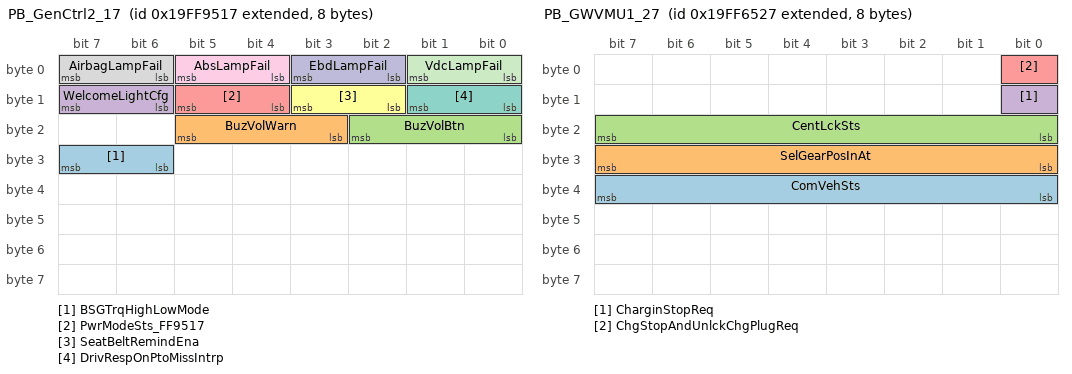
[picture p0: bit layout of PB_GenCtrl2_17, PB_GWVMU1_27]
BO_ 2583663895 PB_GenCtrl2_17: 8 ICC
 SG_ BSGTrqHighLowMode : 30|2@1+ (1,0) [0|3] ""  PCM
 SG_ BuzVolWarn : 19|3@1+ (1,0) [0|7] ""  PCM
 SG_ BuzVolBtn : 16|3@1+ (1,0) [0|7] ""  PCM
 SG_ WelcomeLightCfg : 14|2@1+ (1,0) [0|3] ""  PCM
 SG_ PwrModeSts_FF9517 : 12|2@1+ (1,0) [0|3] ""  PCM
 SG_ SeatBeltRemindEna : 10|2@1+ (1,0) [0|3] ""  PCM
 SG_ DrivRespOnPtoMissIntrp : 8|2@1+ (1,0) [0|3] ""  PCM
 SG_ AirbagLampFail : 6|2@1+ (1,0) [0|3] ""  PCM
 SG_ AbsLampFail : 4|2@1+ (1,0) [0|3] ""  PCM
 SG_ EbdLampFail : 2|2@1+ (1,0) [0|3] ""  PCM
 SG_ VdcLampFail : 0|2@1+ (1,0) [0|3] ""  PCM

BO_ 2583651623 PB_GWVMU1_27: 8 VCM
 SG_ ComVehSts : 32|8@1+ (1,0) [0|255] ""  PCM
 SG_ SelGearPosInAt : 24|8@1+ (1,0) [0|255] ""  PCM
 SG_ CentLckSts : 16|8@1+ (1,0) [0|255] ""  PCM
 SG_ CharginStopReq : 8|1@1+ (1,0) [0|1] ""  PCM
 SG_ ChgStopAndUnlckChgPlugReq : 0|1@1+ (1,0) [0|1] ""  PCM

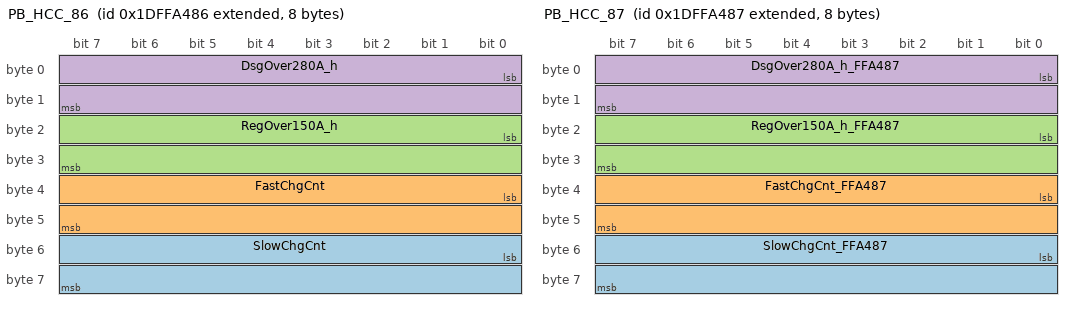
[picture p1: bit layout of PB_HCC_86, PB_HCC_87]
BO_ 2650776710 PB_HCC_86: 8 NODE_86
 SG_ SlowChgCnt : 48|16@1+ (1,0) [0|65535] ""  PCM
 SG_ FastChgCnt : 32|16@1+ (1,0) [0|65535] ""  PCM
 SG_ RegOver150A_h : 16|16@1+ (1,0) [0|65535] "h"  PCM
 SG_ DsgOver280A_h : 0|16@1+ (1,0) [0|65535] "h"  PCM

BO_ 2650776711 PB_HCC_87: 8 NODE_87
 SG_ SlowChgCnt_FFA487 : 48|16@1+ (1,0) [0|65535] ""  PCM
 SG_ FastChgCnt_FFA487 : 32|16@1+ (1,0) [0|65535] ""  PCM
 SG_ RegOver150A_h_FFA487 : 16|16@1+ (1,0) [0|65535] "h"  PCM
 SG_ DsgOver280A_h_FFA487 : 0|16@1+ (1,0) [0|65535] "h"  PCM

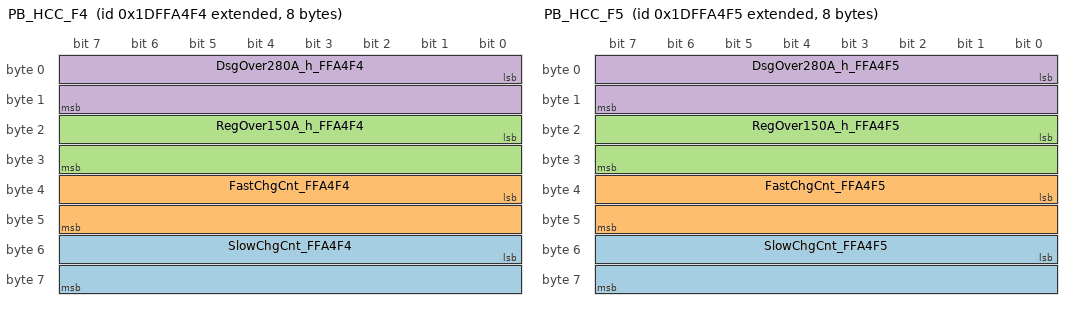
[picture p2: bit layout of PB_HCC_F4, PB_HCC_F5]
BO_ 2650776820 PB_HCC_F4: 8 NODE_F4
 SG_ SlowChgCnt_FFA4F4 : 48|16@1+ (1,0) [0|65535] ""  PCM
 SG_ FastChgCnt_FFA4F4 : 32|16@1+ (1,0) [0|65535] ""  PCM
 SG_ RegOver150A_h_FFA4F4 : 16|16@1+ (1,0) [0|65535] "h"  PCM
 SG_ DsgOver280A_h_FFA4F4 : 0|16@1+ (1,0) [0|65535] "h"  PCM

BO_ 2650776821 PB_HCC_F5: 8 NODE_F5
 SG_ SlowChgCnt_FFA4F5 : 48|16@1+ (1,0) [0|65535] ""  PCM
 SG_ FastChgCnt_FFA4F5 : 32|16@1+ (1,0) [0|65535] ""  PCM
 SG_ RegOver150A_h_FFA4F5 : 16|16@1+ (1,0) [0|65535] "h"  PCM
 SG_ DsgOver280A_h_FFA4F5 : 0|16@1+ (1,0) [0|65535] "h"  PCM

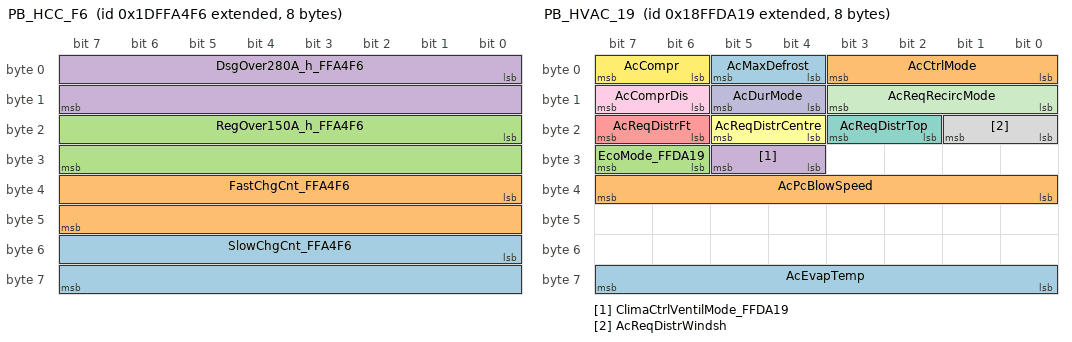
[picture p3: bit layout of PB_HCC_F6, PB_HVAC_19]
BO_ 2650776822 PB_HCC_F6: 8 NODE_F6
 SG_ SlowChgCnt_FFA4F6 : 48|16@1+ (1,0) [0|65535] ""  PCM
 SG_ FastChgCnt_FFA4F6 : 32|16@1+ (1,0) [0|65535] ""  PCM
 SG_ RegOver150A_h_FFA4F6 : 16|16@1+ (1,0) [0|65535] "h"  PCM
 SG_ DsgOver280A_h_FFA4F6 : 0|16@1+ (1,0) [0|65535] "h"  PCM

BO_ 2566904343 PB_HVAC_17: 8 ICC
 SG_ EcoMode_FFDA17 : 30|2@1+ (1,0) [0|3] ""  PCM

BO_ 2566904345 PB_HVAC_19: 8 ACM
 SG_ AcEvapTemp : 56|8@1+ (1,-40) [-40|210] "�C"  PCM
 SG_ AcPcBlowSpeed : 32|8@1+ (0.4,0) [0|100] "%"  PCM
 SG_ EcoMode_FFDA19 : 30|2@1+ (1,0) [0|3] ""  PCM
 SG_ ClimaCtrlVentilMode_FFDA19 : 28|2@1+ (1,0) [0|3] ""  PCM
 SG_ AcReqDistrFt : 22|2@1+ (1,0) [0|3] ""  PCM
 SG_ AcReqDistrCentre : 20|2@1+ (1,0) [0|3] ""  PCM
 SG_ AcReqDistrTop : 18|2@1+ (1,0) [0|3] ""  PCM
 SG_ AcReqDistrWindsh : 16|2@1+ (1,0) [0|3] ""  PCM
 SG_ AcComprDis : 14|2@1+ (1,0) [0|3] ""  PCM
 SG_ AcDurMode : 12|2@1+ (1,0) [0|3] ""  PCM
 SG_ AcReqRecircMode : 8|4@1+ (1,0) [0|15] ""  PCM
 SG_ AcCompr : 6|2@1+ (1,0) [0|3] ""  PCM
 SG_ AcMaxDefrost : 4|2@1+ (1,0) [0|3] ""  PCM
 SG_ AcCtrlMode : 0|4@1+ (1,0) [0|15] ""  PCM

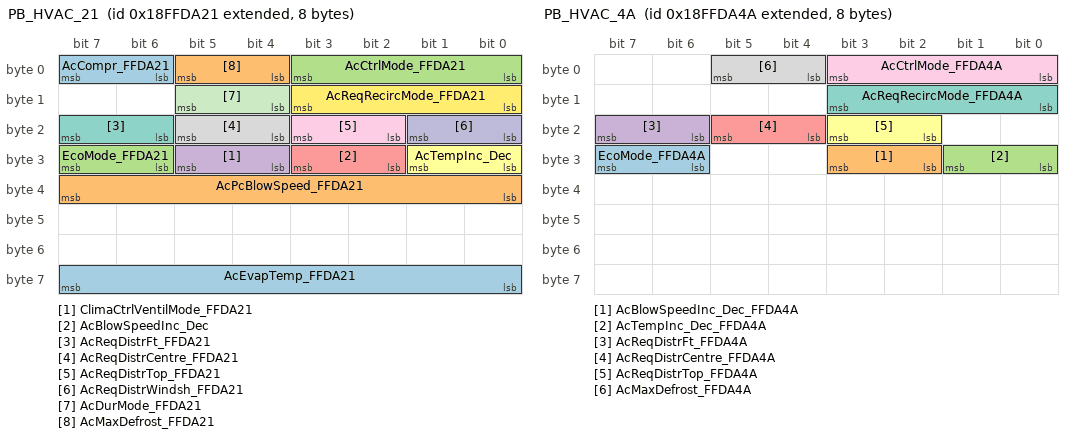
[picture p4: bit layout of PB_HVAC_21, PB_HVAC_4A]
BO_ 2566904353 PB_HVAC_21: 8 BCM
 SG_ AcEvapTemp_FFDA21 : 56|8@1+ (1,-40) [-40|210] "�C"  PCM
 SG_ AcPcBlowSpeed_FFDA21 : 32|8@1+ (0.4,0) [0|100] "%"  PCM
 SG_ EcoMode_FFDA21 : 30|2@1+ (1,0) [0|3] ""  PCM
 SG_ ClimaCtrlVentilMode_FFDA21 : 28|2@1+ (1,0) [0|3] ""  PCM
 SG_ AcBlowSpeedInc_Dec : 26|2@1+ (1,0) [0|3] ""  PCM
 SG_ AcTempInc_Dec : 24|2@1+ (1,0) [0|3] ""  PCM
 SG_ AcReqDistrFt_FFDA21 : 22|2@1+ (1,0) [0|3] ""  PCM
 SG_ AcReqDistrCentre_FFDA21 : 20|2@1+ (1,0) [0|3] ""  PCM
 SG_ AcReqDistrTop_FFDA21 : 18|2@1+ (1,0) [0|3] ""  PCM
 SG_ AcReqDistrWindsh_FFDA21 : 16|2@1+ (1,0) [0|3] ""  PCM
 SG_ AcDurMode_FFDA21 : 12|2@1+ (1,0) [0|3] ""  PCM
 SG_ AcReqRecircMode_FFDA21 : 8|4@1+ (1,0) [0|15] ""  PCM
 SG_ AcCompr_FFDA21 : 6|2@1+ (1,0) [0|3] ""  PCM
 SG_ AcMaxDefrost_FFDA21 : 4|2@1+ (1,0) [0|3] ""  PCM
 SG_ AcCtrlMode_FFDA21 : 0|4@1+ (1,0) [0|15] ""  PCM

BO_ 2566904394 PB_HVAC_4A: 8 PCM
 SG_ EcoMode_FFDA4A : 30|2@1+ (1,0) [0|3] "" Vector__XXX
 SG_ AcBlowSpeedInc_Dec_FFDA4A : 26|2@1+ (1,0) [0|3] "" Vector__XXX
 SG_ AcTempInc_Dec_FFDA4A : 24|2@1+ (1,0) [0|3] "" Vector__XXX
 SG_ AcReqDistrFt_FFDA4A : 22|2@1+ (1,0) [0|3] "" Vector__XXX
 SG_ AcReqDistrCentre_FFDA4A : 20|2@1+ (1,0) [0|3] "" Vector__XXX
 SG_ AcReqDistrTop_FFDA4A : 18|2@1+ (1,0) [0|3] "" Vector__XXX
 SG_ AcReqRecircMode_FFDA4A : 8|4@1+ (1,0) [0|15] "" Vector__XXX
 SG_ AcMaxDefrost_FFDA4A : 4|2@1+ (1,0) [0|3] "" Vector__XXX
 SG_ AcCtrlMode_FFDA4A : 0|4@1+ (1,0) [0|15] "" Vector__XXX

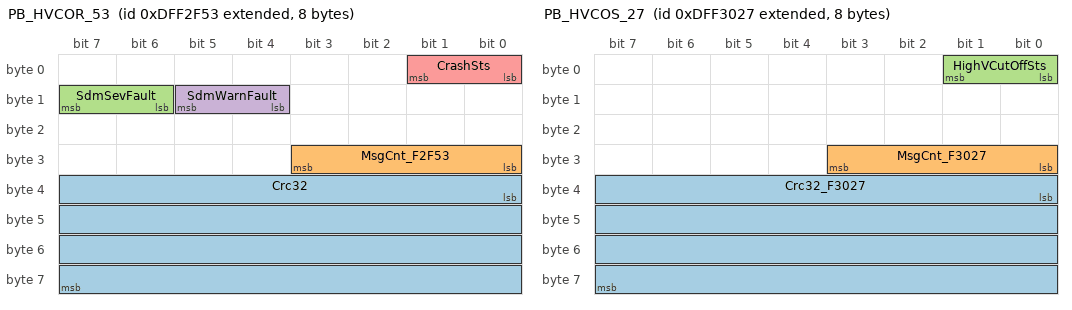
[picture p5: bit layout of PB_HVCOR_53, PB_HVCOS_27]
BO_ 2382311251 PB_HVCOR_53: 8 Airbag
 SG_ Crc32 : 32|32@1+ (1,0) [0|4294967295] ""  PCM
 SG_ MsgCnt_F2F53 : 24|4@1+ (1,0) [0|15] "count"  PCM
 SG_ SdmSevFault : 14|2@1+ (1,0) [0|3] ""  PCM
 SG_ SdmWarnFault : 12|2@1+ (1,0) [0|3] ""  PCM
 SG_ CrashSts : 0|2@1+ (1,0) [0|3] ""  PCM

BO_ 2382311463 PB_HVCOS_27: 8 VCM
 SG_ Crc32_F3027 : 32|32@1+ (1,0) [0|4294967295] ""  PCM
 SG_ MsgCnt_F3027 : 24|4@1+ (1,0) [0|15] "count"  PCM
 SG_ HighVCutOffSts : 0|2@1+ (1,0) [0|3] ""  PCM

BO_ 2650750195 PB_HVESSCFG_F3: 25 NODE_F3
 SG_ Crc32_FF3CF3 : 168|32@1+ (1,0) [0|4294967295] ""  PCM
 SG_ MsgCnt8 : 160|8@1+ (1,0) [0|255] "count"  PCM
 SG_ HvessCellVminLim : 120|8@1+ (0.02044,0) [0|5.11] "V"  PCM
 SG_ HvessCellVmaxLim : 112|8@1+ (0.02044,0) [0|5.11] "V"  PCM
 SG_ HvessRecomMinOpTemp : 96|16@1+ (0.03125,-273) [-273|1734.96875] "�C"  PCM
 SG_ HvessRecomMaxOpTemp : 80|16@1+ (0.03125,-273) [-273|1734.96875] "�C"  PCM
 SG_ HvessRecomMaxSoc : 64|16@1+ (0.0015625,0) [0|100.3984375] "%"  PCM
 SG_ HvessRecomMinSoc : 48|16@1+ (0.0015625,0) [0|100.3984375] "%"  PCM
 SG_ HvessRecomMaxOpV : 32|16@1+ (0.05,0) [0|3212.75] "V"  PCM
 SG_ HvessRecomMinOpV : 16|16@1+ (0.05,0) [0|3212.75] "V"  PCM
 SG_ HvessNomV : 0|16@1+ (0.05,0) [0|3212.75] "V"  PCM

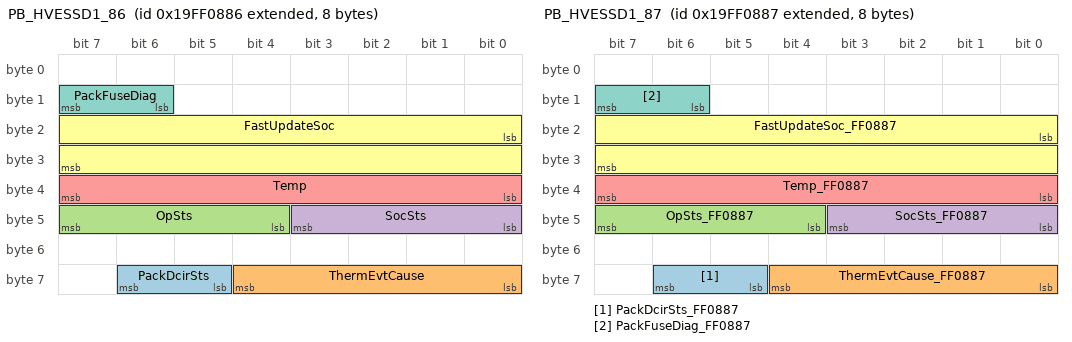
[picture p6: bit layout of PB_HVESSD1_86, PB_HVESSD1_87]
BO_ 2583627910 PB_HVESSD1_86: 8 NODE_86
 SG_ PackDcirSts : 61|2@1+ (1,0) [0|3] ""  PCM
 SG_ ThermEvtCause : 56|5@1+ (1,0) [0|31] ""  PCM
 SG_ OpSts : 44|4@1+ (1,0) [0|15] ""  PCM
 SG_ SocSts : 40|4@1+ (1,0) [0|15] ""  PCM
 SG_ Temp : 32|8@1+ (1,-40) [-40|210] "�C"  PCM
 SG_ FastUpdateSoc : 16|16@1+ (0.0015625,0) [0|100.3984375] "%"  PCM
 SG_ PackFuseDiag : 14|2@1+ (1,0) [0|3] ""  PCM

BO_ 2583627911 PB_HVESSD1_87: 8 NODE_87
 SG_ PackDcirSts_FF0887 : 61|2@1+ (1,0) [0|3] ""  PCM
 SG_ ThermEvtCause_FF0887 : 56|5@1+ (1,0) [0|31] ""  PCM
 SG_ OpSts_FF0887 : 44|4@1+ (1,0) [0|15] ""  PCM
 SG_ SocSts_FF0887 : 40|4@1+ (1,0) [0|15] ""  PCM
 SG_ Temp_FF0887 : 32|8@1+ (1,-40) [-40|210] "�C"  PCM
 SG_ FastUpdateSoc_FF0887 : 16|16@1+ (0.0015625,0) [0|100.3984375] "%"  PCM
 SG_ PackFuseDiag_FF0887 : 14|2@1+ (1,0) [0|3] ""  PCM

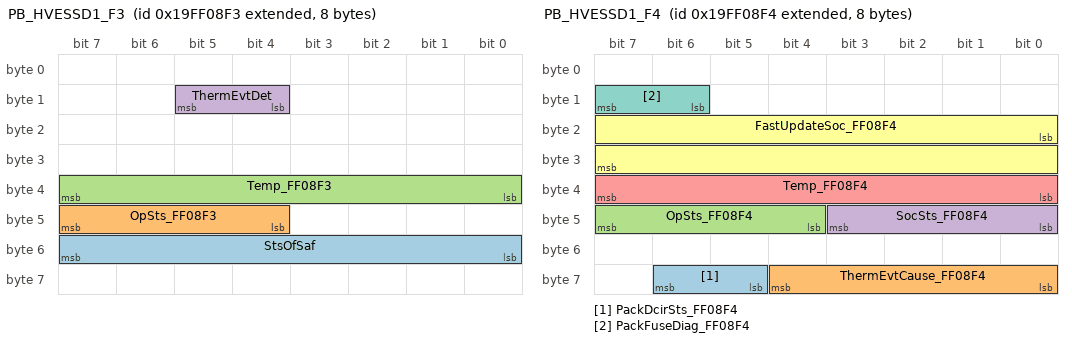
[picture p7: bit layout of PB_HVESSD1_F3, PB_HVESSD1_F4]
BO_ 2583628019 PB_HVESSD1_F3: 8 NODE_F3
 SG_ StsOfSaf : 48|8@1+ (0.4,0) [0|100] "%"  PCM
 SG_ OpSts_FF08F3 : 44|4@1+ (1,0) [0|15] ""  PCM
 SG_ Temp_FF08F3 : 32|8@1+ (1,-40) [-40|210] "�C"  PCM
 SG_ ThermEvtDet : 12|2@1+ (1,0) [0|3] ""  PCM

BO_ 2583628020 PB_HVESSD1_F4: 8 NODE_F4
 SG_ PackDcirSts_FF08F4 : 61|2@1+ (1,0) [0|3] ""  PCM
 SG_ ThermEvtCause_FF08F4 : 56|5@1+ (1,0) [0|31] ""  PCM
 SG_ OpSts_FF08F4 : 44|4@1+ (1,0) [0|15] ""  PCM
 SG_ SocSts_FF08F4 : 40|4@1+ (1,0) [0|15] ""  PCM
 SG_ Temp_FF08F4 : 32|8@1+ (1,-40) [-40|210] "�C"  PCM
 SG_ FastUpdateSoc_FF08F4 : 16|16@1+ (0.0015625,0) [0|100.3984375] "%"  PCM
 SG_ PackFuseDiag_FF08F4 : 14|2@1+ (1,0) [0|3] ""  PCM

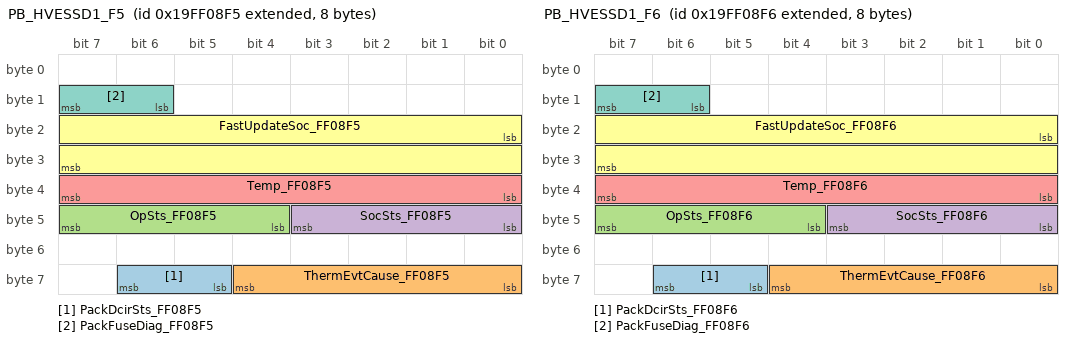
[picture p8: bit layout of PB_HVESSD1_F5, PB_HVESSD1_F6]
BO_ 2583628021 PB_HVESSD1_F5: 8 NODE_F5
 SG_ PackDcirSts_FF08F5 : 61|2@1+ (1,0) [0|3] ""  PCM
 SG_ ThermEvtCause_FF08F5 : 56|5@1+ (1,0) [0|31] ""  PCM
 SG_ OpSts_FF08F5 : 44|4@1+ (1,0) [0|15] ""  PCM
 SG_ SocSts_FF08F5 : 40|4@1+ (1,0) [0|15] ""  PCM
 SG_ Temp_FF08F5 : 32|8@1+ (1,-40) [-40|210] "�C"  PCM
 SG_ FastUpdateSoc_FF08F5 : 16|16@1+ (0.0015625,0) [0|100.3984375] "%"  PCM
 SG_ PackFuseDiag_FF08F5 : 14|2@1+ (1,0) [0|3] ""  PCM

BO_ 2583628022 PB_HVESSD1_F6: 8 NODE_F6
 SG_ PackDcirSts_FF08F6 : 61|2@1+ (1,0) [0|3] ""  PCM
 SG_ ThermEvtCause_FF08F6 : 56|5@1+ (1,0) [0|31] ""  PCM
 SG_ OpSts_FF08F6 : 44|4@1+ (1,0) [0|15] ""  PCM
 SG_ SocSts_FF08F6 : 40|4@1+ (1,0) [0|15] ""  PCM
 SG_ Temp_FF08F6 : 32|8@1+ (1,-40) [-40|210] "�C"  PCM
 SG_ FastUpdateSoc_FF08F6 : 16|16@1+ (0.0015625,0) [0|100.3984375] "%"  PCM
 SG_ PackFuseDiag_FF08F6 : 14|2@1+ (1,0) [0|3] ""  PCM

BO_ 2583628275 PB_HVESSD2_F3: 8 NODE_F3
 SG_ HvessHighVBusPasIsolTestRes : 48|16@1+ (0.1,0) [0|6425.5] "ohm per V"  PCM
 SG_ HvessAvChgPwr : 32|16@1+ (0.05,0) [0|3212.75] "kW"  PCM
 SG_ HvessAvDischPwr : 16|16@1+ (0.05,0) [0|3212.75] "kW"  PCM

BO_ 2583628531 PB_HVESSD3_F3: 8 NODE_F3
 SG_ HvessCur : 32|16@1+ (0.05,-1600) [-1600|1612.75] "A"  PCM
 SG_ HvessVLev : 16|16@1+ (0.05,0) [0|3212.75] "V"  PCM

BO_ 2583628787 PB_HVESSD4_F3: 8 NODE_F3
 SG_ HvessMaxChgVLim : 48|16@1+ (0.05,0) [0|3212.75] "V"  PCM
 SG_ HvessChgCurLim : 32|16@1+ (0.05,-1600) [-1600|1612.75] "A"  PCM
 SG_ HvessDischCurLim : 16|16@1+ (0.05,-1600) [-1600|1612.75] "A"  PCM

BO_ 2583628934 PB_HVESSHIST1_86: 8 NODE_86
 SG_ Soh : 48|8@1+ (0.4,0) [0|100] "%"  PCM
 SG_ TotEnergyTput : 16|32@1+ (1000,0) [0|4211081215000] "Watt-hour"  PCM

BO_ 2583628935 PB_HVESSHIST1_87: 8 NODE_87
 SG_ Soh_FF0C87 : 48|8@1+ (0.4,0) [0|100] "%"  PCM
 SG_ TotEnergyTput_FF0C87 : 16|32@1+ (1000,0) [0|4211081215000] "Watt-hour"  PCM

BO_ 2583629043 PB_HVESSHIST1_F3: 8 NODE_F3
 SG_ Soh_FF0CF3 : 48|8@1+ (0.4,0) [0|100] "%"  PCM
 SG_ TotEnergyTput_FF0CF3 : 16|32@1+ (1000,0) [0|4211081215000] "Watt-hour"  PCM

BO_ 2583629044 PB_HVESSHIST1_F4: 8 NODE_F4
 SG_ Soh_FF0CF4 : 48|8@1+ (0.4,0) [0|100] "%"  PCM
 SG_ TotEnergyTput_FF0CF4 : 16|32@1+ (1000,0) [0|4211081215000] "Watt-hour"  PCM

BO_ 2583629045 PB_HVESSHIST1_F5: 8 NODE_F5
 SG_ Soh_FF0CF5 : 48|8@1+ (0.4,0) [0|100] "%"  PCM
 SG_ TotEnergyTput_FF0CF5 : 16|32@1+ (1000,0) [0|4211081215000] "Watt-hour"  PCM

BO_ 2583629046 PB_HVESSHIST1_F6: 8 NODE_F6
 SG_ Soh_FF0CF6 : 48|8@1+ (0.4,0) [0|100] "%"  PCM
 SG_ TotEnergyTput_FF0CF6 : 16|32@1+ (1000,0) [0|4211081215000] "Watt-hour"  PCM

BO_ 2583629190 PB_HVESSHIST2_86: 8 NODE_86
 SG_ TotAccumChg : 16|32@1+ (100,0) [0|421108121500] "Ah"  PCM

BO_ 2583629191 PB_HVESSHIST2_87: 8 NODE_87
 SG_ TotAccumChg_FF0D87 : 16|32@1+ (100,0) [0|421108121500] "Ah"  PCM

BO_ 2583629299 PB_HVESSHIST2_F3: 8 NODE_F3
 SG_ TotAccumChg_FF0DF3 : 16|32@1+ (100,0) [0|421108121500] "Ah"  PCM

BO_ 2583629300 PB_HVESSHIST2_F4: 8 NODE_F4
 SG_ TotAccumChg_FF0DF4 : 16|32@1+ (100,0) [0|421108121500] "Ah"  PCM

BO_ 2583629301 PB_HVESSHIST2_F5: 8 NODE_F5
 SG_ TotAccumChg_FF0DF5 : 16|32@1+ (100,0) [0|421108121500] "Ah"  PCM

BO_ 2583629302 PB_HVESSHIST2_F6: 8 NODE_F6
 SG_ TotAccumChg_FF0DF6 : 16|32@1+ (100,0) [0|421108121500] "Ah"  PCM

BO_ 2634014026 PB_ICPT_4A: 58 PCM
 SG_ TxtDisCharA : 16|8@1+ (1,0) [0|255] "ASCII" Vector__XXX
 SG_ TxtCharSet : 12|4@1+ (1,0) [0|15] "" Vector__XXX
 SG_ PopupIx_FFDD4A : 0|12@1+ (1,0) [0|4095] "" Vector__XXX

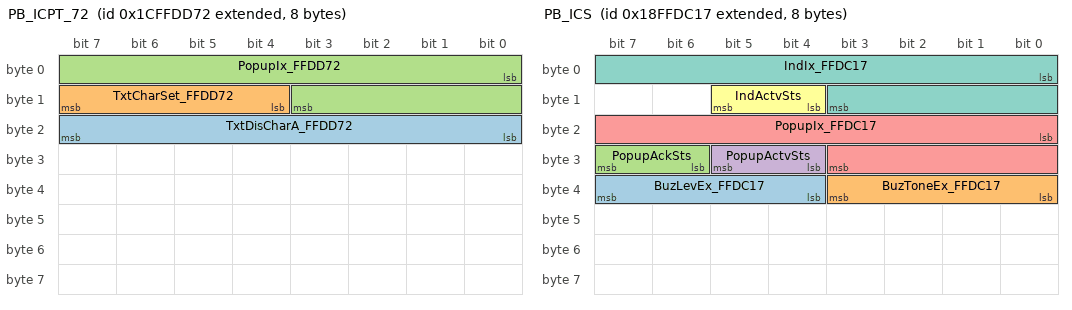
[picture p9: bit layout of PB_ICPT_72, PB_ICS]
BO_ 2634014066 PB_ICPT_72: 8 EM_PTO
 SG_ TxtDisCharA_FFDD72 : 16|8@1+ (1,0) [0|255] "ASCII"  PCM
 SG_ TxtCharSet_FFDD72 : 12|4@1+ (1,0) [0|15] ""  PCM
 SG_ PopupIx_FFDD72 : 0|12@1+ (1,0) [0|4095] ""  PCM

BO_ 2566904855 PB_ICS: 8 ICC
 SG_ BuzLevEx_FFDC17 : 36|4@1+ (1,0) [0|15] "Volume Units"  PCM
 SG_ BuzToneEx_FFDC17 : 32|4@1+ (1,0) [0|15] ""  PCM
 SG_ PopupAckSts : 30|2@1+ (1,0) [0|3] ""  PCM
 SG_ PopupActvSts : 28|2@1+ (1,0) [0|3] ""  PCM
 SG_ PopupIx_FFDC17 : 16|12@1+ (1,0) [0|4095] ""  PCM
 SG_ IndActvSts : 12|2@1+ (1,0) [0|3] ""  PCM
 SG_ IndIx_FFDC17 : 0|12@1+ (1,0) [0|4095] ""  PCM

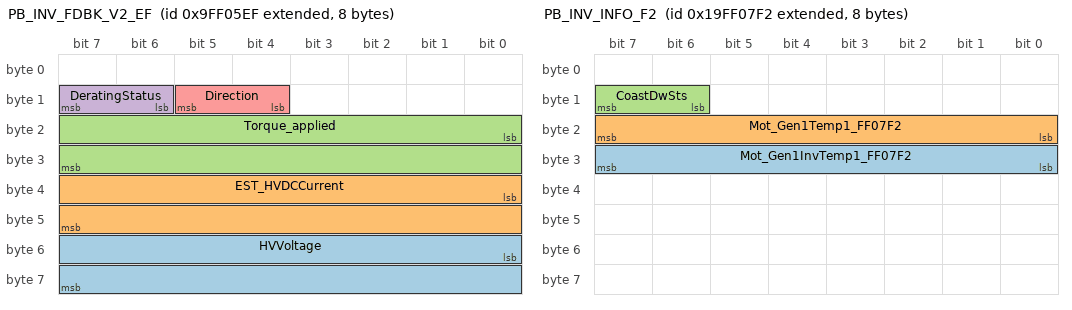
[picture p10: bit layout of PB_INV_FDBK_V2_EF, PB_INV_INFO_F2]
BO_ 2315191791 PB_INV_FDBK_V2_EF: 8 NODE_EF
 SG_ HVVoltage : 48|16@1+ (1,0) [0|65535] "V"  PCM
 SG_ EST_HVDCCurrent : 32|16@1+ (0.1,-3212.7) [-3212.7|3212.8] "A"  PCM
 SG_ Torque_applied : 16|16@1+ (0.1,-3212.7) [-3212.7|3212.8] "Nm"  PCM
 SG_ DeratingStatus : 14|2@1+ (1,0) [0|3] ""  PCM
 SG_ Direction : 12|2@1+ (1,0) [0|3] ""  PCM

BO_ 2583627762 PB_INV_INFO_F2: 8 NODE_F2
 SG_ Mot_Gen1InvTemp1_FF07F2 : 24|8@1+ (1,-40) [-40|210] "�C"  PCM
 SG_ Mot_Gen1Temp1_FF07F2 : 16|8@1+ (1,-40) [-40|210] "�C"  PCM
 SG_ CoastDwSts : 14|2@1+ (1,0) [0|3] ""  PCM

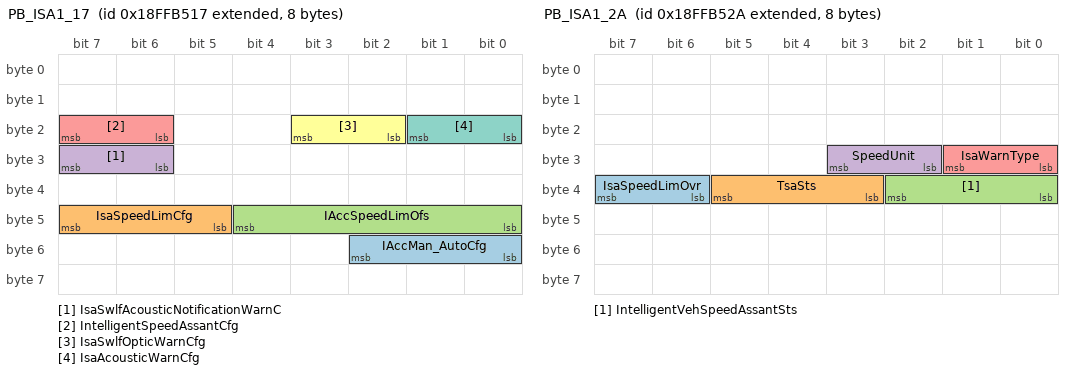
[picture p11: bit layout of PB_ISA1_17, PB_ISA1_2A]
BO_ 2566894871 PB_ISA1_17: 8 ICC
 SG_ IAccMan_AutoCfg : 48|3@1+ (1,0) [0|7] ""  PCM
 SG_ IsaSpeedLimCfg : 45|3@1+ (1,0) [0|7] ""  PCM
 SG_ IAccSpeedLimOfs : 40|5@1+ (1,-10) [-10|21] "km/h"  PCM
 SG_ IsaSwlfAcousticNotificationWarnC : 30|2@1+ (1,0) [0|3] ""  PCM
 SG_ IntelligentSpeedAssantCfg : 22|2@1+ (1,0) [0|3] ""  PCM
 SG_ IsaSwlfOpticWarnCfg : 18|2@1+ (1,0) [0|3] ""  PCM
 SG_ IsaAcousticWarnCfg : 16|2@1+ (1,0) [0|3] ""  PCM

BO_ 2566894890 PB_ISA1_2A: 8 LDW
 SG_ IsaSpeedLimOvr : 38|2@1+ (1,0) [0|3] ""  PCM
 SG_ TsaSts : 35|3@1+ (1,0) [0|7] ""  PCM
 SG_ IntelligentVehSpeedAssantSts : 32|3@1+ (1,0) [0|7] ""  PCM
 SG_ SpeedUnit : 26|2@1+ (1,0) [0|3] ""  PCM
 SG_ IsaWarnType : 24|2@1+ (1,0) [0|3] ""  PCM

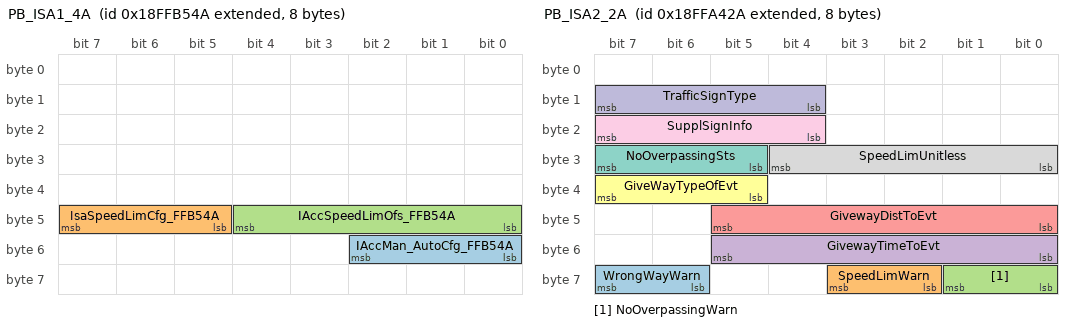
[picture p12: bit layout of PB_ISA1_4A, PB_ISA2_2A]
BO_ 2566894922 PB_ISA1_4A: 8 PCM
 SG_ IAccMan_AutoCfg_FFB54A : 48|3@1+ (1,0) [0|7] "" Vector__XXX
 SG_ IsaSpeedLimCfg_FFB54A : 45|3@1+ (1,0) [0|7] "" Vector__XXX
 SG_ IAccSpeedLimOfs_FFB54A : 40|5@1+ (1,-10) [-10|21] "km/h" Vector__XXX

BO_ 2566890538 PB_ISA2_2A: 8 LDW
 SG_ WrongWayWarn : 62|2@1+ (1,0) [0|3] ""  PCM
 SG_ SpeedLimWarn : 58|2@1+ (1,0) [0|3] ""  PCM
 SG_ NoOverpassingWarn : 56|2@1+ (1,0) [0|3] ""  PCM
 SG_ GivewayTimeToEvt : 48|6@1+ (1,0) [0|63] "s"  PCM
 SG_ GivewayDistToEvt : 40|6@1+ (1,0) [0|63] "m"  PCM
 SG_ GiveWayTypeOfEvt : 37|3@1+ (1,0) [0|7] ""  PCM
 SG_ NoOverpassingSts : 29|3@1+ (1,0) [0|7] ""  PCM
 SG_ SpeedLimUnitless : 24|5@1+ (1,0) [0|31] ""  PCM
 SG_ SupplSignInfo : 20|4@1+ (1,0) [0|15] ""  PCM
 SG_ TrafficSignType : 12|4@1+ (1,0) [0|15] ""  PCM

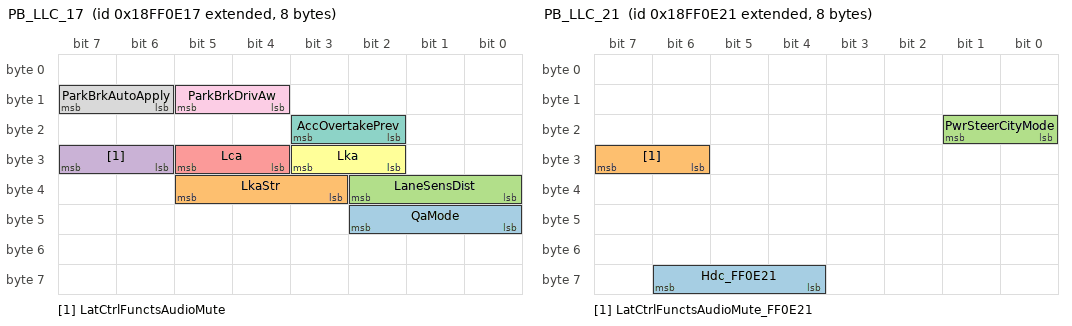
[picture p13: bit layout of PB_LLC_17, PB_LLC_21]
BO_ 2566852119 PB_LLC_17: 8 ICC
 SG_ QaMode : 40|3@1+ (1,0) [0|7] ""  PCM
 SG_ LkaStr : 35|3@1+ (1,0) [0|7] ""  PCM
 SG_ LaneSensDist : 32|3@1+ (1,0) [0|7] ""  PCM
 SG_ LatCtrlFunctsAudioMute : 30|2@1+ (1,0) [0|3] ""  PCM
 SG_ Lca : 28|2@1+ (1,0) [0|3] ""  PCM
 SG_ Lka : 26|2@1+ (1,0) [0|3] ""  PCM
 SG_ AccOvertakePrev : 18|2@1+ (1,0) [0|3] ""  PCM
 SG_ ParkBrkAutoApply : 14|2@1+ (1,0) [0|3] ""  PCM
 SG_ ParkBrkDrivAw : 12|2@1+ (1,0) [0|3] ""  PCM

BO_ 2566852129 PB_LLC_21: 8 BCM
 SG_ Hdc_FF0E21 : 60|3@1+ (1,0) [0|7] ""  PCM
 SG_ LatCtrlFunctsAudioMute_FF0E21 : 30|2@1+ (1,0) [0|3] ""  PCM
 SG_ PwrSteerCityMode : 16|2@1+ (1,0) [0|3] ""  PCM

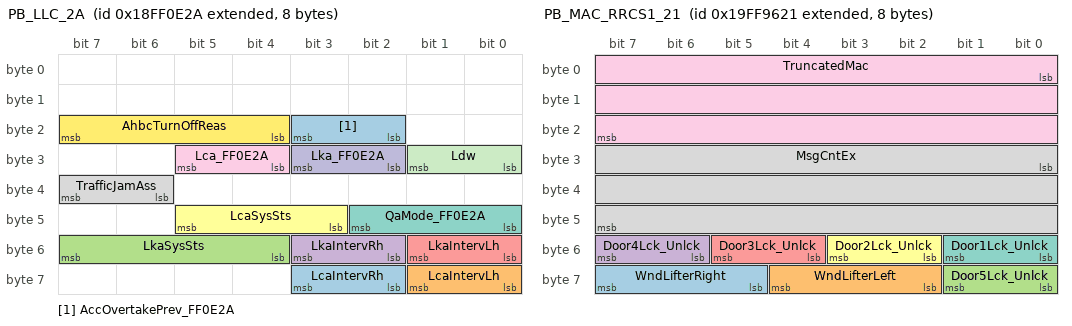
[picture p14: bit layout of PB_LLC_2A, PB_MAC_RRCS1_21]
BO_ 2566852138 PB_LLC_2A: 8 LDW
 SG_ LcaIntervRh : 58|2@1+ (1,0) [0|3] ""  PCM
 SG_ LcaIntervLh : 56|2@1+ (1,0) [0|3] ""  PCM
 SG_ LkaSysSts : 52|4@1+ (1,0) [0|15] ""  PCM
 SG_ LkaIntervRh : 50|2@1+ (1,0) [0|3] ""  PCM
 SG_ LkaIntervLh : 48|2@1+ (1,0) [0|3] ""  PCM
 SG_ LcaSysSts : 43|3@1+ (1,0) [0|7] ""  PCM
 SG_ QaMode_FF0E2A : 40|3@1+ (1,0) [0|7] ""  PCM
 SG_ TrafficJamAss : 38|2@1+ (1,0) [0|3] ""  PCM
 SG_ Lca_FF0E2A : 28|2@1+ (1,0) [0|3] ""  PCM
 SG_ Lka_FF0E2A : 26|2@1+ (1,0) [0|3] ""  PCM
 SG_ Ldw : 24|2@1+ (1,0) [0|3] ""  PCM
 SG_ AhbcTurnOffReas : 20|4@1+ (1,0) [0|15] ""  PCM
 SG_ AccOvertakePrev_FF0E2A : 18|2@1+ (1,0) [0|3] ""  PCM

BO_ 2583664161 PB_MAC_RRCS1_21: 8 BCM
 SG_ WndLifterRight : 61|3@1+ (1,0) [0|7] ""  PCM
 SG_ WndLifterLeft : 58|3@1+ (1,0) [0|7] ""  PCM
 SG_ Door5Lck_Unlck : 56|2@1+ (1,0) [0|3] ""  PCM
 SG_ Door4Lck_Unlck : 54|2@1+ (1,0) [0|3] ""  PCM
 SG_ Door3Lck_Unlck : 52|2@1+ (1,0) [0|3] ""  PCM
 SG_ Door2Lck_Unlck : 50|2@1+ (1,0) [0|3] ""  PCM
 SG_ Door1Lck_Unlck : 48|2@1+ (1,0) [0|3] ""  PCM
 SG_ MsgCntEx : 24|24@1+ (1,0) [0|16777215] "count"  PCM
 SG_ TruncatedMac : 0|24@1+ (1,0) [0|16777215] ""  PCM

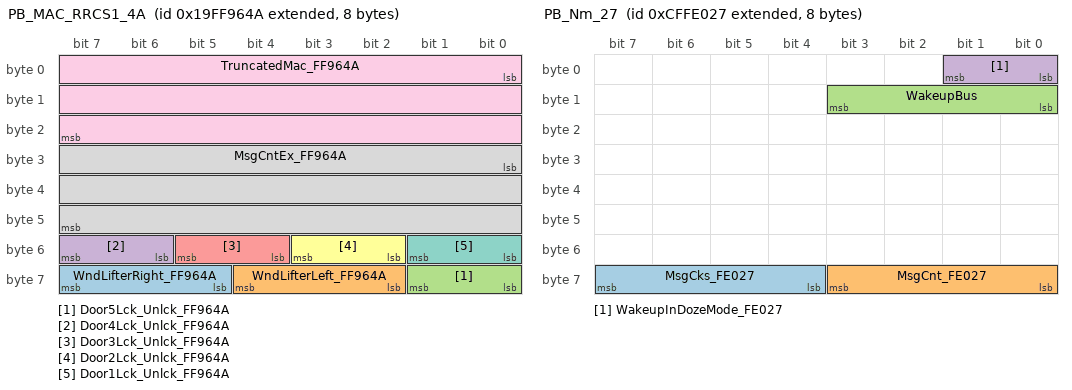
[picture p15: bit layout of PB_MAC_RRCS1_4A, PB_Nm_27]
BO_ 2583664202 PB_MAC_RRCS1_4A: 8 PCM
 SG_ WndLifterRight_FF964A : 61|3@1+ (1,0) [0|7] "" Vector__XXX
 SG_ WndLifterLeft_FF964A : 58|3@1+ (1,0) [0|7] "" Vector__XXX
 SG_ Door5Lck_Unlck_FF964A : 56|2@1+ (1,0) [0|3] "" Vector__XXX
 SG_ Door4Lck_Unlck_FF964A : 54|2@1+ (1,0) [0|3] "" Vector__XXX
 SG_ Door3Lck_Unlck_FF964A : 52|2@1+ (1,0) [0|3] "" Vector__XXX
 SG_ Door2Lck_Unlck_FF964A : 50|2@1+ (1,0) [0|3] "" Vector__XXX
 SG_ Door1Lck_Unlck_FF964A : 48|2@1+ (1,0) [0|3] "" Vector__XXX
 SG_ MsgCntEx_FF964A : 24|24@1+ (1,0) [0|16777215] "count" Vector__XXX
 SG_ TruncatedMac_FF964A : 0|24@1+ (1,0) [0|16777215] "" Vector__XXX

BO_ 2583664417 PB_MAC_RRCS2_21: 8 BCM
 SG_ CrkEnaReq : 48|2@1+ (1,0) [0|3] ""  PCM
 SG_ MsgCntEx_FF9721 : 24|24@1+ (1,0) [0|16777215] "count"  PCM
 SG_ TruncatedMac_FF9721 : 0|24@1+ (1,0) [0|16777215] ""  PCM

BO_ 2583664458 PB_MAC_RRCS2_4A: 8 PCM
 SG_ CrkEnaReq_FF974A : 48|2@1+ (1,0) [0|3] "" Vector__XXX
 SG_ MsgCntEx_FF974A : 24|24@1+ (1,0) [0|16777215] "count" Vector__XXX
 SG_ TruncatedMac_FF974A : 0|24@1+ (1,0) [0|16777215] "" Vector__XXX

BO_ 2365579287 PB_Nm_17: 8 ICC
 SG_ WakeupInDozeMode : 0|2@1+ (1,0) [0|3] ""  PCM

BO_ 2365579303 PB_Nm_27: 8 VCM
 SG_ MsgCks_FE027 : 60|4@1+ (1,0) [0|15] "count"  PCM
 SG_ MsgCnt_FE027 : 56|4@1+ (1,0) [0|15] "count"  PCM
 SG_ WakeupBus : 8|4@1+ (1,0) [0|15] ""  PCM
 SG_ WakeupInDozeMode_FE027 : 0|2@1+ (1,0) [0|3] ""  PCM

BO_ 2365579329 PB_Nm_41: 8 NIS_RDR
 SG_ WakeupInDozeMode_FE041 : 0|2@1+ (1,0) [0|3] ""  PCM

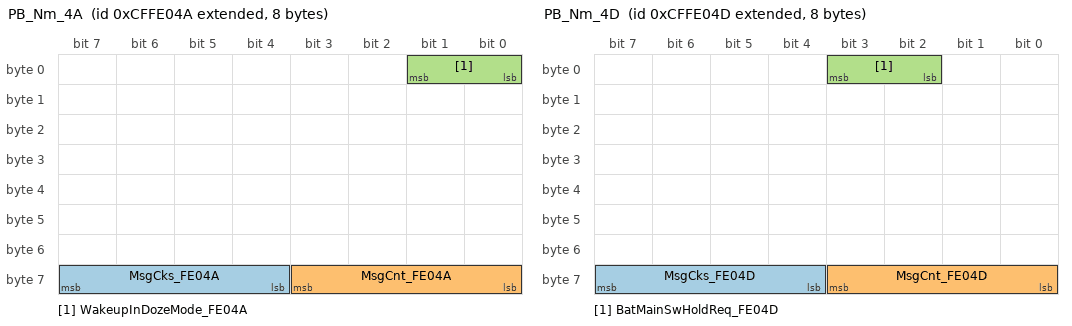
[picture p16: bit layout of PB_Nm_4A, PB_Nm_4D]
BO_ 2365579338 PB_Nm_4A: 8 PCM
 SG_ MsgCks_FE04A : 60|4@1+ (1,0) [0|15] "count" Vector__XXX
 SG_ MsgCnt_FE04A : 56|4@1+ (1,0) [0|15] "count" Vector__XXX
 SG_ WakeupInDozeMode_FE04A : 0|2@1+ (1,0) [0|3] "" Vector__XXX

BO_ 2365579341 PB_Nm_4D: 8 SCU
 SG_ MsgCks_FE04D : 60|4@1+ (1,0) [0|15] "count"  PCM
 SG_ MsgCnt_FE04D : 56|4@1+ (1,0) [0|15] "count"  PCM
 SG_ BatMainSwHoldReq_FE04D : 2|2@1+ (1,0) [0|3] ""  PCM

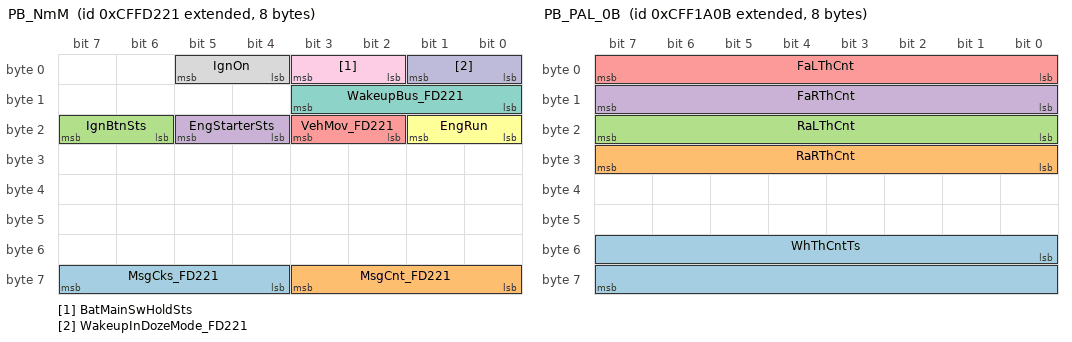
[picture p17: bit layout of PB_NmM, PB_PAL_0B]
BO_ 2365575713 PB_NmM: 8 BCM
 SG_ MsgCks_FD221 : 60|4@1+ (1,0) [0|15] "count"  PCM
 SG_ MsgCnt_FD221 : 56|4@1+ (1,0) [0|15] "count"  PCM
 SG_ IgnBtnSts : 22|2@1+ (1,0) [0|3] ""  PCM
 SG_ EngStarterSts : 20|2@1+ (1,0) [0|3] ""  PCM
 SG_ VehMov_FD221 : 18|2@1+ (1,0) [0|3] ""  PCM
 SG_ EngRun : 16|2@1+ (1,0) [0|3] ""  PCM
 SG_ WakeupBus_FD221 : 8|4@1+ (1,0) [0|15] ""  PCM
 SG_ IgnOn : 4|2@1+ (1,0) [0|3] ""  PCM
 SG_ BatMainSwHoldSts : 2|2@1+ (1,0) [0|3] ""  PCM
 SG_ WakeupInDozeMode_FD221 : 0|2@1+ (1,0) [0|3] ""  PCM

BO_ 2365528587 PB_PAL_0B: 8 BSM
 SG_ WhThCntTs : 48|16@1+ (10,0) [0|655340] "�s"  PCM
 SG_ RaRThCnt : 24|8@1+ (1,0) [0|254] "count"  PCM
 SG_ RaLThCnt : 16|8@1+ (1,0) [0|254] "count"  PCM
 SG_ FaRThCnt : 8|8@1+ (1,0) [0|254] "count"  PCM
 SG_ FaLThCnt : 0|8@1+ (1,0) [0|254] "count"  PCM

BO_ 2566891593 PB_PbcToVmu1_49: 8 NODE_49
 SG_ WOBC_Power : 32|16@1+ (0.05,0) [0|48] "kW"  PCM
 SG_ WOBC_MaxAvailablePower : 16|16@1+ (0.05,0) [0|48] "kW"  PCM
 SG_ WOBC_MaxAvailableIout : 0|16@1+ (0.05,0) [0|100] "A"  PCM

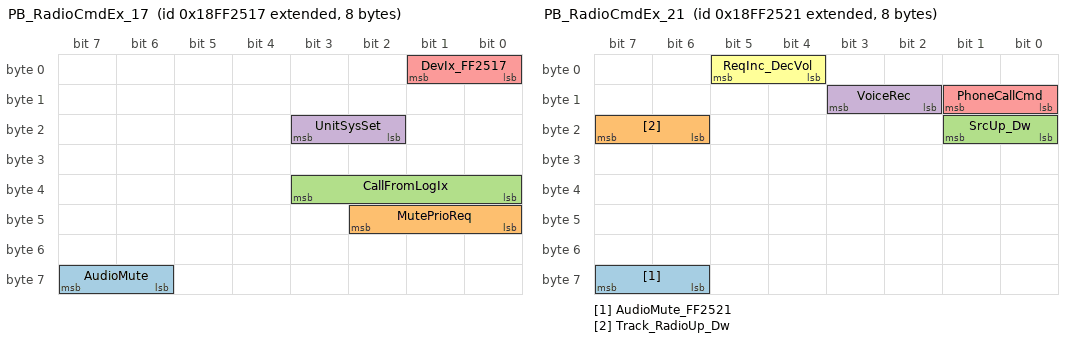
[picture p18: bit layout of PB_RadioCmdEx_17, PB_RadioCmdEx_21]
BO_ 2566858007 PB_RadioCmdEx_17: 8 ICC
 SG_ AudioMute : 62|2@1+ (1,0) [0|3] ""  PCM
 SG_ MutePrioReq : 40|3@1+ (1,0) [0|7] ""  PCM
 SG_ CallFromLogIx : 32|4@1+ (1,0) [0|15] ""  PCM
 SG_ UnitSysSet : 18|2@1+ (1,0) [0|3] ""  PCM
 SG_ DevIx_FF2517 : 0|2@1+ (1,0) [0|3] ""  PCM

BO_ 2566858017 PB_RadioCmdEx_21: 8 BCM
 SG_ AudioMute_FF2521 : 62|2@1+ (1,0) [0|3] ""  PCM
 SG_ Track_RadioUp_Dw : 22|2@1+ (1,0) [0|3] ""  PCM
 SG_ SrcUp_Dw : 16|2@1+ (1,0) [0|3] ""  PCM
 SG_ VoiceRec : 10|2@1+ (1,0) [0|3] ""  PCM
 SG_ PhoneCallCmd : 8|2@1+ (1,0) [0|3] ""  PCM
 SG_ ReqInc_DecVol : 4|2@1+ (1,0) [0|3] ""  PCM

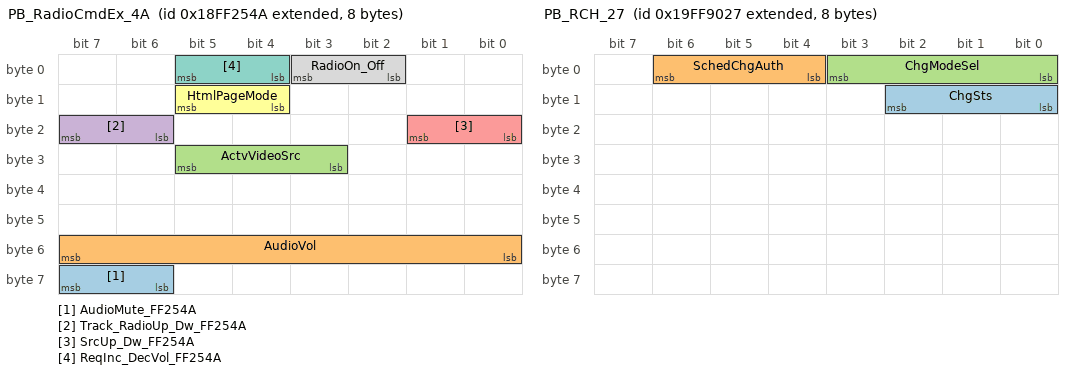
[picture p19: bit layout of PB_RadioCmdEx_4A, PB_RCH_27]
BO_ 2566858058 PB_RadioCmdEx_4A: 8 PCM
 SG_ AudioMute_FF254A : 62|2@1+ (1,0) [0|3] "" Vector__XXX
 SG_ AudioVol : 48|8@1+ (1,0) [0|250] "" Vector__XXX
 SG_ ActvVideoSrc : 27|3@1+ (1,0) [0|7] "" Vector__XXX
 SG_ Track_RadioUp_Dw_FF254A : 22|2@1+ (1,0) [0|3] "" Vector__XXX
 SG_ SrcUp_Dw_FF254A : 16|2@1+ (1,0) [0|3] "" Vector__XXX
 SG_ HtmlPageMode : 12|2@1+ (1,0) [0|3] "" Vector__XXX
 SG_ ReqInc_DecVol_FF254A : 4|2@1+ (1,0) [0|3] "" Vector__XXX
 SG_ RadioOn_Off : 2|2@1+ (1,0) [0|3] "" Vector__XXX

BO_ 2566897729 PB_RadioDisEx: 67 NIS_RDR
 SG_ TxtDis : 8|8@1+ (1,0) [0|255] "ASCII"  PCM
 SG_ DevIx_FFC041 : 0|2@1+ (1,0) [0|3] ""  PCM

BO_ 2566857793 PB_RadioStsEx_41: 8 NIS_RDR
 SG_ DevIx_FF2441 : 61|2@1+ (1,0) [0|3] ""  PCM
 SG_ ActvVideoSrc_FF2441 : 58|3@1+ (1,0) [0|7] ""  PCM
 SG_ HtmlPageMode_FF2441 : 56|2@1+ (1,0) [0|3] ""  PCM
 SG_ AudioVol_FF2441 : 48|8@1+ (1,0) [0|250] ""  PCM
 SG_ AudioMute_FF2441 : 46|2@1+ (1,0) [0|3] ""  PCM
 SG_ ActvSrcEx : 40|6@1+ (1,0) [0|62] ""  PCM
 SG_ RadioDotDis : 31|1@1+ (1,0) [0|1] ""  PCM
 SG_ RadioColonDis : 30|1@1+ (1,0) [0|1] ""  PCM
 SG_ PhoneCallIn_Out : 28|2@1+ (1,0) [0|3] ""  PCM
 SG_ PhoneCallHeld : 26|2@1+ (1,0) [0|3] ""  PCM
 SG_ PhoneCallActv : 24|2@1+ (1,0) [0|3] ""  PCM
 SG_ Mix : 22|1@1+ (1,0) [0|1] ""  PCM
 SG_ Rpt : 21|1@1+ (1,0) [0|1] ""  PCM
 SG_ UnitSysSet_FF2441 : 18|2@1+ (1,0) [0|3] ""  PCM
 SG_ CdSym : 17|1@1+ (1,0) [0|1] ""  PCM
 SG_ MsgSts : 14|2@1+ (1,0) [0|3] ""  PCM
 SG_ AudioPause : 12|2@1+ (1,0) [0|3] ""  PCM
 SG_ ManSymLoudnessOn : 11|1@1+ (1,0) [0|1] ""  PCM
 SG_ LoSym : 10|1@1+ (1,0) [0|1] ""  PCM
 SG_ AfSym : 9|1@1+ (1,0) [0|1] ""  PCM
 SG_ TaSym : 8|1@1+ (1,0) [0|1] ""  PCM
 SG_ DevMic : 6|2@1+ (1,0) [0|3] ""  PCM
 SG_ InfotainmentSysSts : 2|3@1+ (1,0) [0|7] ""  PCM
 SG_ FmISym : 1|1@1+ (1,0) [0|1] ""  PCM

BO_ 2583662631 PB_RCH_27: 8 VCM
 SG_ ChgSts : 8|3@1+ (1,0) [0|7] ""  PCM
 SG_ SchedChgAuth : 4|3@1+ (1,0) [0|7] ""  PCM
 SG_ ChgModeSel : 0|4@1+ (1,0) [0|15] ""  PCM

BO_ 2583662666 PB_RCH_4A: 8 PCM
 SG_ SchedChgAuth_FF904A : 4|3@1+ (1,0) [0|7] "" Vector__XXX

BO_ 2583666250 PB_RemoteRequest_4A: 8 PCM
 SG_ ExtChgCurLineLim : 0|8@1+ (0.25,0) [0|62.5] "A" Vector__XXX

BO_ 2566910497 PB_RER_21: 8 BCM
 SG_ DeratingReq : 12|2@1+ (1,0) [0|3] ""  PCM

BO_ 2650776966 PB_ROC_86: 16 NODE_86
 SG_ NegRelayCounterAbove500 : 120|8@1+ (1,0) [0|255] ""  PCM
 SG_ PosRelayCounterAbove500 : 112|8@1+ (1,0) [0|255] ""  PCM
 SG_ NegRelayCounter400_500 : 104|8@1+ (1,0) [0|255] ""  PCM
 SG_ PosRelayCounter400_500 : 96|8@1+ (1,0) [0|255] ""  PCM
 SG_ NegRelayCounter250_400 : 88|8@1+ (1,0) [0|255] ""  PCM
 SG_ PosRelayCounter250_400 : 80|8@1+ (1,0) [0|255] ""  PCM
 SG_ NegRelayCounter50_250 : 64|16@1+ (1,0) [0|65535] ""  PCM
 SG_ PosRelayCounter50_250 : 48|16@1+ (1,0) [0|65535] ""  PCM
 SG_ NegRelayCounter : 32|16@1+ (1,0) [0|65535] ""  PCM
 SG_ PosRelayCounter : 16|16@1+ (1,0) [0|65535] ""  PCM
 SG_ PreRelayCounter : 0|16@1+ (1,0) [0|65535] ""  PCM

CM_ SG_ 2566904345 AcCompr "- A/C Compressor request when Automatic Climate present";
CM_ SG_ 2566904353 AcPcBlowSpeed_FFDA21 "- For IC Programmed Ventilation";
CM_ SG_ 2566904353 AcCompr_FFDA21 "- A/C Compressor status (if available) with any Climate Systems";
CM_ BO_ 2566904394 "- For KeyOn functionality";
CM_ BO_ 2634014026 "- Multipacket message handled by SAE Transport Protocol (J1939/21, par 5.10, Multipacket Broadcast with TP.CM/BAM, TP.DT)";
CM_ SG_ 2634014026 PopupIx_FFDD4A "- Index 1 to 8 reserved for EM";
CM_ BO_ 2634014066 "- EM transmit each PLC cycle the popup texts 01 to 10, after having received once the SERV_17 message
-  EM.C.EM.Pto.19.L. each PLC cycle the popup texts from 01 to 06 chars";
CM_ SG_ 2634014066 PopupIx_FFDD72 "- Index 9 to 16 reserved for RadioNav";
CM_ BO_ 2566904855 "- Apply to selected IC information
-  Sent at change of one of the message signals but no faster than every 100 ms";
CM_ SG_ 2566904855 PopupAckSts "- 00b when the popup activate, 01b if user press Cancel, 10 if popup end by timeout";
CM_ SG_ 2566904855 PopupActvSts "- 01b when the popup is requested, 00b when popup is off";
CM_ SG_ 2566852119 QaMode "- Used values: 0x0 (Disabled), 0x1 (Enabled), 0x7 (Not available / Do not change)";
CM_ SG_ 2566852119 LatCtrlFunctsAudioMute "- 00 = Buzzer Off ; 01 = Buzzer On";
CM_ SG_ 2566852129 LatCtrlFunctsAudioMute_FF0E21 "- 00 = Button Not Pressed; 01 = Button Pressed";
CM_ SG_ 2566852138 AhbcTurnOffReas "- For Debug Only";
CM_ BO_ 2583664161 "- To be sent for an EOL parameter time";
CM_ SG_ 2583664161 Door5Lck_Unlck "- Hinged/Rear Door";
CM_ SG_ 2583664161 Door4Lck_Unlck "- Lateral Door Passenger Side/Roto Door";
CM_ SG_ 2583664161 Door3Lck_Unlck "- Lateral Door Driver Side";
CM_ SG_ 2583664161 Door2Lck_Unlck "- Passenger Door";
CM_ SG_ 2583664161 Door1Lck_Unlck "- Driver Door";
CM_ BO_ 2583664202 "- To be sent for an EOL parameter time";
CM_ SG_ 2583664202 Door5Lck_Unlck_FF964A "- Hinged/Rear Door";
CM_ SG_ 2583664202 Door4Lck_Unlck_FF964A "- Lateral Door Passenger Side/Roto Door";
CM_ SG_ 2583664202 Door3Lck_Unlck_FF964A "- Lateral Door Driver Side";
CM_ SG_ 2583664202 Door2Lck_Unlck_FF964A "- Passenger Door";
CM_ SG_ 2583664202 Door1Lck_Unlck_FF964A "- Driver Door";
CM_ BO_ 2365579287 "- Faster Transmission Rate till wakeup (2s max), then every 1s when active
-  Wake-up requests priority order is (higher to lower) IgnOn, WakeupInDozeMode, BatMainSwHoldReq; a delay (like 2s) shall be implemented when switching from an higher to a lower priority state";
CM_ SG_ 2365579287 WakeupInDozeMode "- Only the necessary functionalities at Ignition Off are performed. CAN transmission is active, the set of transmitted message maybe reduced as needed. (Iveco 18-2253 par. 3.6.2.4)
-  Diagnostic allowed in Doze mode";
CM_ BO_ 2365579303 "- Faster Transmission Rate till wakeup (2s max), then every 1s when active
-  Wake-up requests priority order is (higher to lower) IgnOn, WakeupInDozeMode, BatMainSwHoldReq; a delay (like 2s) shall be implemented when switching from an higher to a lower priority state";
CM_ SG_ 2365579303 MsgCks_FE027 "- Only used in case of safety relevant functionalities";
CM_ SG_ 2365579303 MsgCnt_FE027 "- Only used in case of safety relevant functionalities";
CM_ SG_ 2365579303 WakeupInDozeMode_FE027 "- Only the necessary functionalities at Ignition Off are performed. CAN transmission is active, the set of transmitted message maybe reduced as needed. (Iveco 18-2253 par. 3.6.2.4)
-  Diagnostic allowed in Doze mode";
CM_ BO_ 2365579338 "- Faster Transmission Rate till wakeup (2s max), then every 1s when active
-  Wake-up requests priority order is (higher to lower) IgnOn, WakeupInDozeMode, BatMainSwHoldReq; a delay (like 2s) shall be implemented when switching from an higher to a lower priority state";
CM_ SG_ 2365579338 MsgCks_FE04A "- Only used in case of safety relevant functionalities";
CM_ SG_ 2365579338 MsgCnt_FE04A "- Only used in case of safety relevant functionalities";
CM_ SG_ 2365579338 WakeupInDozeMode_FE04A "- Only the necessary functionalities at Ignition Off are performed. CAN transmission is active, the set of transmitted message maybe reduced as needed. (Iveco 18-2253 par. 3.6.2.4)
-  Diagnostic allowed in Doze mode";
CM_ BO_ 2365579341 "- Faster Transmission Rate till wakeup (2s max), then every 1s when active
-  Wake-up requests priority order is (higher to lower) IgnOn, WakeupInDozeMode, BatMainSwHoldReq; a delay (like 2s) shall be implemented when switching from an higher to a lower priority state";
CM_ SG_ 2365579341 MsgCks_FE04D "- Only used in case of safety relevant functionalities";
CM_ SG_ 2365579341 MsgCnt_FE04D "- Only used in case of safety relevant functionalities";
CM_ BO_ 2365575713 "- Faster Transmission Rate till wakeup (2s max), then every 1s when active
-  First message to be sent, as soon as possible";
CM_ SG_ 2365575713 MsgCks_FD221 "- Only used in case of safety relevant functionalities";
CM_ SG_ 2365575713 MsgCnt_FD221 "- Only used in case of safety relevant functionalities";
CM_ SG_ 2365575713 WakeupInDozeMode_FD221 "- Only the necessary functionalities at Ignition Off are performed. CAN transmission is active, the set of transmitted message maybe reduced as needed. (Iveco 18-2253 par. 3.6.2.4)
-  Diagnostic allowed in Doze mode";
CM_ BO_ 2566858007 "- All the signals of this message are set (to a value different to No Action / Not Valid) for 1 cycle after the command is being activated
-  For each signal only the first of a continuos sequence of commands having the same value shall be accepted";
CM_ SG_ 2566858007 AudioMute "- Set to 11b if no request";
CM_ BO_ 2566858017 "- All the signals of this message are set (to a value different to No Action / Not Valid) for 1 cycle after the command is being activated
-  For each signal only the first of a continuos sequence of commands having the same value shall be accepted";
CM_ SG_ 2566858017 AudioMute_FF2521 "- Set to 11b if Button Not Pressed";
CM_ SG_ 2566858017 Track_RadioUp_Dw "- CD/Radio device to use it for Radio Preset Station (or Seek Frequency Tune) Up/Down when Radio source active or as Track Up/Down (fast forward / rewind) with other sources
-  Request set during the whole key press, time duration interpreted by the CD/Radio
-  Set to 11b if Button Not Pressed";
CM_ SG_ 2566858017 SrcUp_Dw "- Request set during the whole key press, time duration interpreted by the CD/Radio
-  Set to 11b if Button Not Pressed";
CM_ SG_ 2566858017 VoiceRec "- Set to 11b if Button Not Pressed";
CM_ SG_ 2566858017 ReqInc_DecVol "- Set to 11b if Button Not Pressed";
CM_ BO_ 2566858058 "- All the signals of this message are set (to a value different to No Action / Not Valid) for 1 cycle after the command is being activated
-  For each signal only the first of a continuos sequence of commands having the same value shall be accepted
-  TransmissionRate=50ms when used as Infotainment wakeup, for 2s max at startup";
CM_ SG_ 2566858058 AudioMute_FF254A "- Set to 11b if no request";
CM_ SG_ 2566858058 Track_RadioUp_Dw_FF254A "- CD/Radio device to use it for Radio Preset Station (or Seek Frequency Tune) Up/Down when Radio source active or as Track Up/Down (fast forward / rewind) with other sources
-  Request set during the whole key press, time duration interpreted by the CD/Radio";
CM_ SG_ 2566858058 SrcUp_Dw_FF254A "- Request set during the whole key press, time duration interpreted by the CD/Radio";
CM_ SG_ 2566858058 RadioOn_Off "- Used on MY24";
CM_ BO_ 2566897729 "- Multipacket message handled by SAE Transport Protocol (J1939/21, par 5.10, Multipacket Broadcast with TP.CM/BAM, TP.DT)
-  Variable Message Length, maximum value used for dbc generation";
CM_ SG_ 2566897729 TxtDis "- Variable signal length, 8 bits used for dbc generation only";
CM_ BO_ 2566857793 "- Transmitted every 1s and on change of state but no faster than every 100 ms";
CM_ SG_ 2566857793 CdSym "- For current systems compatibility only, use Active Source (Extended) for new design";
CM_ SG_ 2566857793 FmISym "- For current systems compatibility only, use Active Source (Extended) for new design";
CM_ BO_ 2583662631 "- As Needed trasmission mode when in Key Off";
BA_DEF_ BO_  "CI_MsgDefinition" STRING ;
BA_DEF_ BO_  "CI_MsgId" INT 0 2147483647;
BA_DEF_ BO_  "CI_MsgName" STRING ;
BA_DEF_ BO_  "GenMsgCycleTime" INT 0 3600000;
BA_DEF_ BO_  "GenMsgCycleTimeFast" INT 0 3600000;
BA_DEF_ BO_  "GenMsgDelayTime" INT 0 3600000;
BA_DEF_ BO_  "GenMsgILSupport" ENUM  "No","Yes";
BA_DEF_ BO_  "GenMsgNrOfRepetition" INT 0 1000000;
BA_DEF_ BO_  "GenMsgRequestable" INT 0 1;
BA_DEF_ BO_  "GenMsgSendType" ENUM  "cyclic","NotUsed","NotUsed","NotUsed","NotUsed","NotUsed","NotUsed","IfActive","noMsgSendType";
BA_DEF_ BO_  "GenMsgStartDelayTime" INT 0 100000;
BA_DEF_ BO_  "TpJ1939VarDlc" ENUM  "No","Yes";
BA_DEF_ BO_  "VFrameFormat" ENUM  "StandardCAN","ExtendedCAN","reserved","J1939PG";
BA_DEF_ SG_  "CI_ParId" STRING ;
BA_DEF_ SG_  "CI_SigId" INT 0 2147483647;
BA_DEF_ SG_  "CI_SigName" STRING ;
BA_DEF_ SG_  "GenSigEVName" STRING ;
BA_DEF_ SG_  "GenSigILSupport" ENUM  "No","Yes";
BA_DEF_ SG_  "GenSigInactiveValue" INT 0 2147483647;
BA_DEF_ SG_  "GenSigSendType" ENUM  "Cyclic","OnWrite","OnWriteWithRepetition","OnChange","OnChangeWithRepetition","IfActive","IfActiveWithRepetition","NoSigSendType";
BA_DEF_ SG_  "GenSigStartValue" INT 0 2147483647;
BA_DEF_ SG_  "GenSigTimeoutTime_PCM" INT 0 3600000;
BA_DEF_ SG_  "GenSigTimeoutTime_SGW" INT 0 3600000;
BA_DEF_ SG_  "SPN" INT 0 524287;
BA_DEF_ SG_  "SigType" ENUM  "Default","Range","RangeSigned","ASCII","Discrete","Control","ReferencePGN","DTC","StringDelimiter","StringLength","StringLengthControl";
BA_DEF_DEF_  "CI_MsgDefinition" "";
BA_DEF_DEF_  "CI_MsgId" 0;
BA_DEF_DEF_  "CI_MsgName" "";
BA_DEF_DEF_  "GenMsgCycleTime" 0;
BA_DEF_DEF_  "GenMsgCycleTimeFast" 0;
BA_DEF_DEF_  "GenMsgDelayTime" 1;
BA_DEF_DEF_  "GenMsgILSupport" "Yes";
BA_DEF_DEF_  "GenMsgNrOfRepetition" 0;
BA_DEF_DEF_  "GenMsgRequestable" 0;
BA_DEF_DEF_  "GenMsgSendType" "noMsgSendType";
BA_DEF_DEF_  "GenMsgStartDelayTime" 0;
BA_DEF_DEF_  "TpJ1939VarDlc" "No";
BA_DEF_DEF_  "VFrameFormat" "J1939PG";
BA_DEF_DEF_  "CI_ParId" "";
BA_DEF_DEF_  "CI_SigId" 0;
BA_DEF_DEF_  "CI_SigName" "";
BA_DEF_DEF_  "GenSigEVName" "Env@Nodename_@Signame";
BA_DEF_DEF_  "GenSigILSupport" "Yes";
BA_DEF_DEF_  "GenSigInactiveValue" 0;
BA_DEF_DEF_  "GenSigSendType" "NoSigSendType";
BA_DEF_DEF_  "GenSigStartValue" 0;
BA_DEF_DEF_  "GenSigTimeoutTime_PCM" 0;
BA_DEF_DEF_  "GenSigTimeoutTime_SGW" 0;
BA_DEF_DEF_  "SPN" 0;
BA_DEF_DEF_  "SigType" "Default";
BA_ "CI_MsgDefinition" BO_ 2583663895 "Iveco Daily";
BA_ "CI_MsgId" BO_ 2583663895 42682;
BA_ "CI_MsgName" BO_ 2583663895 "PB_GenCtrl2_17 - Proprietary B - Generic Controls 2";
BA_ "GenMsgCycleTime" BO_ 2583663895 500;
BA_ "GenMsgCycleTimeFast" BO_ 2583663895 500;
BA_ "GenMsgDelayTime" BO_ 2583663895 50;
BA_ "GenMsgSendType" BO_ 2583663895 0;
BA_ "GenMsgStartDelayTime" BO_ 2583663895 132;
BA_ "CI_MsgDefinition" BO_ 2583651623 "Iveco Daily Electric";
BA_ "CI_MsgId" BO_ 2583651623 39655;
BA_ "CI_MsgName" BO_ 2583651623 "PB_GWVMU1_27 - PB_GWVMU1";
BA_ "GenMsgCycleTime" BO_ 2583651623 100;
BA_ "GenMsgCycleTimeFast" BO_ 2583651623 100;
BA_ "GenMsgDelayTime" BO_ 2583651623 50;
BA_ "GenMsgSendType" BO_ 2583651623 0;
BA_ "GenMsgStartDelayTime" BO_ 2583651623 94;
BA_ "CI_MsgDefinition" BO_ 2650776710 "Iveco Daily Electric";
BA_ "CI_MsgId" BO_ 2650776710 44037;
BA_ "CI_MsgName" BO_ 2650776710 "PB_HCC_86 - Proprietary B - High Current Counter";
BA_ "GenMsgCycleTime" BO_ 2650776710 600000;
BA_ "GenMsgCycleTimeFast" BO_ 2650776710 600000;
BA_ "GenMsgDelayTime" BO_ 2650776710 300000;
BA_ "GenMsgSendType" BO_ 2650776710 0;
BA_ "GenMsgStartDelayTime" BO_ 2650776710 375;
BA_ "CI_MsgDefinition" BO_ 2650776711 "Iveco Daily Electric";
BA_ "CI_MsgId" BO_ 2650776711 44040;
BA_ "CI_MsgName" BO_ 2650776711 "PB_HCC_87 - Proprietary B - High Current Counter";
BA_ "GenMsgCycleTime" BO_ 2650776711 600000;
BA_ "GenMsgCycleTimeFast" BO_ 2650776711 600000;
BA_ "GenMsgDelayTime" BO_ 2650776711 300000;
BA_ "GenMsgSendType" BO_ 2650776711 0;
BA_ "GenMsgStartDelayTime" BO_ 2650776711 376;
BA_ "CI_MsgDefinition" BO_ 2650776820 "Iveco Daily Electric";
BA_ "CI_MsgId" BO_ 2650776820 44028;
BA_ "CI_MsgName" BO_ 2650776820 "PB_HCC_F4 - Proprietary B - High Current Counter";
BA_ "GenMsgCycleTime" BO_ 2650776820 600000;
BA_ "GenMsgCycleTimeFast" BO_ 2650776820 600000;
BA_ "GenMsgDelayTime" BO_ 2650776820 300000;
BA_ "GenMsgSendType" BO_ 2650776820 0;
BA_ "GenMsgStartDelayTime" BO_ 2650776820 377;
BA_ "CI_MsgDefinition" BO_ 2650776821 "Iveco Daily Electric";
BA_ "CI_MsgId" BO_ 2650776821 44031;
BA_ "CI_MsgName" BO_ 2650776821 "PB_HCC_F5 - Proprietary B - High Current Counter";
BA_ "GenMsgCycleTime" BO_ 2650776821 600000;
BA_ "GenMsgCycleTimeFast" BO_ 2650776821 600000;
BA_ "GenMsgDelayTime" BO_ 2650776821 300000;
BA_ "GenMsgSendType" BO_ 2650776821 0;
BA_ "GenMsgStartDelayTime" BO_ 2650776821 378;
BA_ "CI_MsgDefinition" BO_ 2650776822 "Iveco Daily Electric";
BA_ "CI_MsgId" BO_ 2650776822 44034;
BA_ "CI_MsgName" BO_ 2650776822 "PB_HCC_F6 - Proprietary B - High Current Counter";
BA_ "GenMsgCycleTime" BO_ 2650776822 600000;
BA_ "GenMsgCycleTimeFast" BO_ 2650776822 600000;
BA_ "GenMsgDelayTime" BO_ 2650776822 300000;
BA_ "GenMsgSendType" BO_ 2650776822 0;
BA_ "GenMsgStartDelayTime" BO_ 2650776822 379;
BA_ "CI_MsgDefinition" BO_ 2566904343 "Iveco Proprietary";
BA_ "CI_MsgId" BO_ 2566904343 8840;
BA_ "CI_MsgName" BO_ 2566904343 "PB_HVAC_17 - Iveco Heating, Ventilation, and Air-Conditioning Information";
BA_ "GenMsgCycleTime" BO_ 2566904343 1000;
BA_ "GenMsgCycleTimeFast" BO_ 2566904343 1000;
BA_ "GenMsgDelayTime" BO_ 2566904343 100;
BA_ "GenMsgSendType" BO_ 2566904343 0;
BA_ "GenMsgStartDelayTime" BO_ 2566904343 273;
BA_ "CI_MsgDefinition" BO_ 2566904345 "Iveco Proprietary";
BA_ "CI_MsgId" BO_ 2566904345 43754;
BA_ "CI_MsgName" BO_ 2566904345 "PB_HVAC_19 - Iveco Heating, Ventilation, and Air-Conditioning Information";
BA_ "GenMsgCycleTime" BO_ 2566904345 1000;
BA_ "GenMsgCycleTimeFast" BO_ 2566904345 1000;
BA_ "GenMsgDelayTime" BO_ 2566904345 100;
BA_ "GenMsgSendType" BO_ 2566904345 0;
BA_ "GenMsgStartDelayTime" BO_ 2566904345 274;
BA_ "CI_MsgDefinition" BO_ 2566904353 "Iveco Proprietary";
BA_ "CI_MsgId" BO_ 2566904353 8853;
BA_ "CI_MsgName" BO_ 2566904353 "PB_HVAC_21 - Iveco Heating, Ventilation, and Air-Conditioning Information";
BA_ "GenMsgCycleTime" BO_ 2566904353 1000;
BA_ "GenMsgCycleTimeFast" BO_ 2566904353 1000;
BA_ "GenMsgDelayTime" BO_ 2566904353 20;
BA_ "GenMsgSendType" BO_ 2566904353 0;
BA_ "GenMsgStartDelayTime" BO_ 2566904353 275;
BA_ "CI_MsgDefinition" BO_ 2566904394 "Iveco Proprietary";
BA_ "CI_MsgId" BO_ 2566904394 43035;
BA_ "CI_MsgName" BO_ 2566904394 "PB_HVAC_4A - Iveco Heating, Ventilation, and Air-Conditioning Information";
BA_ "GenMsgDelayTime" BO_ 2566904394 20;
BA_ "CI_MsgDefinition" BO_ 2382311251 "Iveco Daily Electric";
BA_ "CI_MsgId" BO_ 2382311251 44415;
BA_ "CI_MsgName" BO_ 2382311251 "PB_HVCOR_53 - Proprietary B - High Voltage CutOff Request";
BA_ "GenMsgCycleTime" BO_ 2382311251 500;
BA_ "GenMsgCycleTimeFast" BO_ 2382311251 20;
BA_ "GenMsgDelayTime" BO_ 2382311251 10;
BA_ "GenMsgSendType" BO_ 2382311251 0;
BA_ "GenMsgStartDelayTime" BO_ 2382311251 21;
BA_ "CI_MsgDefinition" BO_ 2382311463 "Iveco Daily Electric";
BA_ "CI_MsgId" BO_ 2382311463 41827;
BA_ "CI_MsgName" BO_ 2382311463 "PB_HVCOS_27 - Proprietary B - High Voltage CutOff Status";
BA_ "GenMsgCycleTime" BO_ 2382311463 20;
BA_ "GenMsgCycleTimeFast" BO_ 2382311463 20;
BA_ "GenMsgDelayTime" BO_ 2382311463 10;
BA_ "GenMsgSendType" BO_ 2382311463 0;
BA_ "GenMsgStartDelayTime" BO_ 2382311463 22;
BA_ "CI_MsgDefinition" BO_ 2650750195 "Iveco Daily Electric";
BA_ "CI_MsgId" BO_ 2650750195 40384;
BA_ "CI_MsgName" BO_ 2650750195 "PB_HVESSCFG_F3 - Proprietary B - High Voltage Energy Storage System Configuration";
BA_ "CI_MsgDefinition" BO_ 2583627910 "Iveco Daily Electric";
BA_ "CI_MsgId" BO_ 2583627910 45289;
BA_ "CI_MsgName" BO_ 2583627910 "PB_HVESSD1_86 - Proprietary B - High Voltage Energy Storage System Data 1";
BA_ "GenMsgCycleTime" BO_ 2583627910 250;
BA_ "GenMsgCycleTimeFast" BO_ 2583627910 250;
BA_ "GenMsgDelayTime" BO_ 2583627910 125;
BA_ "GenMsgSendType" BO_ 2583627910 0;
BA_ "GenMsgStartDelayTime" BO_ 2583627910 113;
BA_ "CI_MsgDefinition" BO_ 2583627911 "Iveco Daily Electric";
BA_ "CI_MsgId" BO_ 2583627911 45296;
BA_ "CI_MsgName" BO_ 2583627911 "PB_HVESSD1_87 - Proprietary B - High Voltage Energy Storage System Data 1";
BA_ "GenMsgCycleTime" BO_ 2583627911 250;
BA_ "GenMsgCycleTimeFast" BO_ 2583627911 250;
BA_ "GenMsgDelayTime" BO_ 2583627911 125;
BA_ "GenMsgSendType" BO_ 2583627911 0;
BA_ "GenMsgStartDelayTime" BO_ 2583627911 114;
BA_ "CI_MsgDefinition" BO_ 2583628019 "Iveco Daily Electric";
BA_ "CI_MsgId" BO_ 2583628019 45234;
BA_ "CI_MsgName" BO_ 2583628019 "PB_HVESSD1_F3 - Proprietary B - High Voltage Energy Storage System Data 1";
BA_ "GenMsgCycleTime" BO_ 2583628019 250;
BA_ "GenMsgCycleTimeFast" BO_ 2583628019 250;
BA_ "GenMsgDelayTime" BO_ 2583628019 125;
BA_ "GenMsgSendType" BO_ 2583628019 0;
BA_ "GenMsgStartDelayTime" BO_ 2583628019 115;
BA_ "CI_MsgDefinition" BO_ 2583628020 "Iveco Daily Electric";
BA_ "CI_MsgId" BO_ 2583628020 45268;
BA_ "CI_MsgName" BO_ 2583628020 "PB_HVESSD1_F4 - Proprietary B - High Voltage Energy Storage System Data 1";
BA_ "GenMsgCycleTime" BO_ 2583628020 250;
BA_ "GenMsgCycleTimeFast" BO_ 2583628020 250;
BA_ "GenMsgDelayTime" BO_ 2583628020 125;
BA_ "GenMsgSendType" BO_ 2583628020 0;
BA_ "GenMsgStartDelayTime" BO_ 2583628020 116;
BA_ "CI_MsgDefinition" BO_ 2583628021 "Iveco Daily Electric";
BA_ "CI_MsgId" BO_ 2583628021 45275;
BA_ "CI_MsgName" BO_ 2583628021 "PB_HVESSD1_F5 - Proprietary B - High Voltage Energy Storage System Data 1";
BA_ "GenMsgCycleTime" BO_ 2583628021 250;
BA_ "GenMsgCycleTimeFast" BO_ 2583628021 250;
BA_ "GenMsgDelayTime" BO_ 2583628021 125;
BA_ "GenMsgSendType" BO_ 2583628021 0;
BA_ "GenMsgStartDelayTime" BO_ 2583628021 117;
BA_ "CI_MsgDefinition" BO_ 2583628022 "Iveco Daily Electric";
BA_ "CI_MsgId" BO_ 2583628022 45282;
BA_ "CI_MsgName" BO_ 2583628022 "PB_HVESSD1_F6 - Proprietary B - High Voltage Energy Storage System Data 1";
BA_ "GenMsgCycleTime" BO_ 2583628022 250;
BA_ "GenMsgCycleTimeFast" BO_ 2583628022 250;
BA_ "GenMsgDelayTime" BO_ 2583628022 125;
BA_ "GenMsgSendType" BO_ 2583628022 0;
BA_ "GenMsgStartDelayTime" BO_ 2583628022 118;
BA_ "CI_MsgDefinition" BO_ 2583628275 "Iveco Daily Electric";
BA_ "CI_MsgId" BO_ 2583628275 45242;
BA_ "CI_MsgName" BO_ 2583628275 "PB_HVESSD2_F3 - Proprietary B - High Voltage Energy Storage System Data 2";
BA_ "GenMsgCycleTime" BO_ 2583628275 20;
BA_ "GenMsgCycleTimeFast" BO_ 2583628275 20;
BA_ "GenMsgDelayTime" BO_ 2583628275 10;
BA_ "GenMsgSendType" BO_ 2583628275 0;
BA_ "GenMsgStartDelayTime" BO_ 2583628275 27;
BA_ "CI_MsgDefinition" BO_ 2583628531 "Iveco Daily Electric";
BA_ "CI_MsgId" BO_ 2583628531 45248;
BA_ "CI_MsgName" BO_ 2583628531 "PB_HVESSD3_F3 - Proprietary B - High Voltage Energy Storage System Data 3";
BA_ "GenMsgCycleTime" BO_ 2583628531 20;
BA_ "GenMsgCycleTimeFast" BO_ 2583628531 20;
BA_ "GenMsgDelayTime" BO_ 2583628531 10;
BA_ "GenMsgSendType" BO_ 2583628531 0;
BA_ "GenMsgStartDelayTime" BO_ 2583628531 28;
BA_ "CI_MsgDefinition" BO_ 2583628787 "Iveco Daily Electric";
BA_ "CI_MsgId" BO_ 2583628787 45253;
BA_ "CI_MsgName" BO_ 2583628787 "PB_HVESSD4_F3 - Proprietary B - High Voltage Energy Storage System Data 4";
BA_ "GenMsgCycleTime" BO_ 2583628787 20;
BA_ "GenMsgCycleTimeFast" BO_ 2583628787 20;
BA_ "GenMsgDelayTime" BO_ 2583628787 10;
BA_ "GenMsgSendType" BO_ 2583628787 0;
BA_ "GenMsgStartDelayTime" BO_ 2583628787 29;
BA_ "CI_MsgDefinition" BO_ 2583628934 "Iveco Daily Electric";
BA_ "CI_MsgId" BO_ 2583628934 45330;
BA_ "CI_MsgName" BO_ 2583628934 "PB_HVESSHIST1_86 - Proprietary B - High Voltage Energy Storage System History 1";
BA_ "GenMsgCycleTime" BO_ 2583628934 10000;
BA_ "GenMsgCycleTimeFast" BO_ 2583628934 10000;
BA_ "GenMsgDelayTime" BO_ 2583628934 5000;
BA_ "GenMsgSendType" BO_ 2583628934 0;
BA_ "GenMsgStartDelayTime" BO_ 2583628934 346;
BA_ "CI_MsgDefinition" BO_ 2583628935 "Iveco Daily Electric";
BA_ "CI_MsgId" BO_ 2583628935 45339;
BA_ "CI_MsgName" BO_ 2583628935 "PB_HVESSHIST1_87 - Proprietary B - High Voltage Energy Storage System History 1";
BA_ "GenMsgCycleTime" BO_ 2583628935 10000;
BA_ "GenMsgCycleTimeFast" BO_ 2583628935 10000;
BA_ "GenMsgDelayTime" BO_ 2583628935 5000;
BA_ "GenMsgSendType" BO_ 2583628935 0;
BA_ "GenMsgStartDelayTime" BO_ 2583628935 347;
BA_ "CI_MsgDefinition" BO_ 2583629043 "Iveco Daily Electric";
BA_ "CI_MsgId" BO_ 2583629043 45259;
BA_ "CI_MsgName" BO_ 2583629043 "PB_HVESSHIST1_F3 - Proprietary B - High Voltage Energy Storage System History 1";
BA_ "GenMsgCycleTime" BO_ 2583629043 1500;
BA_ "GenMsgCycleTimeFast" BO_ 2583629043 1500;
BA_ "GenMsgDelayTime" BO_ 2583629043 750;
BA_ "GenMsgSendType" BO_ 2583629043 0;
BA_ "GenMsgStartDelayTime" BO_ 2583629043 327;
BA_ "CI_MsgDefinition" BO_ 2583629044 "Iveco Daily Electric";
BA_ "CI_MsgId" BO_ 2583629044 45303;
BA_ "CI_MsgName" BO_ 2583629044 "PB_HVESSHIST1_F4 - Proprietary B - High Voltage Energy Storage System History 1";
BA_ "GenMsgCycleTime" BO_ 2583629044 10000;
BA_ "GenMsgCycleTimeFast" BO_ 2583629044 10000;
BA_ "GenMsgDelayTime" BO_ 2583629044 5000;
BA_ "GenMsgSendType" BO_ 2583629044 0;
BA_ "GenMsgStartDelayTime" BO_ 2583629044 348;
BA_ "CI_MsgDefinition" BO_ 2583629045 "Iveco Daily Electric";
BA_ "CI_MsgId" BO_ 2583629045 45312;
BA_ "CI_MsgName" BO_ 2583629045 "PB_HVESSHIST1_F5 - Proprietary B - High Voltage Energy Storage System History 1";
BA_ "GenMsgCycleTime" BO_ 2583629045 10000;
BA_ "GenMsgCycleTimeFast" BO_ 2583629045 10000;
BA_ "GenMsgDelayTime" BO_ 2583629045 5000;
BA_ "GenMsgSendType" BO_ 2583629045 0;
BA_ "GenMsgStartDelayTime" BO_ 2583629045 349;
BA_ "CI_MsgDefinition" BO_ 2583629046 "Iveco Daily Electric";
BA_ "CI_MsgId" BO_ 2583629046 45321;
BA_ "CI_MsgName" BO_ 2583629046 "PB_HVESSHIST1_F6 - Proprietary B - High Voltage Energy Storage System History 1";
BA_ "GenMsgCycleTime" BO_ 2583629046 10000;
BA_ "GenMsgCycleTimeFast" BO_ 2583629046 10000;
BA_ "GenMsgDelayTime" BO_ 2583629046 5000;
BA_ "GenMsgSendType" BO_ 2583629046 0;
BA_ "GenMsgStartDelayTime" BO_ 2583629046 351;
BA_ "CI_MsgDefinition" BO_ 2583629190 "Iveco Daily Electric";
BA_ "CI_MsgId" BO_ 2583629190 45335;
BA_ "CI_MsgName" BO_ 2583629190 "PB_HVESSHIST2_86 - Proprietary B - High Voltage Energy Storage System History 2";
BA_ "GenMsgCycleTime" BO_ 2583629190 10000;
BA_ "GenMsgCycleTimeFast" BO_ 2583629190 10000;
BA_ "GenMsgDelayTime" BO_ 2583629190 5000;
BA_ "GenMsgSendType" BO_ 2583629190 0;
BA_ "GenMsgStartDelayTime" BO_ 2583629190 352;
BA_ "CI_MsgDefinition" BO_ 2583629191 "Iveco Daily Electric";
BA_ "CI_MsgId" BO_ 2583629191 45344;
BA_ "CI_MsgName" BO_ 2583629191 "PB_HVESSHIST2_87 - Proprietary B - High Voltage Energy Storage System History 2";
BA_ "GenMsgCycleTime" BO_ 2583629191 10000;
BA_ "GenMsgCycleTimeFast" BO_ 2583629191 10000;
BA_ "GenMsgDelayTime" BO_ 2583629191 5000;
BA_ "GenMsgSendType" BO_ 2583629191 0;
BA_ "GenMsgStartDelayTime" BO_ 2583629191 353;
BA_ "CI_MsgDefinition" BO_ 2583629299 "Iveco Daily Electric";
BA_ "CI_MsgId" BO_ 2583629299 45264;
BA_ "CI_MsgName" BO_ 2583629299 "PB_HVESSHIST2_F3 - Proprietary B - High Voltage Energy Storage System History 2";
BA_ "GenMsgCycleTime" BO_ 2583629299 1500;
BA_ "GenMsgCycleTimeFast" BO_ 2583629299 1500;
BA_ "GenMsgDelayTime" BO_ 2583629299 750;
BA_ "GenMsgSendType" BO_ 2583629299 0;
BA_ "GenMsgStartDelayTime" BO_ 2583629299 328;
BA_ "CI_MsgDefinition" BO_ 2583629300 "Iveco Daily Electric";
BA_ "CI_MsgId" BO_ 2583629300 45308;
BA_ "CI_MsgName" BO_ 2583629300 "PB_HVESSHIST2_F4 - Proprietary B - High Voltage Energy Storage System History 2";
BA_ "GenMsgCycleTime" BO_ 2583629300 10000;
BA_ "GenMsgCycleTimeFast" BO_ 2583629300 10000;
BA_ "GenMsgDelayTime" BO_ 2583629300 5000;
BA_ "GenMsgSendType" BO_ 2583629300 0;
BA_ "GenMsgStartDelayTime" BO_ 2583629300 354;
BA_ "CI_MsgDefinition" BO_ 2583629301 "Iveco Daily Electric";
BA_ "CI_MsgId" BO_ 2583629301 45317;
BA_ "CI_MsgName" BO_ 2583629301 "PB_HVESSHIST2_F5 - Proprietary B - High Voltage Energy Storage System History 2";
BA_ "GenMsgCycleTime" BO_ 2583629301 10000;
BA_ "GenMsgCycleTimeFast" BO_ 2583629301 10000;
BA_ "GenMsgDelayTime" BO_ 2583629301 5000;
BA_ "GenMsgSendType" BO_ 2583629301 0;
BA_ "GenMsgStartDelayTime" BO_ 2583629301 355;
BA_ "CI_MsgDefinition" BO_ 2583629302 "Iveco Daily Electric";
BA_ "CI_MsgId" BO_ 2583629302 45326;
BA_ "CI_MsgName" BO_ 2583629302 "PB_HVESSHIST2_F6 - Proprietary B - High Voltage Energy Storage System History 2";
BA_ "GenMsgCycleTime" BO_ 2583629302 10000;
BA_ "GenMsgCycleTimeFast" BO_ 2583629302 10000;
BA_ "GenMsgDelayTime" BO_ 2583629302 5000;
BA_ "GenMsgSendType" BO_ 2583629302 0;
BA_ "GenMsgStartDelayTime" BO_ 2583629302 356;
BA_ "CI_MsgDefinition" BO_ 2634014026 "Iveco NH Proprietary";
BA_ "CI_MsgId" BO_ 2634014026 4894;
BA_ "CI_MsgName" BO_ 2634014026 "PB_ICPT_4A - Proprietary B - Iveco Instrument Cluster Popup Text";
BA_ "GenMsgDelayTime" BO_ 2634014026 100;
BA_ "TpJ1939VarDlc" BO_ 2634014026 1;
BA_ "CI_MsgDefinition" BO_ 2634014066 "Iveco NH Proprietary";
BA_ "CI_MsgId" BO_ 2634014066 4898;
BA_ "CI_MsgName" BO_ 2634014066 "PB_ICPT_72 - Proprietary B - Iveco Instrument Cluster Popup Text";
BA_ "GenMsgCycleTimeFast" BO_ 2634014066 100;
BA_ "GenMsgDelayTime" BO_ 2634014066 50;
BA_ "GenMsgStartDelayTime" BO_ 2634014066 96;
BA_ "CI_MsgDefinition" BO_ 2566904855 "Iveco NH Proprietary";
BA_ "CI_MsgId" BO_ 2566904855 4862;
BA_ "CI_MsgName" BO_ 2566904855 "PB_ICS - Proprietary B - Iveco Instrument Cluster Status";
BA_ "GenMsgDelayTime" BO_ 2566904855 100;
BA_ "CI_MsgDefinition" BO_ 2315191791 "Iveco Daily Electric";
BA_ "CI_MsgId" BO_ 2315191791 45139;
BA_ "CI_MsgName" BO_ 2315191791 "PB_INV_FDBK_V2_EF - Proprietary B - Inverter Feedback";
BA_ "GenMsgCycleTime" BO_ 2315191791 20;
BA_ "GenMsgCycleTimeFast" BO_ 2315191791 20;
BA_ "GenMsgDelayTime" BO_ 2315191791 10;
BA_ "GenMsgSendType" BO_ 2315191791 0;
BA_ "GenMsgStartDelayTime" BO_ 2315191791 12;
BA_ "CI_MsgDefinition" BO_ 2583627762 "Iveco Daily Electric";
BA_ "CI_MsgId" BO_ 2583627762 45216;
BA_ "CI_MsgName" BO_ 2583627762 "PB_INV_INFO_F2 - Proprietary B - Inverter Information";
BA_ "GenMsgCycleTime" BO_ 2583627762 1000;
BA_ "GenMsgCycleTimeFast" BO_ 2583627762 1000;
BA_ "GenMsgDelayTime" BO_ 2583627762 500;
BA_ "GenMsgSendType" BO_ 2583627762 0;
BA_ "GenMsgStartDelayTime" BO_ 2583627762 281;
BA_ "CI_MsgDefinition" BO_ 2566894871 "Iveco Proprietary";
BA_ "CI_MsgId" BO_ 2566894871 42355;
BA_ "CI_MsgName" BO_ 2566894871 "PB_ISA1_17 - Proprietary B - Intelligent Speed Assistant 1";
BA_ "GenMsgCycleTime" BO_ 2566894871 1000;
BA_ "GenMsgCycleTimeFast" BO_ 2566894871 1000;
BA_ "GenMsgDelayTime" BO_ 2566894871 100;
BA_ "GenMsgSendType" BO_ 2566894871 0;
BA_ "GenMsgStartDelayTime" BO_ 2566894871 264;
BA_ "CI_MsgDefinition" BO_ 2566894890 "Iveco Proprietary";
BA_ "CI_MsgId" BO_ 2566894890 42362;
BA_ "CI_MsgName" BO_ 2566894890 "PB_ISA1_2A - Proprietary B - Intelligent Speed Assistant 1";
BA_ "GenMsgCycleTime" BO_ 2566894890 1000;
BA_ "GenMsgCycleTimeFast" BO_ 2566894890 1000;
BA_ "GenMsgDelayTime" BO_ 2566894890 100;
BA_ "GenMsgSendType" BO_ 2566894890 0;
BA_ "GenMsgStartDelayTime" BO_ 2566894890 265;
BA_ "CI_MsgDefinition" BO_ 2566894922 "Iveco Proprietary";
BA_ "CI_MsgId" BO_ 2566894922 42369;
BA_ "CI_MsgName" BO_ 2566894922 "PB_ISA1_4A - Proprietary B - Intelligent Speed Assistant 1";
BA_ "CI_MsgDefinition" BO_ 2566890538 "Iveco Proprietary";
BA_ "CI_MsgId" BO_ 2566890538 42380;
BA_ "CI_MsgName" BO_ 2566890538 "PB_ISA2_2A - Proprietary B - Intelligent Speed Assistant 2";
BA_ "GenMsgCycleTime" BO_ 2566890538 1000;
BA_ "GenMsgCycleTimeFast" BO_ 2566890538 1000;
BA_ "GenMsgDelayTime" BO_ 2566890538 100;
BA_ "GenMsgSendType" BO_ 2566890538 0;
BA_ "GenMsgStartDelayTime" BO_ 2566890538 259;
BA_ "CI_MsgDefinition" BO_ 2566852119 "Iveco Proprietary";
BA_ "CI_MsgId" BO_ 2566852119 6387;
BA_ "CI_MsgName" BO_ 2566852119 "PB_LLC_17 - Proprietary B - Iveco Longitudinal and Lateral Control";
BA_ "GenMsgCycleTime" BO_ 2566852119 1000;
BA_ "GenMsgCycleTimeFast" BO_ 2566852119 1000;
BA_ "GenMsgDelayTime" BO_ 2566852119 100;
BA_ "GenMsgSendType" BO_ 2566852119 0;
BA_ "GenMsgStartDelayTime" BO_ 2566852119 247;
BA_ "CI_MsgDefinition" BO_ 2566852129 "Iveco Proprietary";
BA_ "CI_MsgId" BO_ 2566852129 6405;
BA_ "CI_MsgName" BO_ 2566852129 "PB_LLC_21 - Proprietary B - Iveco Longitudinal and Lateral Control";
BA_ "GenMsgCycleTime" BO_ 2566852129 1000;
BA_ "GenMsgCycleTimeFast" BO_ 2566852129 1000;
BA_ "GenMsgDelayTime" BO_ 2566852129 100;
BA_ "GenMsgSendType" BO_ 2566852129 0;
BA_ "GenMsgStartDelayTime" BO_ 2566852129 248;
BA_ "CI_MsgDefinition" BO_ 2566852138 "Iveco Proprietary";
BA_ "CI_MsgId" BO_ 2566852138 6409;
BA_ "CI_MsgName" BO_ 2566852138 "PB_LLC_2A - Proprietary B - Iveco Longitudinal and Lateral Control";
BA_ "GenMsgCycleTime" BO_ 2566852138 1000;
BA_ "GenMsgCycleTimeFast" BO_ 2566852138 1000;
BA_ "GenMsgDelayTime" BO_ 2566852138 100;
BA_ "GenMsgSendType" BO_ 2566852138 0;
BA_ "GenMsgStartDelayTime" BO_ 2566852138 249;
BA_ "CI_MsgDefinition" BO_ 2583664161 "Iveco Daily";
BA_ "CI_MsgId" BO_ 2583664161 44699;
BA_ "CI_MsgName" BO_ 2583664161 "PB_MAC_RRCS1_21 - Proprietary B - MAC - Remote Request Command Status 1";
BA_ "GenMsgDelayTime" BO_ 2583664161 100;
BA_ "CI_MsgDefinition" BO_ 2583664202 "Iveco Daily";
BA_ "CI_MsgId" BO_ 2583664202 44689;
BA_ "CI_MsgName" BO_ 2583664202 "PB_MAC_RRCS1_4A - Proprietary B - MAC - Remote Request Command Status 1";
BA_ "GenMsgDelayTime" BO_ 2583664202 100;
BA_ "CI_MsgDefinition" BO_ 2583664417 "Iveco Daily";
BA_ "CI_MsgId" BO_ 2583664417 44726;
BA_ "CI_MsgName" BO_ 2583664417 "PB_MAC_RRCS2_21 - Proprietary B - MAC - Remote Request Command Status 2";
BA_ "GenMsgDelayTime" BO_ 2583664417 100;
BA_ "CI_MsgDefinition" BO_ 2583664458 "Iveco Daily";
BA_ "CI_MsgId" BO_ 2583664458 44709;
BA_ "CI_MsgName" BO_ 2583664458 "PB_MAC_RRCS2_4A - Proprietary B - MAC - Remote Request Command Status 2";
BA_ "GenMsgDelayTime" BO_ 2583664458 100;
BA_ "CI_MsgDefinition" BO_ 2365579287 "Iveco SPR1 Proprietary";
BA_ "CI_MsgId" BO_ 2365579287 26531;
BA_ "CI_MsgName" BO_ 2365579287 "PB_Nm_17 - Proprietary B - Iveco Network Management (Slave Node)";
BA_ "GenMsgCycleTime" BO_ 2365579287 1000;
BA_ "GenMsgCycleTimeFast" BO_ 2365579287 50;
BA_ "GenMsgDelayTime" BO_ 2365579287 25;
BA_ "GenMsgSendType" BO_ 2365579287 0;
BA_ "GenMsgStartDelayTime" BO_ 2365579287 37;
BA_ "CI_MsgDefinition" BO_ 2365579303 "Iveco SPR1 Proprietary";
BA_ "CI_MsgId" BO_ 2365579303 26553;
BA_ "CI_MsgName" BO_ 2365579303 "PB_Nm_27 - Proprietary B - Iveco Network Management (Slave Node)";
BA_ "GenMsgCycleTime" BO_ 2365579303 1000;
BA_ "GenMsgCycleTimeFast" BO_ 2365579303 50;
BA_ "GenMsgDelayTime" BO_ 2365579303 25;
BA_ "GenMsgSendType" BO_ 2365579303 0;
BA_ "GenMsgStartDelayTime" BO_ 2365579303 38;
BA_ "CI_MsgDefinition" BO_ 2365579329 "Iveco SPR1 Proprietary";
BA_ "CI_MsgId" BO_ 2365579329 26569;
BA_ "CI_MsgName" BO_ 2365579329 "PB_Nm_41 - Proprietary B - Iveco Network Management (Slave Node)";
BA_ "GenMsgCycleTime" BO_ 2365579329 1000;
BA_ "GenMsgCycleTimeFast" BO_ 2365579329 50;
BA_ "GenMsgDelayTime" BO_ 2365579329 25;
BA_ "GenMsgSendType" BO_ 2365579329 0;
BA_ "GenMsgStartDelayTime" BO_ 2365579329 39;
BA_ "CI_MsgDefinition" BO_ 2365579338 "Iveco SPR1 Proprietary";
BA_ "CI_MsgId" BO_ 2365579338 26576;
BA_ "CI_MsgName" BO_ 2365579338 "PB_Nm_4A - Proprietary B - Iveco Network Management (Slave Node)";
BA_ "GenMsgCycleTime" BO_ 2365579338 50;
BA_ "GenMsgCycleTimeFast" BO_ 2365579338 50;
BA_ "GenMsgDelayTime" BO_ 2365579338 25;
BA_ "GenMsgSendType" BO_ 2365579338 0;
BA_ "CI_MsgDefinition" BO_ 2365579341 "Iveco SPR1 Proprietary";
BA_ "CI_MsgId" BO_ 2365579341 26583;
BA_ "CI_MsgName" BO_ 2365579341 "PB_Nm_4D - Proprietary B - Iveco Network Management (Slave Node)";
BA_ "GenMsgCycleTime" BO_ 2365579341 1000;
BA_ "GenMsgCycleTimeFast" BO_ 2365579341 50;
BA_ "GenMsgDelayTime" BO_ 2365579341 25;
BA_ "GenMsgSendType" BO_ 2365579341 0;
BA_ "GenMsgStartDelayTime" BO_ 2365579341 41;
BA_ "CI_MsgDefinition" BO_ 2365575713 "Iveco SPR1 Proprietary";
BA_ "CI_MsgId" BO_ 2365575713 26511;
BA_ "CI_MsgName" BO_ 2365575713 "PB_NmM - Proprietary B - Iveco Network Management (Master Node)";
BA_ "GenMsgCycleTime" BO_ 2365575713 1000;
BA_ "GenMsgCycleTimeFast" BO_ 2365575713 50;
BA_ "GenMsgDelayTime" BO_ 2365575713 25;
BA_ "GenMsgSendType" BO_ 2365575713 0;
BA_ "CI_MsgDefinition" BO_ 2365528587 "Sensata Technologies Proprietary";
BA_ "CI_MsgId" BO_ 2365528587 6154;
BA_ "CI_MsgName" BO_ 2365528587 "PB_PAL_0B - Phase Auto-Location (Sensata Technologies Proprietary)";
BA_ "GenMsgCycleTime" BO_ 2365528587 20;
BA_ "GenMsgCycleTimeFast" BO_ 2365528587 20;
BA_ "GenMsgDelayTime" BO_ 2365528587 10;
BA_ "GenMsgSendType" BO_ 2365528587 0;
BA_ "GenMsgStartDelayTime" BO_ 2365528587 19;
BA_ "CI_MsgDefinition" BO_ 2566891593 "Iveco Proprietary";
BA_ "CI_MsgId" BO_ 2566891593 35304;
BA_ "CI_MsgName" BO_ 2566891593 "PB_PbcToVmu1_49 - Proprietary B - PBC to VMU 1";
BA_ "GenMsgCycleTime" BO_ 2566891593 100;
BA_ "GenMsgCycleTimeFast" BO_ 2566891593 100;
BA_ "GenMsgDelayTime" BO_ 2566891593 50;
BA_ "GenMsgSendType" BO_ 2566891593 0;
BA_ "GenMsgStartDelayTime" BO_ 2566891593 83;
BA_ "CI_MsgDefinition" BO_ 2566858007 "Iveco Proprietary";
BA_ "CI_MsgId" BO_ 2566858007 9517;
BA_ "CI_MsgName" BO_ 2566858007 "PB_RadioCmdEx_17 - Radio Command (new ID)";
BA_ "GenMsgCycleTime" BO_ 2566858007 1000;
BA_ "GenMsgCycleTimeFast" BO_ 2566858007 1000;
BA_ "GenMsgDelayTime" BO_ 2566858007 100;
BA_ "GenMsgSendType" BO_ 2566858007 0;
BA_ "GenMsgStartDelayTime" BO_ 2566858007 252;
BA_ "CI_MsgDefinition" BO_ 2566858017 "Iveco Proprietary";
BA_ "CI_MsgId" BO_ 2566858017 9534;
BA_ "CI_MsgName" BO_ 2566858017 "PB_RadioCmdEx_21 - Radio Command (new ID)";
BA_ "GenMsgCycleTime" BO_ 2566858017 1000;
BA_ "GenMsgCycleTimeFast" BO_ 2566858017 1000;
BA_ "GenMsgDelayTime" BO_ 2566858017 100;
BA_ "GenMsgSendType" BO_ 2566858017 0;
BA_ "GenMsgStartDelayTime" BO_ 2566858017 253;
BA_ "CI_MsgDefinition" BO_ 2566858058 "Iveco Proprietary";
BA_ "CI_MsgId" BO_ 2566858058 9548;
BA_ "CI_MsgName" BO_ 2566858058 "PB_RadioCmdEx_4A - Radio Command (new ID)";
BA_ "GenMsgCycleTime" BO_ 2566858058 1000;
BA_ "GenMsgCycleTimeFast" BO_ 2566858058 1000;
BA_ "GenMsgDelayTime" BO_ 2566858058 100;
BA_ "GenMsgSendType" BO_ 2566858058 0;
BA_ "GenMsgStartDelayTime" BO_ 2566858058 20;
BA_ "CI_MsgDefinition" BO_ 2566897729 "Iveco Proprietary";
BA_ "CI_MsgId" BO_ 2566897729 42149;
BA_ "CI_MsgName" BO_ 2566897729 "PB_RadioDisEx - Radio Display Extended";
BA_ "GenMsgCycleTime" BO_ 2566897729 1000;
BA_ "GenMsgCycleTimeFast" BO_ 2566897729 1000;
BA_ "GenMsgDelayTime" BO_ 2566897729 250;
BA_ "GenMsgSendType" BO_ 2566897729 0;
BA_ "GenMsgStartDelayTime" BO_ 2566897729 271;
BA_ "TpJ1939VarDlc" BO_ 2566897729 1;
BA_ "CI_MsgDefinition" BO_ 2566857793 "Iveco Proprietary";
BA_ "CI_MsgId" BO_ 2566857793 9688;
BA_ "CI_MsgName" BO_ 2566857793 "PB_RadioStsEx_41 - Radio Status (Extended)";
BA_ "GenMsgCycleTime" BO_ 2566857793 1000;
BA_ "GenMsgCycleTimeFast" BO_ 2566857793 1000;
BA_ "GenMsgDelayTime" BO_ 2566857793 100;
BA_ "GenMsgSendType" BO_ 2566857793 0;
BA_ "GenMsgStartDelayTime" BO_ 2566857793 251;
BA_ "CI_MsgDefinition" BO_ 2583662631 "Iveco Daily Electric";
BA_ "CI_MsgId" BO_ 2583662631 35253;
BA_ "CI_MsgName" BO_ 2583662631 "PB_RCH_27 - Proprietary B - Remote Charging Handshake";
BA_ "GenMsgCycleTime" BO_ 2583662631 1000;
BA_ "GenMsgCycleTimeFast" BO_ 2583662631 1000;
BA_ "GenMsgDelayTime" BO_ 2583662631 500;
BA_ "GenMsgSendType" BO_ 2583662631 0;
BA_ "GenMsgStartDelayTime" BO_ 2583662631 291;
BA_ "CI_MsgDefinition" BO_ 2583662666 "Iveco Daily Electric";
BA_ "CI_MsgId" BO_ 2583662666 35256;
BA_ "CI_MsgName" BO_ 2583662666 "PB_RCH_4A - Proprietary B - Remote Charging Handshake";
BA_ "CI_MsgDefinition" BO_ 2583666250 "Iveco Daily Electric";
BA_ "CI_MsgId" BO_ 2583666250 41809;
BA_ "CI_MsgName" BO_ 2583666250 "PB_RemoteRequest_4A - Proprietary B - Remote Request";
BA_ "GenMsgCycleTime" BO_ 2583666250 1000;
BA_ "GenMsgCycleTimeFast" BO_ 2583666250 1000;
BA_ "GenMsgDelayTime" BO_ 2583666250 500;
BA_ "GenMsgSendType" BO_ 2583666250 0;
BA_ "GenMsgStartDelayTime" BO_ 2583666250 34;
BA_ "CI_MsgDefinition" BO_ 2566910497 "Iveco Daily Proprietary";
BA_ "CI_MsgId" BO_ 2566910497 42624;
BA_ "CI_MsgName" BO_ 2566910497 "PB_RER_21 - Proprietary B - Remote or External Request";
BA_ "GenMsgCycleTime" BO_ 2566910497 5000;
BA_ "GenMsgCycleTimeFast" BO_ 2566910497 5000;
BA_ "GenMsgDelayTime" BO_ 2566910497 2500;
BA_ "GenMsgSendType" BO_ 2566910497 0;
BA_ "GenMsgStartDelayTime" BO_ 2566910497 338;
BA_ "CI_MsgDefinition" BO_ 2650776966 "Iveco Daily Electric";
BA_ "CI_MsgId" BO_ 2650776966 45466;
BA_ "CI_MsgName" BO_ 2650776966 "PB_ROC_86 - Proprietary B - Relay Operation Counter";
BA_ "GenMsgCycleTime" BO_ 2650776966 600000;
BA_ "GenMsgCycleTimeFast" BO_ 2650776966 600000;
BA_ "GenMsgDelayTime" BO_ 2650776966 300000;
BA_ "GenMsgSendType" BO_ 2650776966 0;
BA_ "GenMsgStartDelayTime" BO_ 2650776966 381;
BA_ "CI_ParId" SG_ 2583663895 BSGTrqHighLowMode "ID2583";
BA_ "CI_SigId" SG_ 2583663895 BSGTrqHighLowMode 45391;
BA_ "CI_SigName" SG_ 2583663895 BSGTrqHighLowMode "Belt Starter Generator Torque High Low Mode";
BA_ "GenSigSendType" SG_ 2583663895 BSGTrqHighLowMode 3;
BA_ "GenSigTimeoutTime_PCM" SG_ 2583663895 BSGTrqHighLowMode 2500;
BA_ "SigType" SG_ 2583663895 BSGTrqHighLowMode 4;
BA_ "CI_ParId" SG_ 2583663895 BuzVolWarn "ID2282";
BA_ "CI_SigId" SG_ 2583663895 BuzVolWarn 42691;
BA_ "CI_SigName" SG_ 2583663895 BuzVolWarn "Buzzer Volume Warning";
BA_ "GenSigSendType" SG_ 2583663895 BuzVolWarn 3;
BA_ "GenSigTimeoutTime_PCM" SG_ 2583663895 BuzVolWarn 2500;
BA_ "CI_ParId" SG_ 2583663895 BuzVolBtn "ID2281";
BA_ "CI_SigId" SG_ 2583663895 BuzVolBtn 42690;
BA_ "CI_SigName" SG_ 2583663895 BuzVolBtn "Buzzer Volume Button";
BA_ "GenSigSendType" SG_ 2583663895 BuzVolBtn 3;
BA_ "GenSigTimeoutTime_PCM" SG_ 2583663895 BuzVolBtn 2500;
BA_ "CI_ParId" SG_ 2583663895 WelcomeLightCfg "ID2486";
BA_ "CI_SigId" SG_ 2583663895 WelcomeLightCfg 44600;
BA_ "CI_SigName" SG_ 2583663895 WelcomeLightCfg "Welcome Lights Configuration";
BA_ "GenSigSendType" SG_ 2583663895 WelcomeLightCfg 3;
BA_ "GenSigTimeoutTime_PCM" SG_ 2583663895 WelcomeLightCfg 2500;
BA_ "SigType" SG_ 2583663895 WelcomeLightCfg 4;
BA_ "CI_ParId" SG_ 2583663895 PwrModeSts_FF9517 "ID2266";
BA_ "CI_SigId" SG_ 2583663895 PwrModeSts_FF9517 42689;
BA_ "CI_SigName" SG_ 2583663895 PwrModeSts_FF9517 "Power Mode Status";
BA_ "GenSigSendType" SG_ 2583663895 PwrModeSts_FF9517 3;
BA_ "GenSigTimeoutTime_PCM" SG_ 2583663895 PwrModeSts_FF9517 2500;
BA_ "SigType" SG_ 2583663895 PwrModeSts_FF9517 4;
BA_ "CI_ParId" SG_ 2583663895 SeatBeltRemindEna "ID2280";
BA_ "CI_SigId" SG_ 2583663895 SeatBeltRemindEna 42688;
BA_ "CI_SigName" SG_ 2583663895 SeatBeltRemindEna "Seat Belt Reminder Enable";
BA_ "GenSigSendType" SG_ 2583663895 SeatBeltRemindEna 3;
BA_ "GenSigTimeoutTime_PCM" SG_ 2583663895 SeatBeltRemindEna 2500;
BA_ "SigType" SG_ 2583663895 SeatBeltRemindEna 4;
BA_ "CI_ParId" SG_ 2583663895 DrivRespOnPtoMissIntrp "ID2279";
BA_ "CI_SigId" SG_ 2583663895 DrivRespOnPtoMissIntrp 42687;
BA_ "CI_SigName" SG_ 2583663895 DrivRespOnPtoMissIntrp "Driver Response on PTO Mission Interruption";
BA_ "GenSigSendType" SG_ 2583663895 DrivRespOnPtoMissIntrp 3;
BA_ "GenSigStartValue" SG_ 2583663895 DrivRespOnPtoMissIntrp 3;
BA_ "GenSigTimeoutTime_PCM" SG_ 2583663895 DrivRespOnPtoMissIntrp 2500;
BA_ "SigType" SG_ 2583663895 DrivRespOnPtoMissIntrp 4;
BA_ "CI_ParId" SG_ 2583663895 AirbagLampFail "ID2278";
BA_ "CI_SigId" SG_ 2583663895 AirbagLampFail 42686;
BA_ "CI_SigName" SG_ 2583663895 AirbagLampFail "Airbag Lamp Fail Status";
BA_ "GenSigSendType" SG_ 2583663895 AirbagLampFail 3;
BA_ "GenSigTimeoutTime_PCM" SG_ 2583663895 AirbagLampFail 2500;
BA_ "SigType" SG_ 2583663895 AirbagLampFail 4;
BA_ "CI_ParId" SG_ 2583663895 AbsLampFail "ID2277";
BA_ "CI_SigId" SG_ 2583663895 AbsLampFail 42685;
BA_ "CI_SigName" SG_ 2583663895 AbsLampFail "ABS Lamp Fail Status";
BA_ "GenSigSendType" SG_ 2583663895 AbsLampFail 3;
BA_ "GenSigTimeoutTime_PCM" SG_ 2583663895 AbsLampFail 2500;
BA_ "SigType" SG_ 2583663895 AbsLampFail 4;
BA_ "CI_ParId" SG_ 2583663895 EbdLampFail "ID2276";
BA_ "CI_SigId" SG_ 2583663895 EbdLampFail 42684;
BA_ "CI_SigName" SG_ 2583663895 EbdLampFail "EBD Lamp Fail Status";
BA_ "GenSigSendType" SG_ 2583663895 EbdLampFail 3;
BA_ "GenSigTimeoutTime_PCM" SG_ 2583663895 EbdLampFail 2500;
BA_ "SigType" SG_ 2583663895 EbdLampFail 4;
BA_ "CI_ParId" SG_ 2583663895 VdcLampFail "ID2275";
BA_ "CI_SigId" SG_ 2583663895 VdcLampFail 42683;
BA_ "CI_SigName" SG_ 2583663895 VdcLampFail "VDC Lamp Fail Status";
BA_ "GenSigSendType" SG_ 2583663895 VdcLampFail 3;
BA_ "GenSigTimeoutTime_PCM" SG_ 2583663895 VdcLampFail 2500;
BA_ "SigType" SG_ 2583663895 VdcLampFail 4;
BA_ "CI_ParId" SG_ 2583651623 ComVehSts "B047";
BA_ "CI_SigId" SG_ 2583651623 ComVehSts 39660;
BA_ "CI_SigName" SG_ 2583651623 ComVehSts "Common Vehicle State";
BA_ "GenSigTimeoutTime_PCM" SG_ 2583651623 ComVehSts 500;
BA_ "CI_ParId" SG_ 2583651623 SelGearPosInAt "B045";
BA_ "CI_SigId" SG_ 2583651623 SelGearPosInAt 39659;
BA_ "CI_SigName" SG_ 2583651623 SelGearPosInAt "Selected Gear Position in AT";
BA_ "GenSigTimeoutTime_PCM" SG_ 2583651623 SelGearPosInAt 500;
BA_ "CI_ParId" SG_ 2583651623 CentLckSts "B044";
BA_ "CI_SigId" SG_ 2583651623 CentLckSts 39658;
BA_ "CI_SigName" SG_ 2583651623 CentLckSts "Central Locking Status";
BA_ "GenSigTimeoutTime_PCM" SG_ 2583651623 CentLckSts 500;
BA_ "CI_ParId" SG_ 2583651623 CharginStopReq "B043";
BA_ "CI_SigId" SG_ 2583651623 CharginStopReq 39657;
BA_ "CI_SigName" SG_ 2583651623 CharginStopReq "Chargin Stop Request";
BA_ "GenSigTimeoutTime_PCM" SG_ 2583651623 CharginStopReq 500;
BA_ "CI_ParId" SG_ 2583651623 ChgStopAndUnlckChgPlugReq "B042";
BA_ "CI_SigId" SG_ 2583651623 ChgStopAndUnlckChgPlugReq 39656;
BA_ "CI_SigName" SG_ 2583651623 ChgStopAndUnlckChgPlugReq "Charging Stop and Unlock Charge Plug Request";
BA_ "GenSigTimeoutTime_PCM" SG_ 2583651623 ChgStopAndUnlckChgPlugReq 500;
BA_ "CI_ParId" SG_ 2650776710 SlowChgCnt "MV055";
BA_ "CI_SigId" SG_ 2650776710 SlowChgCnt 44412;
BA_ "CI_SigName" SG_ 2650776710 SlowChgCnt "Slow Charge Counter";
BA_ "GenSigTimeoutTime_PCM" SG_ 2650776710 SlowChgCnt 3000000;
BA_ "CI_ParId" SG_ 2650776710 FastChgCnt "MV054";
BA_ "CI_SigId" SG_ 2650776710 FastChgCnt 44411;
BA_ "CI_SigName" SG_ 2650776710 FastChgCnt "Fast Charge Counter";
BA_ "GenSigTimeoutTime_PCM" SG_ 2650776710 FastChgCnt 3000000;
BA_ "CI_ParId" SG_ 2650776710 RegOver150A_h "MV011";
BA_ "CI_SigId" SG_ 2650776710 RegOver150A_h 44039;
BA_ "CI_SigName" SG_ 2650776710 RegOver150A_h "RegOver150A_h";
BA_ "GenSigTimeoutTime_PCM" SG_ 2650776710 RegOver150A_h 3000000;
BA_ "SigType" SG_ 2650776710 RegOver150A_h 1;
BA_ "CI_ParId" SG_ 2650776710 DsgOver280A_h "MV010";
BA_ "CI_SigId" SG_ 2650776710 DsgOver280A_h 44038;
BA_ "CI_SigName" SG_ 2650776710 DsgOver280A_h "DsgOver280A_h";
BA_ "GenSigTimeoutTime_PCM" SG_ 2650776710 DsgOver280A_h 3000000;
BA_ "SigType" SG_ 2650776710 DsgOver280A_h 1;
BA_ "CI_ParId" SG_ 2650776711 SlowChgCnt_FFA487 "MV055";
BA_ "CI_SigId" SG_ 2650776711 SlowChgCnt_FFA487 44414;
BA_ "CI_SigName" SG_ 2650776711 SlowChgCnt_FFA487 "Slow Charge Counter";
BA_ "GenSigTimeoutTime_PCM" SG_ 2650776711 SlowChgCnt_FFA487 3000000;
BA_ "CI_ParId" SG_ 2650776711 FastChgCnt_FFA487 "MV054";
BA_ "CI_SigId" SG_ 2650776711 FastChgCnt_FFA487 44413;
BA_ "CI_SigName" SG_ 2650776711 FastChgCnt_FFA487 "Fast Charge Counter";
BA_ "GenSigTimeoutTime_PCM" SG_ 2650776711 FastChgCnt_FFA487 3000000;
BA_ "CI_ParId" SG_ 2650776711 RegOver150A_h_FFA487 "MV011";
BA_ "CI_SigId" SG_ 2650776711 RegOver150A_h_FFA487 44042;
BA_ "CI_SigName" SG_ 2650776711 RegOver150A_h_FFA487 "RegOver150A_h";
BA_ "GenSigTimeoutTime_PCM" SG_ 2650776711 RegOver150A_h_FFA487 3000000;
BA_ "SigType" SG_ 2650776711 RegOver150A_h_FFA487 1;
BA_ "CI_ParId" SG_ 2650776711 DsgOver280A_h_FFA487 "MV010";
BA_ "CI_SigId" SG_ 2650776711 DsgOver280A_h_FFA487 44041;
BA_ "CI_SigName" SG_ 2650776711 DsgOver280A_h_FFA487 "DsgOver280A_h";
BA_ "GenSigTimeoutTime_PCM" SG_ 2650776711 DsgOver280A_h_FFA487 3000000;
BA_ "SigType" SG_ 2650776711 DsgOver280A_h_FFA487 1;
BA_ "CI_ParId" SG_ 2650776820 SlowChgCnt_FFA4F4 "MV055";
BA_ "CI_SigId" SG_ 2650776820 SlowChgCnt_FFA4F4 44406;
BA_ "CI_SigName" SG_ 2650776820 SlowChgCnt_FFA4F4 "Slow Charge Counter";
BA_ "GenSigTimeoutTime_PCM" SG_ 2650776820 SlowChgCnt_FFA4F4 3000000;
BA_ "CI_ParId" SG_ 2650776820 FastChgCnt_FFA4F4 "MV054";
BA_ "CI_SigId" SG_ 2650776820 FastChgCnt_FFA4F4 44405;
BA_ "CI_SigName" SG_ 2650776820 FastChgCnt_FFA4F4 "Fast Charge Counter";
BA_ "GenSigTimeoutTime_PCM" SG_ 2650776820 FastChgCnt_FFA4F4 3000000;
BA_ "CI_ParId" SG_ 2650776820 RegOver150A_h_FFA4F4 "MV011";
BA_ "CI_SigId" SG_ 2650776820 RegOver150A_h_FFA4F4 44030;
BA_ "CI_SigName" SG_ 2650776820 RegOver150A_h_FFA4F4 "RegOver150A_h";
BA_ "GenSigTimeoutTime_PCM" SG_ 2650776820 RegOver150A_h_FFA4F4 3000000;
BA_ "SigType" SG_ 2650776820 RegOver150A_h_FFA4F4 1;
BA_ "CI_ParId" SG_ 2650776820 DsgOver280A_h_FFA4F4 "MV010";
BA_ "CI_SigId" SG_ 2650776820 DsgOver280A_h_FFA4F4 44029;
BA_ "CI_SigName" SG_ 2650776820 DsgOver280A_h_FFA4F4 "DsgOver280A_h";
BA_ "GenSigTimeoutTime_PCM" SG_ 2650776820 DsgOver280A_h_FFA4F4 3000000;
BA_ "SigType" SG_ 2650776820 DsgOver280A_h_FFA4F4 1;
BA_ "CI_ParId" SG_ 2650776821 SlowChgCnt_FFA4F5 "MV055";
BA_ "CI_SigId" SG_ 2650776821 SlowChgCnt_FFA4F5 44408;
BA_ "CI_SigName" SG_ 2650776821 SlowChgCnt_FFA4F5 "Slow Charge Counter";
BA_ "GenSigTimeoutTime_PCM" SG_ 2650776821 SlowChgCnt_FFA4F5 3000000;
BA_ "CI_ParId" SG_ 2650776821 FastChgCnt_FFA4F5 "MV054";
BA_ "CI_SigId" SG_ 2650776821 FastChgCnt_FFA4F5 44407;
BA_ "CI_SigName" SG_ 2650776821 FastChgCnt_FFA4F5 "Fast Charge Counter";
BA_ "GenSigTimeoutTime_PCM" SG_ 2650776821 FastChgCnt_FFA4F5 3000000;
BA_ "CI_ParId" SG_ 2650776821 RegOver150A_h_FFA4F5 "MV011";
BA_ "CI_SigId" SG_ 2650776821 RegOver150A_h_FFA4F5 44033;
BA_ "CI_SigName" SG_ 2650776821 RegOver150A_h_FFA4F5 "RegOver150A_h";
BA_ "GenSigTimeoutTime_PCM" SG_ 2650776821 RegOver150A_h_FFA4F5 3000000;
BA_ "SigType" SG_ 2650776821 RegOver150A_h_FFA4F5 1;
BA_ "CI_ParId" SG_ 2650776821 DsgOver280A_h_FFA4F5 "MV010";
BA_ "CI_SigId" SG_ 2650776821 DsgOver280A_h_FFA4F5 44032;
BA_ "CI_SigName" SG_ 2650776821 DsgOver280A_h_FFA4F5 "DsgOver280A_h";
BA_ "GenSigTimeoutTime_PCM" SG_ 2650776821 DsgOver280A_h_FFA4F5 3000000;
BA_ "SigType" SG_ 2650776821 DsgOver280A_h_FFA4F5 1;
BA_ "CI_ParId" SG_ 2650776822 SlowChgCnt_FFA4F6 "MV055";
BA_ "CI_SigId" SG_ 2650776822 SlowChgCnt_FFA4F6 44410;
BA_ "CI_SigName" SG_ 2650776822 SlowChgCnt_FFA4F6 "Slow Charge Counter";
BA_ "GenSigTimeoutTime_PCM" SG_ 2650776822 SlowChgCnt_FFA4F6 3000000;
BA_ "CI_ParId" SG_ 2650776822 FastChgCnt_FFA4F6 "MV054";
BA_ "CI_SigId" SG_ 2650776822 FastChgCnt_FFA4F6 44409;
BA_ "CI_SigName" SG_ 2650776822 FastChgCnt_FFA4F6 "Fast Charge Counter";
BA_ "GenSigTimeoutTime_PCM" SG_ 2650776822 FastChgCnt_FFA4F6 3000000;
BA_ "CI_ParId" SG_ 2650776822 RegOver150A_h_FFA4F6 "MV011";
BA_ "CI_SigId" SG_ 2650776822 RegOver150A_h_FFA4F6 44036;
BA_ "CI_SigName" SG_ 2650776822 RegOver150A_h_FFA4F6 "RegOver150A_h";
BA_ "GenSigTimeoutTime_PCM" SG_ 2650776822 RegOver150A_h_FFA4F6 3000000;
BA_ "SigType" SG_ 2650776822 RegOver150A_h_FFA4F6 1;
BA_ "CI_ParId" SG_ 2650776822 DsgOver280A_h_FFA4F6 "MV010";
BA_ "CI_SigId" SG_ 2650776822 DsgOver280A_h_FFA4F6 44035;
BA_ "CI_SigName" SG_ 2650776822 DsgOver280A_h_FFA4F6 "DsgOver280A_h";
BA_ "GenSigTimeoutTime_PCM" SG_ 2650776822 DsgOver280A_h_FFA4F6 3000000;
BA_ "SigType" SG_ 2650776822 DsgOver280A_h_FFA4F6 1;
BA_ "CI_ParId" SG_ 2566904343 EcoMode_FFDA17 "I808";
BA_ "CI_SigId" SG_ 2566904343 EcoMode_FFDA17 8852;
BA_ "CI_SigName" SG_ 2566904343 EcoMode_FFDA17 "Eco Mode";
BA_ "GenSigSendType" SG_ 2566904343 EcoMode_FFDA17 3;
BA_ "GenSigTimeoutTime_PCM" SG_ 2566904343 EcoMode_FFDA17 5000;
BA_ "SigType" SG_ 2566904343 EcoMode_FFDA17 4;
BA_ "CI_ParId" SG_ 2566904345 AcEvapTemp "I275";
BA_ "CI_SigId" SG_ 2566904345 AcEvapTemp 8839;
BA_ "CI_SigName" SG_ 2566904345 AcEvapTemp "A/C Evaporator Temperature";
BA_ "GenSigSendType" SG_ 2566904345 AcEvapTemp 3;
BA_ "GenSigTimeoutTime_PCM" SG_ 2566904345 AcEvapTemp 5000;
BA_ "SigType" SG_ 2566904345 AcEvapTemp 1;
BA_ "CI_ParId" SG_ 2566904345 AcPcBlowSpeed "I274";
BA_ "CI_SigId" SG_ 2566904345 AcPcBlowSpeed 8836;
BA_ "CI_SigName" SG_ 2566904345 AcPcBlowSpeed "A/C Percent Blower Speed";
BA_ "GenSigSendType" SG_ 2566904345 AcPcBlowSpeed 3;
BA_ "GenSigTimeoutTime_PCM" SG_ 2566904345 AcPcBlowSpeed 5000;
BA_ "SigType" SG_ 2566904345 AcPcBlowSpeed 1;
BA_ "CI_ParId" SG_ 2566904345 EcoMode_FFDA19 "I808";
BA_ "CI_SigId" SG_ 2566904345 EcoMode_FFDA19 8835;
BA_ "CI_SigName" SG_ 2566904345 EcoMode_FFDA19 "Eco Mode";
BA_ "GenSigSendType" SG_ 2566904345 EcoMode_FFDA19 3;
BA_ "GenSigTimeoutTime_PCM" SG_ 2566904345 EcoMode_FFDA19 5000;
BA_ "SigType" SG_ 2566904345 EcoMode_FFDA19 4;
BA_ "CI_ParId" SG_ 2566904345 ClimaCtrlVentilMode_FFDA19 "I495";
BA_ "CI_SigId" SG_ 2566904345 ClimaCtrlVentilMode_FFDA19 8834;
BA_ "CI_SigName" SG_ 2566904345 ClimaCtrlVentilMode_FFDA19 "Climate Control Ventilation Mode";
BA_ "GenSigSendType" SG_ 2566904345 ClimaCtrlVentilMode_FFDA19 3;
BA_ "GenSigTimeoutTime_PCM" SG_ 2566904345 ClimaCtrlVentilMode_FFDA19 5000;
BA_ "SigType" SG_ 2566904345 ClimaCtrlVentilMode_FFDA19 4;
BA_ "CI_ParId" SG_ 2566904345 AcReqDistrFt "I270";
BA_ "CI_SigId" SG_ 2566904345 AcReqDistrFt 8831;
BA_ "CI_SigName" SG_ 2566904345 AcReqDistrFt "A/C Requested Distribution - Feet";
BA_ "GenSigSendType" SG_ 2566904345 AcReqDistrFt 3;
BA_ "GenSigTimeoutTime_PCM" SG_ 2566904345 AcReqDistrFt 5000;
BA_ "SigType" SG_ 2566904345 AcReqDistrFt 4;
BA_ "CI_ParId" SG_ 2566904345 AcReqDistrCentre "I269";
BA_ "CI_SigId" SG_ 2566904345 AcReqDistrCentre 8830;
BA_ "CI_SigName" SG_ 2566904345 AcReqDistrCentre "A/C Requested Distribution - Centre";
BA_ "GenSigSendType" SG_ 2566904345 AcReqDistrCentre 3;
BA_ "GenSigTimeoutTime_PCM" SG_ 2566904345 AcReqDistrCentre 5000;
BA_ "SigType" SG_ 2566904345 AcReqDistrCentre 4;
BA_ "CI_ParId" SG_ 2566904345 AcReqDistrTop "I268";
BA_ "CI_SigId" SG_ 2566904345 AcReqDistrTop 8829;
BA_ "CI_SigName" SG_ 2566904345 AcReqDistrTop "A/C Requested Distribution - Top";
BA_ "GenSigSendType" SG_ 2566904345 AcReqDistrTop 3;
BA_ "GenSigTimeoutTime_PCM" SG_ 2566904345 AcReqDistrTop 5000;
BA_ "SigType" SG_ 2566904345 AcReqDistrTop 4;
BA_ "CI_ParId" SG_ 2566904345 AcReqDistrWindsh "I267";
BA_ "CI_SigId" SG_ 2566904345 AcReqDistrWindsh 8828;
BA_ "CI_SigName" SG_ 2566904345 AcReqDistrWindsh "A/C Requested Distribution - Windscreen";
BA_ "GenSigSendType" SG_ 2566904345 AcReqDistrWindsh 3;
BA_ "GenSigTimeoutTime_PCM" SG_ 2566904345 AcReqDistrWindsh 5000;
BA_ "SigType" SG_ 2566904345 AcReqDistrWindsh 4;
BA_ "CI_ParId" SG_ 2566904345 AcComprDis "I693";
BA_ "CI_SigId" SG_ 2566904345 AcComprDis 8827;
BA_ "CI_SigName" SG_ 2566904345 AcComprDis "A/C Compressor Disable";
BA_ "GenSigSendType" SG_ 2566904345 AcComprDis 3;
BA_ "GenSigTimeoutTime_PCM" SG_ 2566904345 AcComprDis 5000;
BA_ "SigType" SG_ 2566904345 AcComprDis 4;
BA_ "CI_ParId" SG_ 2566904345 AcDurMode "I425";
BA_ "CI_SigId" SG_ 2566904345 AcDurMode 8826;
BA_ "CI_SigName" SG_ 2566904345 AcDurMode "A/C Duration Mode";
BA_ "GenSigSendType" SG_ 2566904345 AcDurMode 3;
BA_ "GenSigTimeoutTime_PCM" SG_ 2566904345 AcDurMode 5000;
BA_ "SigType" SG_ 2566904345 AcDurMode 4;
BA_ "CI_ParId" SG_ 2566904345 AcReqRecircMode "I266";
BA_ "CI_SigId" SG_ 2566904345 AcReqRecircMode 8825;
BA_ "CI_SigName" SG_ 2566904345 AcReqRecircMode "A/C Requested Recirculation Mode";
BA_ "GenSigSendType" SG_ 2566904345 AcReqRecircMode 3;
BA_ "GenSigTimeoutTime_PCM" SG_ 2566904345 AcReqRecircMode 5000;
BA_ "CI_ParId" SG_ 2566904345 AcCompr "I011";
BA_ "CI_SigId" SG_ 2566904345 AcCompr 8824;
BA_ "CI_SigName" SG_ 2566904345 AcCompr "A/C Compressor";
BA_ "GenSigSendType" SG_ 2566904345 AcCompr 3;
BA_ "GenSigTimeoutTime_PCM" SG_ 2566904345 AcCompr 5000;
BA_ "SigType" SG_ 2566904345 AcCompr 4;
BA_ "CI_ParId" SG_ 2566904345 AcMaxDefrost "I362";
BA_ "CI_SigId" SG_ 2566904345 AcMaxDefrost 8823;
BA_ "CI_SigName" SG_ 2566904345 AcMaxDefrost "A/C Max Defrost";
BA_ "GenSigSendType" SG_ 2566904345 AcMaxDefrost 3;
BA_ "GenSigTimeoutTime_PCM" SG_ 2566904345 AcMaxDefrost 5000;
BA_ "SigType" SG_ 2566904345 AcMaxDefrost 4;
BA_ "CI_ParId" SG_ 2566904345 AcCtrlMode "I264";
BA_ "CI_SigId" SG_ 2566904345 AcCtrlMode 8822;
BA_ "CI_SigName" SG_ 2566904345 AcCtrlMode "A/C Control Mode";
BA_ "GenSigSendType" SG_ 2566904345 AcCtrlMode 3;
BA_ "GenSigTimeoutTime_PCM" SG_ 2566904345 AcCtrlMode 5000;
BA_ "CI_ParId" SG_ 2566904353 AcEvapTemp_FFDA21 "I275";
BA_ "CI_SigId" SG_ 2566904353 AcEvapTemp_FFDA21 8870;
BA_ "CI_SigName" SG_ 2566904353 AcEvapTemp_FFDA21 "A/C Evaporator Temperature";
BA_ "GenSigSendType" SG_ 2566904353 AcEvapTemp_FFDA21 3;
BA_ "GenSigTimeoutTime_PCM" SG_ 2566904353 AcEvapTemp_FFDA21 5000;
BA_ "SigType" SG_ 2566904353 AcEvapTemp_FFDA21 1;
BA_ "CI_ParId" SG_ 2566904353 AcPcBlowSpeed_FFDA21 "I274";
BA_ "CI_SigId" SG_ 2566904353 AcPcBlowSpeed_FFDA21 8867;
BA_ "CI_SigName" SG_ 2566904353 AcPcBlowSpeed_FFDA21 "A/C Percent Blower Speed";
BA_ "GenSigSendType" SG_ 2566904353 AcPcBlowSpeed_FFDA21 3;
BA_ "GenSigTimeoutTime_PCM" SG_ 2566904353 AcPcBlowSpeed_FFDA21 5000;
BA_ "SigType" SG_ 2566904353 AcPcBlowSpeed_FFDA21 1;
BA_ "CI_ParId" SG_ 2566904353 EcoMode_FFDA21 "I808";
BA_ "CI_SigId" SG_ 2566904353 EcoMode_FFDA21 8866;
BA_ "CI_SigName" SG_ 2566904353 EcoMode_FFDA21 "Eco Mode";
BA_ "GenSigSendType" SG_ 2566904353 EcoMode_FFDA21 3;
BA_ "GenSigTimeoutTime_PCM" SG_ 2566904353 EcoMode_FFDA21 5000;
BA_ "SigType" SG_ 2566904353 EcoMode_FFDA21 4;
BA_ "CI_ParId" SG_ 2566904353 ClimaCtrlVentilMode_FFDA21 "I495";
BA_ "CI_SigId" SG_ 2566904353 ClimaCtrlVentilMode_FFDA21 8865;
BA_ "CI_SigName" SG_ 2566904353 ClimaCtrlVentilMode_FFDA21 "Climate Control Ventilation Mode";
BA_ "GenSigSendType" SG_ 2566904353 ClimaCtrlVentilMode_FFDA21 3;
BA_ "GenSigTimeoutTime_PCM" SG_ 2566904353 ClimaCtrlVentilMode_FFDA21 5000;
BA_ "SigType" SG_ 2566904353 ClimaCtrlVentilMode_FFDA21 4;
BA_ "CI_ParId" SG_ 2566904353 AcBlowSpeedInc_Dec "I1005";
BA_ "CI_SigId" SG_ 2566904353 AcBlowSpeedInc_Dec 43955;
BA_ "CI_SigName" SG_ 2566904353 AcBlowSpeedInc_Dec "A/C Blower Speed Increment/Decrement";
BA_ "GenSigSendType" SG_ 2566904353 AcBlowSpeedInc_Dec 3;
BA_ "GenSigTimeoutTime_PCM" SG_ 2566904353 AcBlowSpeedInc_Dec 5000;
BA_ "SigType" SG_ 2566904353 AcBlowSpeedInc_Dec 4;
BA_ "CI_ParId" SG_ 2566904353 AcTempInc_Dec "I1004";
BA_ "CI_SigId" SG_ 2566904353 AcTempInc_Dec 43954;
BA_ "CI_SigName" SG_ 2566904353 AcTempInc_Dec "A/C Temperature Increment/Decrement ";
BA_ "GenSigSendType" SG_ 2566904353 AcTempInc_Dec 3;
BA_ "GenSigTimeoutTime_PCM" SG_ 2566904353 AcTempInc_Dec 5000;
BA_ "SigType" SG_ 2566904353 AcTempInc_Dec 4;
BA_ "CI_ParId" SG_ 2566904353 AcReqDistrFt_FFDA21 "I270";
BA_ "CI_SigId" SG_ 2566904353 AcReqDistrFt_FFDA21 8862;
BA_ "CI_SigName" SG_ 2566904353 AcReqDistrFt_FFDA21 "A/C Requested Distribution - Feet";
BA_ "GenSigSendType" SG_ 2566904353 AcReqDistrFt_FFDA21 3;
BA_ "GenSigTimeoutTime_PCM" SG_ 2566904353 AcReqDistrFt_FFDA21 5000;
BA_ "SigType" SG_ 2566904353 AcReqDistrFt_FFDA21 4;
BA_ "CI_ParId" SG_ 2566904353 AcReqDistrCentre_FFDA21 "I269";
BA_ "CI_SigId" SG_ 2566904353 AcReqDistrCentre_FFDA21 8861;
BA_ "CI_SigName" SG_ 2566904353 AcReqDistrCentre_FFDA21 "A/C Requested Distribution - Centre";
BA_ "GenSigSendType" SG_ 2566904353 AcReqDistrCentre_FFDA21 3;
BA_ "GenSigTimeoutTime_PCM" SG_ 2566904353 AcReqDistrCentre_FFDA21 5000;
BA_ "SigType" SG_ 2566904353 AcReqDistrCentre_FFDA21 4;
BA_ "CI_ParId" SG_ 2566904353 AcReqDistrTop_FFDA21 "I268";
BA_ "CI_SigId" SG_ 2566904353 AcReqDistrTop_FFDA21 8860;
BA_ "CI_SigName" SG_ 2566904353 AcReqDistrTop_FFDA21 "A/C Requested Distribution - Top";
BA_ "GenSigSendType" SG_ 2566904353 AcReqDistrTop_FFDA21 3;
BA_ "GenSigTimeoutTime_PCM" SG_ 2566904353 AcReqDistrTop_FFDA21 5000;
BA_ "SigType" SG_ 2566904353 AcReqDistrTop_FFDA21 4;
BA_ "CI_ParId" SG_ 2566904353 AcReqDistrWindsh_FFDA21 "I267";
BA_ "CI_SigId" SG_ 2566904353 AcReqDistrWindsh_FFDA21 8859;
BA_ "CI_SigName" SG_ 2566904353 AcReqDistrWindsh_FFDA21 "A/C Requested Distribution - Windscreen";
BA_ "GenSigSendType" SG_ 2566904353 AcReqDistrWindsh_FFDA21 3;
BA_ "GenSigTimeoutTime_PCM" SG_ 2566904353 AcReqDistrWindsh_FFDA21 5000;
BA_ "SigType" SG_ 2566904353 AcReqDistrWindsh_FFDA21 4;
BA_ "CI_ParId" SG_ 2566904353 AcDurMode_FFDA21 "I425";
BA_ "CI_SigId" SG_ 2566904353 AcDurMode_FFDA21 8858;
BA_ "CI_SigName" SG_ 2566904353 AcDurMode_FFDA21 "A/C Duration Mode";
BA_ "GenSigSendType" SG_ 2566904353 AcDurMode_FFDA21 3;
BA_ "GenSigTimeoutTime_PCM" SG_ 2566904353 AcDurMode_FFDA21 5000;
BA_ "SigType" SG_ 2566904353 AcDurMode_FFDA21 4;
BA_ "CI_ParId" SG_ 2566904353 AcReqRecircMode_FFDA21 "I266";
BA_ "CI_SigId" SG_ 2566904353 AcReqRecircMode_FFDA21 8857;
BA_ "CI_SigName" SG_ 2566904353 AcReqRecircMode_FFDA21 "A/C Requested Recirculation Mode";
BA_ "GenSigSendType" SG_ 2566904353 AcReqRecircMode_FFDA21 3;
BA_ "GenSigTimeoutTime_PCM" SG_ 2566904353 AcReqRecircMode_FFDA21 5000;
BA_ "CI_ParId" SG_ 2566904353 AcCompr_FFDA21 "I011";
BA_ "CI_SigId" SG_ 2566904353 AcCompr_FFDA21 8856;
BA_ "CI_SigName" SG_ 2566904353 AcCompr_FFDA21 "A/C Compressor";
BA_ "GenSigSendType" SG_ 2566904353 AcCompr_FFDA21 3;
BA_ "GenSigTimeoutTime_PCM" SG_ 2566904353 AcCompr_FFDA21 5000;
BA_ "SigType" SG_ 2566904353 AcCompr_FFDA21 4;
BA_ "CI_ParId" SG_ 2566904353 AcMaxDefrost_FFDA21 "I362";
BA_ "CI_SigId" SG_ 2566904353 AcMaxDefrost_FFDA21 8855;
BA_ "CI_SigName" SG_ 2566904353 AcMaxDefrost_FFDA21 "A/C Max Defrost";
BA_ "GenSigSendType" SG_ 2566904353 AcMaxDefrost_FFDA21 3;
BA_ "GenSigTimeoutTime_PCM" SG_ 2566904353 AcMaxDefrost_FFDA21 5000;
BA_ "SigType" SG_ 2566904353 AcMaxDefrost_FFDA21 4;
BA_ "CI_ParId" SG_ 2566904353 AcCtrlMode_FFDA21 "I264";
BA_ "CI_SigId" SG_ 2566904353 AcCtrlMode_FFDA21 8854;
BA_ "CI_SigName" SG_ 2566904353 AcCtrlMode_FFDA21 "A/C Control Mode";
BA_ "GenSigSendType" SG_ 2566904353 AcCtrlMode_FFDA21 3;
BA_ "GenSigTimeoutTime_PCM" SG_ 2566904353 AcCtrlMode_FFDA21 5000;
BA_ "CI_ParId" SG_ 2566904394 EcoMode_FFDA4A "I808";
BA_ "CI_SigId" SG_ 2566904394 EcoMode_FFDA4A 43048;
BA_ "CI_SigName" SG_ 2566904394 EcoMode_FFDA4A "Eco Mode";
BA_ "SigType" SG_ 2566904394 EcoMode_FFDA4A 4;
BA_ "CI_ParId" SG_ 2566904394 AcBlowSpeedInc_Dec_FFDA4A "I1005";
BA_ "CI_SigId" SG_ 2566904394 AcBlowSpeedInc_Dec_FFDA4A 43952;
BA_ "CI_SigName" SG_ 2566904394 AcBlowSpeedInc_Dec_FFDA4A "A/C Blower Speed Increment/Decrement";
BA_ "SigType" SG_ 2566904394 AcBlowSpeedInc_Dec_FFDA4A 4;
BA_ "CI_ParId" SG_ 2566904394 AcTempInc_Dec_FFDA4A "I1004";
BA_ "CI_SigId" SG_ 2566904394 AcTempInc_Dec_FFDA4A 43951;
BA_ "CI_SigName" SG_ 2566904394 AcTempInc_Dec_FFDA4A "A/C Temperature Increment/Decrement ";
BA_ "SigType" SG_ 2566904394 AcTempInc_Dec_FFDA4A 4;
BA_ "CI_ParId" SG_ 2566904394 AcReqDistrFt_FFDA4A "I270";
BA_ "CI_SigId" SG_ 2566904394 AcReqDistrFt_FFDA4A 43044;
BA_ "CI_SigName" SG_ 2566904394 AcReqDistrFt_FFDA4A "A/C Requested Distribution - Feet";
BA_ "SigType" SG_ 2566904394 AcReqDistrFt_FFDA4A 4;
BA_ "CI_ParId" SG_ 2566904394 AcReqDistrCentre_FFDA4A "I269";
BA_ "CI_SigId" SG_ 2566904394 AcReqDistrCentre_FFDA4A 43043;
BA_ "CI_SigName" SG_ 2566904394 AcReqDistrCentre_FFDA4A "A/C Requested Distribution - Centre";
BA_ "SigType" SG_ 2566904394 AcReqDistrCentre_FFDA4A 4;
BA_ "CI_ParId" SG_ 2566904394 AcReqDistrTop_FFDA4A "I268";
BA_ "CI_SigId" SG_ 2566904394 AcReqDistrTop_FFDA4A 43042;
BA_ "CI_SigName" SG_ 2566904394 AcReqDistrTop_FFDA4A "A/C Requested Distribution - Top";
BA_ "SigType" SG_ 2566904394 AcReqDistrTop_FFDA4A 4;
BA_ "CI_ParId" SG_ 2566904394 AcReqRecircMode_FFDA4A "I266";
BA_ "CI_SigId" SG_ 2566904394 AcReqRecircMode_FFDA4A 43039;
BA_ "CI_SigName" SG_ 2566904394 AcReqRecircMode_FFDA4A "A/C Requested Recirculation Mode";
BA_ "CI_ParId" SG_ 2566904394 AcMaxDefrost_FFDA4A "I362";
BA_ "CI_SigId" SG_ 2566904394 AcMaxDefrost_FFDA4A 43037;
BA_ "CI_SigName" SG_ 2566904394 AcMaxDefrost_FFDA4A "A/C Max Defrost";
BA_ "SigType" SG_ 2566904394 AcMaxDefrost_FFDA4A 4;
BA_ "CI_ParId" SG_ 2566904394 AcCtrlMode_FFDA4A "I264";
BA_ "CI_SigId" SG_ 2566904394 AcCtrlMode_FFDA4A 43036;
BA_ "CI_SigName" SG_ 2566904394 AcCtrlMode_FFDA4A "A/C Control Mode";
BA_ "CI_ParId" SG_ 2382311251 Crc32 "ID2119";
BA_ "CI_SigId" SG_ 2382311251 Crc32 44424;
BA_ "CI_SigName" SG_ 2382311251 Crc32 "CRC-32";
BA_ "CI_ParId" SG_ 2382311251 MsgCnt_F2F53 "4206";
BA_ "CI_SigId" SG_ 2382311251 MsgCnt_F2F53 44423;
BA_ "CI_SigName" SG_ 2382311251 MsgCnt_F2F53 "Message Counter";
BA_ "SPN" SG_ 2382311251 MsgCnt_F2F53 4206;
BA_ "CI_ParId" SG_ 2382311251 SdmSevFault "ID2152";
BA_ "CI_SigId" SG_ 2382311251 SdmSevFault 44422;
BA_ "CI_SigName" SG_ 2382311251 SdmSevFault "SDM Severe Fault Status";
BA_ "GenSigTimeoutTime_PCM" SG_ 2382311251 SdmSevFault 2500;
BA_ "SigType" SG_ 2382311251 SdmSevFault 4;
BA_ "CI_ParId" SG_ 2382311251 SdmWarnFault "ID2151";
BA_ "CI_SigId" SG_ 2382311251 SdmWarnFault 44421;
BA_ "CI_SigName" SG_ 2382311251 SdmWarnFault "SDM Warning Fault Status";
BA_ "GenSigTimeoutTime_PCM" SG_ 2382311251 SdmWarnFault 2500;
BA_ "SigType" SG_ 2382311251 SdmWarnFault 4;
BA_ "CI_ParId" SG_ 2382311251 CrashSts "ID2143";
BA_ "CI_SigId" SG_ 2382311251 CrashSts 44416;
BA_ "CI_SigName" SG_ 2382311251 CrashSts "Crash Status";
BA_ "GenSigTimeoutTime_PCM" SG_ 2382311251 CrashSts 2500;
BA_ "SigType" SG_ 2382311251 CrashSts 4;
BA_ "CI_ParId" SG_ 2382311463 Crc32_F3027 "ID2119";
BA_ "CI_SigId" SG_ 2382311463 Crc32_F3027 41832;
BA_ "CI_SigName" SG_ 2382311463 Crc32_F3027 "CRC-32";
BA_ "GenSigTimeoutTime_PCM" SG_ 2382311463 Crc32_F3027 500;
BA_ "CI_ParId" SG_ 2382311463 MsgCnt_F3027 "4206";
BA_ "CI_SigId" SG_ 2382311463 MsgCnt_F3027 41831;
BA_ "CI_SigName" SG_ 2382311463 MsgCnt_F3027 "Message Counter";
BA_ "GenSigTimeoutTime_PCM" SG_ 2382311463 MsgCnt_F3027 500;
BA_ "SPN" SG_ 2382311463 MsgCnt_F3027 4206;
BA_ "CI_ParId" SG_ 2382311463 HighVCutOffSts "ID2148";
BA_ "CI_SigId" SG_ 2382311463 HighVCutOffSts 41828;
BA_ "CI_SigName" SG_ 2382311463 HighVCutOffSts "High Voltage Cut Off Status";
BA_ "GenSigTimeoutTime_PCM" SG_ 2382311463 HighVCutOffSts 500;
BA_ "SigType" SG_ 2382311463 HighVCutOffSts 4;
BA_ "CI_ParId" SG_ 2650750195 Crc32_FF3CF3 "ID2066";
BA_ "CI_SigId" SG_ 2650750195 Crc32_FF3CF3 40397;
BA_ "CI_SigName" SG_ 2650750195 Crc32_FF3CF3 "CRC 32";
BA_ "CI_ParId" SG_ 2650750195 MsgCnt8 "ID2065";
BA_ "CI_SigId" SG_ 2650750195 MsgCnt8 40396;
BA_ "CI_SigName" SG_ 2650750195 MsgCnt8 "Message Counter 8 bit";
BA_ "SigType" SG_ 2650750195 MsgCnt8 1;
BA_ "CI_ParId" SG_ 2650750195 HvessCellVminLim "8210";
BA_ "CI_SigId" SG_ 2650750195 HvessCellVminLim 40393;
BA_ "CI_SigName" SG_ 2650750195 HvessCellVminLim "HVESS Cell Minimum Voltage Limit";
BA_ "SPN" SG_ 2650750195 HvessCellVminLim 8210;
BA_ "SigType" SG_ 2650750195 HvessCellVminLim 1;
BA_ "CI_ParId" SG_ 2650750195 HvessCellVmaxLim "8209";
BA_ "CI_SigId" SG_ 2650750195 HvessCellVmaxLim 40392;
BA_ "CI_SigName" SG_ 2650750195 HvessCellVmaxLim "HVESS Cell Maximum Voltage Limit";
BA_ "SPN" SG_ 2650750195 HvessCellVmaxLim 8209;
BA_ "SigType" SG_ 2650750195 HvessCellVmaxLim 1;
BA_ "CI_ParId" SG_ 2650750195 HvessRecomMinOpTemp "8208";
BA_ "CI_SigId" SG_ 2650750195 HvessRecomMinOpTemp 40391;
BA_ "CI_SigName" SG_ 2650750195 HvessRecomMinOpTemp "HVESS Recommended Minimum Operating Temperature";
BA_ "SPN" SG_ 2650750195 HvessRecomMinOpTemp 8208;
BA_ "SigType" SG_ 2650750195 HvessRecomMinOpTemp 1;
BA_ "CI_ParId" SG_ 2650750195 HvessRecomMaxOpTemp "8120";
BA_ "CI_SigId" SG_ 2650750195 HvessRecomMaxOpTemp 40390;
BA_ "CI_SigName" SG_ 2650750195 HvessRecomMaxOpTemp "HVESS Recommended Maximum Operating Temperature";
BA_ "SPN" SG_ 2650750195 HvessRecomMaxOpTemp 8120;
BA_ "SigType" SG_ 2650750195 HvessRecomMaxOpTemp 1;
BA_ "CI_ParId" SG_ 2650750195 HvessRecomMaxSoc "8119";
BA_ "CI_SigId" SG_ 2650750195 HvessRecomMaxSoc 40389;
BA_ "CI_SigName" SG_ 2650750195 HvessRecomMaxSoc "HVESS Recommended Maximum State Of Charge";
BA_ "SPN" SG_ 2650750195 HvessRecomMaxSoc 8119;
BA_ "SigType" SG_ 2650750195 HvessRecomMaxSoc 1;
BA_ "CI_ParId" SG_ 2650750195 HvessRecomMinSoc "8118";
BA_ "CI_SigId" SG_ 2650750195 HvessRecomMinSoc 40388;
BA_ "CI_SigName" SG_ 2650750195 HvessRecomMinSoc "HVESS Recommended Minimum State Of Charge";
BA_ "SPN" SG_ 2650750195 HvessRecomMinSoc 8118;
BA_ "SigType" SG_ 2650750195 HvessRecomMinSoc 1;
BA_ "CI_ParId" SG_ 2650750195 HvessRecomMaxOpV "8117";
BA_ "CI_SigId" SG_ 2650750195 HvessRecomMaxOpV 40387;
BA_ "CI_SigName" SG_ 2650750195 HvessRecomMaxOpV "HVESS Recommended Maximum Operating Voltage";
BA_ "SPN" SG_ 2650750195 HvessRecomMaxOpV 8117;
BA_ "SigType" SG_ 2650750195 HvessRecomMaxOpV 1;
BA_ "CI_ParId" SG_ 2650750195 HvessRecomMinOpV "8116";
BA_ "CI_SigId" SG_ 2650750195 HvessRecomMinOpV 40386;
BA_ "CI_SigName" SG_ 2650750195 HvessRecomMinOpV "HVESS Recommended Minimum Operating Voltage";
BA_ "SPN" SG_ 2650750195 HvessRecomMinOpV 8116;
BA_ "SigType" SG_ 2650750195 HvessRecomMinOpV 1;
BA_ "CI_ParId" SG_ 2650750195 HvessNomV "8115";
BA_ "CI_SigId" SG_ 2650750195 HvessNomV 40385;
BA_ "CI_SigName" SG_ 2650750195 HvessNomV "HVESS Nominal Voltage";
BA_ "SPN" SG_ 2650750195 HvessNomV 8115;
BA_ "SigType" SG_ 2650750195 HvessNomV 1;
BA_ "CI_ParId" SG_ 2583627910 PackDcirSts "ID2594";
BA_ "CI_SigId" SG_ 2583627910 PackDcirSts 45490;
BA_ "CI_SigName" SG_ 2583627910 PackDcirSts "Pack DCIR Status";
BA_ "GenSigTimeoutTime_PCM" SG_ 2583627910 PackDcirSts 1250;
BA_ "SigType" SG_ 2583627910 PackDcirSts 4;
BA_ "CI_ParId" SG_ 2583627910 ThermEvtCause "ID2575";
BA_ "CI_SigId" SG_ 2583627910 ThermEvtCause 45352;
BA_ "CI_SigName" SG_ 2583627910 ThermEvtCause "Thermal Event Cause";
BA_ "GenSigTimeoutTime_PCM" SG_ 2583627910 ThermEvtCause 1250;
BA_ "CI_ParId" SG_ 2583627910 OpSts "ID2570";
BA_ "CI_SigId" SG_ 2583627910 OpSts 45295;
BA_ "CI_SigName" SG_ 2583627910 OpSts "Operational Status";
BA_ "GenSigTimeoutTime_PCM" SG_ 2583627910 OpSts 1250;
BA_ "CI_ParId" SG_ 2583627910 SocSts "ID2569";
BA_ "CI_SigId" SG_ 2583627910 SocSts 45294;
BA_ "CI_SigName" SG_ 2583627910 SocSts "State of Charge Status";
BA_ "GenSigTimeoutTime_PCM" SG_ 2583627910 SocSts 1250;
BA_ "CI_ParId" SG_ 2583627910 Temp "ID2568";
BA_ "CI_SigId" SG_ 2583627910 Temp 45293;
BA_ "CI_SigName" SG_ 2583627910 Temp "Temperature";
BA_ "GenSigTimeoutTime_PCM" SG_ 2583627910 Temp 1250;
BA_ "SigType" SG_ 2583627910 Temp 1;
BA_ "CI_ParId" SG_ 2583627910 FastUpdateSoc "ID2567";
BA_ "CI_SigId" SG_ 2583627910 FastUpdateSoc 45292;
BA_ "CI_SigName" SG_ 2583627910 FastUpdateSoc "Fast Update State of Charge";
BA_ "GenSigTimeoutTime_PCM" SG_ 2583627910 FastUpdateSoc 1250;
BA_ "SigType" SG_ 2583627910 FastUpdateSoc 1;
BA_ "CI_ParId" SG_ 2583627910 PackFuseDiag "ID2593";
BA_ "CI_SigId" SG_ 2583627910 PackFuseDiag 45489;
BA_ "CI_SigName" SG_ 2583627910 PackFuseDiag "Pack Fuse Diagnosis";
BA_ "GenSigTimeoutTime_PCM" SG_ 2583627910 PackFuseDiag 1250;
BA_ "SigType" SG_ 2583627910 PackFuseDiag 4;
BA_ "CI_ParId" SG_ 2583627911 PackDcirSts_FF0887 "ID2594";
BA_ "CI_SigId" SG_ 2583627911 PackDcirSts_FF0887 45492;
BA_ "CI_SigName" SG_ 2583627911 PackDcirSts_FF0887 "Pack DCIR Status";
BA_ "GenSigTimeoutTime_PCM" SG_ 2583627911 PackDcirSts_FF0887 1250;
BA_ "SigType" SG_ 2583627911 PackDcirSts_FF0887 4;
BA_ "CI_ParId" SG_ 2583627911 ThermEvtCause_FF0887 "ID2575";
BA_ "CI_SigId" SG_ 2583627911 ThermEvtCause_FF0887 45353;
BA_ "CI_SigName" SG_ 2583627911 ThermEvtCause_FF0887 "Thermal Event Cause";
BA_ "GenSigTimeoutTime_PCM" SG_ 2583627911 ThermEvtCause_FF0887 1250;
BA_ "CI_ParId" SG_ 2583627911 OpSts_FF0887 "ID2570";
BA_ "CI_SigId" SG_ 2583627911 OpSts_FF0887 45302;
BA_ "CI_SigName" SG_ 2583627911 OpSts_FF0887 "Operational Status";
BA_ "GenSigTimeoutTime_PCM" SG_ 2583627911 OpSts_FF0887 1250;
BA_ "CI_ParId" SG_ 2583627911 SocSts_FF0887 "ID2569";
BA_ "CI_SigId" SG_ 2583627911 SocSts_FF0887 45301;
BA_ "CI_SigName" SG_ 2583627911 SocSts_FF0887 "State of Charge Status";
BA_ "GenSigTimeoutTime_PCM" SG_ 2583627911 SocSts_FF0887 1250;
BA_ "CI_ParId" SG_ 2583627911 Temp_FF0887 "ID2568";
BA_ "CI_SigId" SG_ 2583627911 Temp_FF0887 45300;
BA_ "CI_SigName" SG_ 2583627911 Temp_FF0887 "Temperature";
BA_ "GenSigTimeoutTime_PCM" SG_ 2583627911 Temp_FF0887 1250;
BA_ "SigType" SG_ 2583627911 Temp_FF0887 1;
BA_ "CI_ParId" SG_ 2583627911 FastUpdateSoc_FF0887 "ID2567";
BA_ "CI_SigId" SG_ 2583627911 FastUpdateSoc_FF0887 45299;
BA_ "CI_SigName" SG_ 2583627911 FastUpdateSoc_FF0887 "Fast Update State of Charge";
BA_ "GenSigTimeoutTime_PCM" SG_ 2583627911 FastUpdateSoc_FF0887 1250;
BA_ "SigType" SG_ 2583627911 FastUpdateSoc_FF0887 1;
BA_ "CI_ParId" SG_ 2583627911 PackFuseDiag_FF0887 "ID2593";
BA_ "CI_SigId" SG_ 2583627911 PackFuseDiag_FF0887 45491;
BA_ "CI_SigName" SG_ 2583627911 PackFuseDiag_FF0887 "Pack Fuse Diagnosis";
BA_ "GenSigTimeoutTime_PCM" SG_ 2583627911 PackFuseDiag_FF0887 1250;
BA_ "SigType" SG_ 2583627911 PackFuseDiag_FF0887 4;
BA_ "CI_ParId" SG_ 2583628019 StsOfSaf "ID2042";
BA_ "CI_SigId" SG_ 2583628019 StsOfSaf 45241;
BA_ "CI_SigName" SG_ 2583628019 StsOfSaf "State of Safety";
BA_ "GenSigTimeoutTime_PCM" SG_ 2583628019 StsOfSaf 1250;
BA_ "SigType" SG_ 2583628019 StsOfSaf 1;
BA_ "CI_ParId" SG_ 2583628019 OpSts_FF08F3 "ID2570";
BA_ "CI_SigId" SG_ 2583628019 OpSts_FF08F3 45240;
BA_ "CI_SigName" SG_ 2583628019 OpSts_FF08F3 "Operational Status";
BA_ "GenSigTimeoutTime_PCM" SG_ 2583628019 OpSts_FF08F3 1250;
BA_ "CI_ParId" SG_ 2583628019 Temp_FF08F3 "ID2568";
BA_ "CI_SigId" SG_ 2583628019 Temp_FF08F3 45238;
BA_ "CI_SigName" SG_ 2583628019 Temp_FF08F3 "Temperature";
BA_ "GenSigTimeoutTime_PCM" SG_ 2583628019 Temp_FF08F3 1250;
BA_ "SigType" SG_ 2583628019 Temp_FF08F3 1;
BA_ "CI_ParId" SG_ 2583628019 ThermEvtDet "ID2574";
BA_ "CI_SigId" SG_ 2583628019 ThermEvtDet 45348;
BA_ "CI_SigName" SG_ 2583628019 ThermEvtDet "Thermal Event Detection";
BA_ "GenSigTimeoutTime_PCM" SG_ 2583628019 ThermEvtDet 1250;
BA_ "SigType" SG_ 2583628019 ThermEvtDet 4;
BA_ "CI_ParId" SG_ 2583628020 PackDcirSts_FF08F4 "ID2594";
BA_ "CI_SigId" SG_ 2583628020 PackDcirSts_FF08F4 45484;
BA_ "CI_SigName" SG_ 2583628020 PackDcirSts_FF08F4 "Pack DCIR Status";
BA_ "GenSigTimeoutTime_PCM" SG_ 2583628020 PackDcirSts_FF08F4 1250;
BA_ "SigType" SG_ 2583628020 PackDcirSts_FF08F4 4;
BA_ "CI_ParId" SG_ 2583628020 ThermEvtCause_FF08F4 "ID2575";
BA_ "CI_SigId" SG_ 2583628020 ThermEvtCause_FF08F4 45349;
BA_ "CI_SigName" SG_ 2583628020 ThermEvtCause_FF08F4 "Thermal Event Cause";
BA_ "GenSigTimeoutTime_PCM" SG_ 2583628020 ThermEvtCause_FF08F4 1250;
BA_ "CI_ParId" SG_ 2583628020 OpSts_FF08F4 "ID2570";
BA_ "CI_SigId" SG_ 2583628020 OpSts_FF08F4 45274;
BA_ "CI_SigName" SG_ 2583628020 OpSts_FF08F4 "Operational Status";
BA_ "GenSigTimeoutTime_PCM" SG_ 2583628020 OpSts_FF08F4 1250;
BA_ "CI_ParId" SG_ 2583628020 SocSts_FF08F4 "ID2569";
BA_ "CI_SigId" SG_ 2583628020 SocSts_FF08F4 45273;
BA_ "CI_SigName" SG_ 2583628020 SocSts_FF08F4 "State of Charge Status";
BA_ "GenSigTimeoutTime_PCM" SG_ 2583628020 SocSts_FF08F4 1250;
BA_ "CI_ParId" SG_ 2583628020 Temp_FF08F4 "ID2568";
BA_ "CI_SigId" SG_ 2583628020 Temp_FF08F4 45272;
BA_ "CI_SigName" SG_ 2583628020 Temp_FF08F4 "Temperature";
BA_ "GenSigTimeoutTime_PCM" SG_ 2583628020 Temp_FF08F4 1250;
BA_ "SigType" SG_ 2583628020 Temp_FF08F4 1;
BA_ "CI_ParId" SG_ 2583628020 FastUpdateSoc_FF08F4 "ID2567";
BA_ "CI_SigId" SG_ 2583628020 FastUpdateSoc_FF08F4 45271;
BA_ "CI_SigName" SG_ 2583628020 FastUpdateSoc_FF08F4 "Fast Update State of Charge";
BA_ "GenSigTimeoutTime_PCM" SG_ 2583628020 FastUpdateSoc_FF08F4 1250;
BA_ "SigType" SG_ 2583628020 FastUpdateSoc_FF08F4 1;
BA_ "CI_ParId" SG_ 2583628020 PackFuseDiag_FF08F4 "ID2593";
BA_ "CI_SigId" SG_ 2583628020 PackFuseDiag_FF08F4 45483;
BA_ "CI_SigName" SG_ 2583628020 PackFuseDiag_FF08F4 "Pack Fuse Diagnosis";
BA_ "GenSigTimeoutTime_PCM" SG_ 2583628020 PackFuseDiag_FF08F4 1250;
BA_ "SigType" SG_ 2583628020 PackFuseDiag_FF08F4 4;
BA_ "CI_ParId" SG_ 2583628021 PackDcirSts_FF08F5 "ID2594";
BA_ "CI_SigId" SG_ 2583628021 PackDcirSts_FF08F5 45486;
BA_ "CI_SigName" SG_ 2583628021 PackDcirSts_FF08F5 "Pack DCIR Status";
BA_ "GenSigTimeoutTime_PCM" SG_ 2583628021 PackDcirSts_FF08F5 1250;
BA_ "SigType" SG_ 2583628021 PackDcirSts_FF08F5 4;
BA_ "CI_ParId" SG_ 2583628021 ThermEvtCause_FF08F5 "ID2575";
BA_ "CI_SigId" SG_ 2583628021 ThermEvtCause_FF08F5 45350;
BA_ "CI_SigName" SG_ 2583628021 ThermEvtCause_FF08F5 "Thermal Event Cause";
BA_ "GenSigTimeoutTime_PCM" SG_ 2583628021 ThermEvtCause_FF08F5 1250;
BA_ "CI_ParId" SG_ 2583628021 OpSts_FF08F5 "ID2570";
BA_ "CI_SigId" SG_ 2583628021 OpSts_FF08F5 45281;
BA_ "CI_SigName" SG_ 2583628021 OpSts_FF08F5 "Operational Status";
BA_ "GenSigTimeoutTime_PCM" SG_ 2583628021 OpSts_FF08F5 1250;
BA_ "CI_ParId" SG_ 2583628021 SocSts_FF08F5 "ID2569";
BA_ "CI_SigId" SG_ 2583628021 SocSts_FF08F5 45280;
BA_ "CI_SigName" SG_ 2583628021 SocSts_FF08F5 "State of Charge Status";
BA_ "GenSigTimeoutTime_PCM" SG_ 2583628021 SocSts_FF08F5 1250;
BA_ "CI_ParId" SG_ 2583628021 Temp_FF08F5 "ID2568";
BA_ "CI_SigId" SG_ 2583628021 Temp_FF08F5 45279;
BA_ "CI_SigName" SG_ 2583628021 Temp_FF08F5 "Temperature";
BA_ "GenSigTimeoutTime_PCM" SG_ 2583628021 Temp_FF08F5 1250;
BA_ "SigType" SG_ 2583628021 Temp_FF08F5 1;
BA_ "CI_ParId" SG_ 2583628021 FastUpdateSoc_FF08F5 "ID2567";
BA_ "CI_SigId" SG_ 2583628021 FastUpdateSoc_FF08F5 45278;
BA_ "CI_SigName" SG_ 2583628021 FastUpdateSoc_FF08F5 "Fast Update State of Charge";
BA_ "GenSigTimeoutTime_PCM" SG_ 2583628021 FastUpdateSoc_FF08F5 1250;
BA_ "SigType" SG_ 2583628021 FastUpdateSoc_FF08F5 1;
BA_ "CI_ParId" SG_ 2583628021 PackFuseDiag_FF08F5 "ID2593";
BA_ "CI_SigId" SG_ 2583628021 PackFuseDiag_FF08F5 45485;
BA_ "CI_SigName" SG_ 2583628021 PackFuseDiag_FF08F5 "Pack Fuse Diagnosis";
BA_ "GenSigTimeoutTime_PCM" SG_ 2583628021 PackFuseDiag_FF08F5 1250;
BA_ "SigType" SG_ 2583628021 PackFuseDiag_FF08F5 4;
BA_ "CI_ParId" SG_ 2583628022 PackDcirSts_FF08F6 "ID2594";
BA_ "CI_SigId" SG_ 2583628022 PackDcirSts_FF08F6 45488;
BA_ "CI_SigName" SG_ 2583628022 PackDcirSts_FF08F6 "Pack DCIR Status";
BA_ "GenSigTimeoutTime_PCM" SG_ 2583628022 PackDcirSts_FF08F6 1250;
BA_ "SigType" SG_ 2583628022 PackDcirSts_FF08F6 4;
BA_ "CI_ParId" SG_ 2583628022 ThermEvtCause_FF08F6 "ID2575";
BA_ "CI_SigId" SG_ 2583628022 ThermEvtCause_FF08F6 45351;
BA_ "CI_SigName" SG_ 2583628022 ThermEvtCause_FF08F6 "Thermal Event Cause";
BA_ "GenSigTimeoutTime_PCM" SG_ 2583628022 ThermEvtCause_FF08F6 1250;
BA_ "CI_ParId" SG_ 2583628022 OpSts_FF08F6 "ID2570";
BA_ "CI_SigId" SG_ 2583628022 OpSts_FF08F6 45288;
BA_ "CI_SigName" SG_ 2583628022 OpSts_FF08F6 "Operational Status";
BA_ "GenSigTimeoutTime_PCM" SG_ 2583628022 OpSts_FF08F6 1250;
BA_ "CI_ParId" SG_ 2583628022 SocSts_FF08F6 "ID2569";
BA_ "CI_SigId" SG_ 2583628022 SocSts_FF08F6 45287;
BA_ "CI_SigName" SG_ 2583628022 SocSts_FF08F6 "State of Charge Status";
BA_ "GenSigTimeoutTime_PCM" SG_ 2583628022 SocSts_FF08F6 1250;
BA_ "CI_ParId" SG_ 2583628022 Temp_FF08F6 "ID2568";
BA_ "CI_SigId" SG_ 2583628022 Temp_FF08F6 45286;
BA_ "CI_SigName" SG_ 2583628022 Temp_FF08F6 "Temperature";
BA_ "GenSigTimeoutTime_PCM" SG_ 2583628022 Temp_FF08F6 1250;
BA_ "SigType" SG_ 2583628022 Temp_FF08F6 1;
BA_ "CI_ParId" SG_ 2583628022 FastUpdateSoc_FF08F6 "ID2567";
BA_ "CI_SigId" SG_ 2583628022 FastUpdateSoc_FF08F6 45285;
BA_ "CI_SigName" SG_ 2583628022 FastUpdateSoc_FF08F6 "Fast Update State of Charge";
BA_ "GenSigTimeoutTime_PCM" SG_ 2583628022 FastUpdateSoc_FF08F6 1250;
BA_ "SigType" SG_ 2583628022 FastUpdateSoc_FF08F6 1;
BA_ "CI_ParId" SG_ 2583628022 PackFuseDiag_FF08F6 "ID2593";
BA_ "CI_SigId" SG_ 2583628022 PackFuseDiag_FF08F6 45487;
BA_ "CI_SigName" SG_ 2583628022 PackFuseDiag_FF08F6 "Pack Fuse Diagnosis";
BA_ "GenSigTimeoutTime_PCM" SG_ 2583628022 PackFuseDiag_FF08F6 1250;
BA_ "SigType" SG_ 2583628022 PackFuseDiag_FF08F6 4;
BA_ "CI_ParId" SG_ 2583628275 HvessHighVBusPasIsolTestRes "8432";
BA_ "CI_SigId" SG_ 2583628275 HvessHighVBusPasIsolTestRes 45247;
BA_ "CI_SigName" SG_ 2583628275 HvessHighVBusPasIsolTestRes "HVESS High-Voltage Bus Passive Isolation Test Results";
BA_ "GenSigTimeoutTime_PCM" SG_ 2583628275 HvessHighVBusPasIsolTestRes 500;
BA_ "SPN" SG_ 2583628275 HvessHighVBusPasIsolTestRes 8432;
BA_ "SigType" SG_ 2583628275 HvessHighVBusPasIsolTestRes 1;
BA_ "CI_ParId" SG_ 2583628275 HvessAvChgPwr "5918";
BA_ "CI_SigId" SG_ 2583628275 HvessAvChgPwr 45246;
BA_ "CI_SigName" SG_ 2583628275 HvessAvChgPwr "HVESS Available Charge Power";
BA_ "GenSigTimeoutTime_PCM" SG_ 2583628275 HvessAvChgPwr 500;
BA_ "SPN" SG_ 2583628275 HvessAvChgPwr 5918;
BA_ "SigType" SG_ 2583628275 HvessAvChgPwr 1;
BA_ "CI_ParId" SG_ 2583628275 HvessAvDischPwr "5917";
BA_ "CI_SigId" SG_ 2583628275 HvessAvDischPwr 45245;
BA_ "CI_SigName" SG_ 2583628275 HvessAvDischPwr "HVESS Available Discharge Power";
BA_ "GenSigTimeoutTime_PCM" SG_ 2583628275 HvessAvDischPwr 500;
BA_ "SPN" SG_ 2583628275 HvessAvDischPwr 5917;
BA_ "SigType" SG_ 2583628275 HvessAvDischPwr 1;
BA_ "CI_ParId" SG_ 2583628531 HvessCur "5920";
BA_ "CI_SigId" SG_ 2583628531 HvessCur 45252;
BA_ "CI_SigName" SG_ 2583628531 HvessCur "HVESS Current";
BA_ "GenSigTimeoutTime_PCM" SG_ 2583628531 HvessCur 500;
BA_ "SPN" SG_ 2583628531 HvessCur 5920;
BA_ "SigType" SG_ 2583628531 HvessCur 1;
BA_ "CI_ParId" SG_ 2583628531 HvessVLev "5919";
BA_ "CI_SigId" SG_ 2583628531 HvessVLev 45251;
BA_ "CI_SigName" SG_ 2583628531 HvessVLev "HVESS Voltage Level";
BA_ "GenSigTimeoutTime_PCM" SG_ 2583628531 HvessVLev 500;
BA_ "SPN" SG_ 2583628531 HvessVLev 5919;
BA_ "SigType" SG_ 2583628531 HvessVLev 1;
BA_ "CI_ParId" SG_ 2583628787 HvessMaxChgVLim "8090";
BA_ "CI_SigId" SG_ 2583628787 HvessMaxChgVLim 45258;
BA_ "CI_SigName" SG_ 2583628787 HvessMaxChgVLim "HVESS Maximum Charge Voltage Limit";
BA_ "GenSigTimeoutTime_PCM" SG_ 2583628787 HvessMaxChgVLim 500;
BA_ "SPN" SG_ 2583628787 HvessMaxChgVLim 8090;
BA_ "SigType" SG_ 2583628787 HvessMaxChgVLim 1;
BA_ "CI_ParId" SG_ 2583628787 HvessChgCurLim "8083";
BA_ "CI_SigId" SG_ 2583628787 HvessChgCurLim 45257;
BA_ "CI_SigName" SG_ 2583628787 HvessChgCurLim "HVESS Charge Current Limit";
BA_ "GenSigTimeoutTime_PCM" SG_ 2583628787 HvessChgCurLim 500;
BA_ "SPN" SG_ 2583628787 HvessChgCurLim 8083;
BA_ "SigType" SG_ 2583628787 HvessChgCurLim 1;
BA_ "CI_ParId" SG_ 2583628787 HvessDischCurLim "8082";
BA_ "CI_SigId" SG_ 2583628787 HvessDischCurLim 45256;
BA_ "CI_SigName" SG_ 2583628787 HvessDischCurLim "HVESS Discharge Current Limit";
BA_ "GenSigTimeoutTime_PCM" SG_ 2583628787 HvessDischCurLim 500;
BA_ "SPN" SG_ 2583628787 HvessDischCurLim 8082;
BA_ "SigType" SG_ 2583628787 HvessDischCurLim 1;
BA_ "CI_ParId" SG_ 2583628934 Soh "ID2571";
BA_ "CI_SigId" SG_ 2583628934 Soh 45334;
BA_ "CI_SigName" SG_ 2583628934 Soh "State of Health";
BA_ "GenSigTimeoutTime_PCM" SG_ 2583628934 Soh 50000;
BA_ "SigType" SG_ 2583628934 Soh 1;
BA_ "CI_ParId" SG_ 2583628934 TotEnergyTput "ID2572";
BA_ "CI_SigId" SG_ 2583628934 TotEnergyTput 45333;
BA_ "CI_SigName" SG_ 2583628934 TotEnergyTput "Total Energy Throughput";
BA_ "GenSigTimeoutTime_PCM" SG_ 2583628934 TotEnergyTput 50000;
BA_ "SigType" SG_ 2583628934 TotEnergyTput 1;
BA_ "CI_ParId" SG_ 2583628935 Soh_FF0C87 "ID2571";
BA_ "CI_SigId" SG_ 2583628935 Soh_FF0C87 45343;
BA_ "CI_SigName" SG_ 2583628935 Soh_FF0C87 "State of Health";
BA_ "GenSigTimeoutTime_PCM" SG_ 2583628935 Soh_FF0C87 50000;
BA_ "SigType" SG_ 2583628935 Soh_FF0C87 1;
BA_ "CI_ParId" SG_ 2583628935 TotEnergyTput_FF0C87 "ID2572";
BA_ "CI_SigId" SG_ 2583628935 TotEnergyTput_FF0C87 45342;
BA_ "CI_SigName" SG_ 2583628935 TotEnergyTput_FF0C87 "Total Energy Throughput";
BA_ "GenSigTimeoutTime_PCM" SG_ 2583628935 TotEnergyTput_FF0C87 50000;
BA_ "SigType" SG_ 2583628935 TotEnergyTput_FF0C87 1;
BA_ "CI_ParId" SG_ 2583629043 Soh_FF0CF3 "ID2571";
BA_ "CI_SigId" SG_ 2583629043 Soh_FF0CF3 45263;
BA_ "CI_SigName" SG_ 2583629043 Soh_FF0CF3 "State of Health";
BA_ "GenSigTimeoutTime_PCM" SG_ 2583629043 Soh_FF0CF3 7500;
BA_ "SigType" SG_ 2583629043 Soh_FF0CF3 1;
BA_ "CI_ParId" SG_ 2583629043 TotEnergyTput_FF0CF3 "ID2572";
BA_ "CI_SigId" SG_ 2583629043 TotEnergyTput_FF0CF3 45262;
BA_ "CI_SigName" SG_ 2583629043 TotEnergyTput_FF0CF3 "Total Energy Throughput";
BA_ "GenSigTimeoutTime_PCM" SG_ 2583629043 TotEnergyTput_FF0CF3 7500;
BA_ "SigType" SG_ 2583629043 TotEnergyTput_FF0CF3 1;
BA_ "CI_ParId" SG_ 2583629044 Soh_FF0CF4 "ID2571";
BA_ "CI_SigId" SG_ 2583629044 Soh_FF0CF4 45307;
BA_ "CI_SigName" SG_ 2583629044 Soh_FF0CF4 "State of Health";
BA_ "GenSigTimeoutTime_PCM" SG_ 2583629044 Soh_FF0CF4 50000;
BA_ "SigType" SG_ 2583629044 Soh_FF0CF4 1;
BA_ "CI_ParId" SG_ 2583629044 TotEnergyTput_FF0CF4 "ID2572";
BA_ "CI_SigId" SG_ 2583629044 TotEnergyTput_FF0CF4 45306;
BA_ "CI_SigName" SG_ 2583629044 TotEnergyTput_FF0CF4 "Total Energy Throughput";
BA_ "GenSigTimeoutTime_PCM" SG_ 2583629044 TotEnergyTput_FF0CF4 50000;
BA_ "SigType" SG_ 2583629044 TotEnergyTput_FF0CF4 1;
BA_ "CI_ParId" SG_ 2583629045 Soh_FF0CF5 "ID2571";
BA_ "CI_SigId" SG_ 2583629045 Soh_FF0CF5 45316;
BA_ "CI_SigName" SG_ 2583629045 Soh_FF0CF5 "State of Health";
BA_ "GenSigTimeoutTime_PCM" SG_ 2583629045 Soh_FF0CF5 50000;
BA_ "SigType" SG_ 2583629045 Soh_FF0CF5 1;
BA_ "CI_ParId" SG_ 2583629045 TotEnergyTput_FF0CF5 "ID2572";
BA_ "CI_SigId" SG_ 2583629045 TotEnergyTput_FF0CF5 45315;
BA_ "CI_SigName" SG_ 2583629045 TotEnergyTput_FF0CF5 "Total Energy Throughput";
BA_ "GenSigTimeoutTime_PCM" SG_ 2583629045 TotEnergyTput_FF0CF5 50000;
BA_ "SigType" SG_ 2583629045 TotEnergyTput_FF0CF5 1;
BA_ "CI_ParId" SG_ 2583629046 Soh_FF0CF6 "ID2571";
BA_ "CI_SigId" SG_ 2583629046 Soh_FF0CF6 45325;
BA_ "CI_SigName" SG_ 2583629046 Soh_FF0CF6 "State of Health";
BA_ "GenSigTimeoutTime_PCM" SG_ 2583629046 Soh_FF0CF6 50000;
BA_ "SigType" SG_ 2583629046 Soh_FF0CF6 1;
BA_ "CI_ParId" SG_ 2583629046 TotEnergyTput_FF0CF6 "ID2572";
BA_ "CI_SigId" SG_ 2583629046 TotEnergyTput_FF0CF6 45324;
BA_ "CI_SigName" SG_ 2583629046 TotEnergyTput_FF0CF6 "Total Energy Throughput";
BA_ "GenSigTimeoutTime_PCM" SG_ 2583629046 TotEnergyTput_FF0CF6 50000;
BA_ "SigType" SG_ 2583629046 TotEnergyTput_FF0CF6 1;
BA_ "CI_ParId" SG_ 2583629190 TotAccumChg "ID2573";
BA_ "CI_SigId" SG_ 2583629190 TotAccumChg 45338;
BA_ "CI_SigName" SG_ 2583629190 TotAccumChg "Total Accumulated Charge";
BA_ "GenSigTimeoutTime_PCM" SG_ 2583629190 TotAccumChg 50000;
BA_ "SigType" SG_ 2583629190 TotAccumChg 1;
BA_ "CI_ParId" SG_ 2583629191 TotAccumChg_FF0D87 "ID2573";
BA_ "CI_SigId" SG_ 2583629191 TotAccumChg_FF0D87 45347;
BA_ "CI_SigName" SG_ 2583629191 TotAccumChg_FF0D87 "Total Accumulated Charge";
BA_ "GenSigTimeoutTime_PCM" SG_ 2583629191 TotAccumChg_FF0D87 50000;
BA_ "SigType" SG_ 2583629191 TotAccumChg_FF0D87 1;
BA_ "CI_ParId" SG_ 2583629299 TotAccumChg_FF0DF3 "ID2573";
BA_ "CI_SigId" SG_ 2583629299 TotAccumChg_FF0DF3 45267;
BA_ "CI_SigName" SG_ 2583629299 TotAccumChg_FF0DF3 "Total Accumulated Charge";
BA_ "GenSigTimeoutTime_PCM" SG_ 2583629299 TotAccumChg_FF0DF3 7500;
BA_ "SigType" SG_ 2583629299 TotAccumChg_FF0DF3 1;
BA_ "CI_ParId" SG_ 2583629300 TotAccumChg_FF0DF4 "ID2573";
BA_ "CI_SigId" SG_ 2583629300 TotAccumChg_FF0DF4 45311;
BA_ "CI_SigName" SG_ 2583629300 TotAccumChg_FF0DF4 "Total Accumulated Charge";
BA_ "GenSigTimeoutTime_PCM" SG_ 2583629300 TotAccumChg_FF0DF4 50000;
BA_ "SigType" SG_ 2583629300 TotAccumChg_FF0DF4 1;
BA_ "CI_ParId" SG_ 2583629301 TotAccumChg_FF0DF5 "ID2573";
BA_ "CI_SigId" SG_ 2583629301 TotAccumChg_FF0DF5 45320;
BA_ "CI_SigName" SG_ 2583629301 TotAccumChg_FF0DF5 "Total Accumulated Charge";
BA_ "GenSigTimeoutTime_PCM" SG_ 2583629301 TotAccumChg_FF0DF5 50000;
BA_ "SigType" SG_ 2583629301 TotAccumChg_FF0DF5 1;
BA_ "CI_ParId" SG_ 2583629302 TotAccumChg_FF0DF6 "ID2573";
BA_ "CI_SigId" SG_ 2583629302 TotAccumChg_FF0DF6 45329;
BA_ "CI_SigName" SG_ 2583629302 TotAccumChg_FF0DF6 "Total Accumulated Charge";
BA_ "GenSigTimeoutTime_PCM" SG_ 2583629302 TotAccumChg_FF0DF6 50000;
BA_ "SigType" SG_ 2583629302 TotAccumChg_FF0DF6 1;
BA_ "CI_ParId" SG_ 2634014026 TxtDisCharA "3615";
BA_ "CI_SigId" SG_ 2634014026 TxtDisCharA 4897;
BA_ "CI_SigName" SG_ 2634014026 TxtDisCharA "Text Display Character A";
BA_ "SPN" SG_ 2634014026 TxtDisCharA 3615;
BA_ "SigType" SG_ 2634014026 TxtDisCharA 8;
BA_ "CI_ParId" SG_ 2634014026 TxtCharSet "I335";
BA_ "CI_SigId" SG_ 2634014026 TxtCharSet 4896;
BA_ "CI_SigName" SG_ 2634014026 TxtCharSet "Text Character Set";
BA_ "CI_ParId" SG_ 2634014026 PopupIx_FFDD4A "I322";
BA_ "CI_SigId" SG_ 2634014026 PopupIx_FFDD4A 4895;
BA_ "CI_SigName" SG_ 2634014026 PopupIx_FFDD4A "Popup Index";
BA_ "CI_ParId" SG_ 2634014066 TxtDisCharA_FFDD72 "3615";
BA_ "CI_SigId" SG_ 2634014066 TxtDisCharA_FFDD72 4902;
BA_ "CI_SigName" SG_ 2634014066 TxtDisCharA_FFDD72 "Text Display Character A";
BA_ "GenSigSendType" SG_ 2634014066 TxtDisCharA_FFDD72 5;
BA_ "SPN" SG_ 2634014066 TxtDisCharA_FFDD72 3615;
BA_ "SigType" SG_ 2634014066 TxtDisCharA_FFDD72 8;
BA_ "CI_ParId" SG_ 2634014066 TxtCharSet_FFDD72 "I335";
BA_ "CI_SigId" SG_ 2634014066 TxtCharSet_FFDD72 4901;
BA_ "CI_SigName" SG_ 2634014066 TxtCharSet_FFDD72 "Text Character Set";
BA_ "GenSigSendType" SG_ 2634014066 TxtCharSet_FFDD72 5;
BA_ "CI_ParId" SG_ 2634014066 PopupIx_FFDD72 "I322";
BA_ "CI_SigId" SG_ 2634014066 PopupIx_FFDD72 4900;
BA_ "CI_SigName" SG_ 2634014066 PopupIx_FFDD72 "Popup Index";
BA_ "GenSigSendType" SG_ 2634014066 PopupIx_FFDD72 5;
BA_ "CI_ParId" SG_ 2566904855 BuzLevEx_FFDC17 "I318";
BA_ "CI_SigId" SG_ 2566904855 BuzLevEx_FFDC17 4869;
BA_ "CI_SigName" SG_ 2566904855 BuzLevEx_FFDC17 "Buzzer Level Extended";
BA_ "GenSigSendType" SG_ 2566904855 BuzLevEx_FFDC17 3;
BA_ "CI_ParId" SG_ 2566904855 BuzToneEx_FFDC17 "I317";
BA_ "CI_SigId" SG_ 2566904855 BuzToneEx_FFDC17 4868;
BA_ "CI_SigName" SG_ 2566904855 BuzToneEx_FFDC17 "Buzzer Tone Extended";
BA_ "GenSigSendType" SG_ 2566904855 BuzToneEx_FFDC17 3;
BA_ "CI_ParId" SG_ 2566904855 PopupAckSts "I326";
BA_ "CI_SigId" SG_ 2566904855 PopupAckSts 4867;
BA_ "CI_SigName" SG_ 2566904855 PopupAckSts "Popup Acknowledge Status";
BA_ "GenSigSendType" SG_ 2566904855 PopupAckSts 3;
BA_ "SigType" SG_ 2566904855 PopupAckSts 4;
BA_ "CI_ParId" SG_ 2566904855 PopupActvSts "I325";
BA_ "CI_SigId" SG_ 2566904855 PopupActvSts 4866;
BA_ "CI_SigName" SG_ 2566904855 PopupActvSts "Popup Activation Status";
BA_ "GenSigSendType" SG_ 2566904855 PopupActvSts 3;
BA_ "SigType" SG_ 2566904855 PopupActvSts 4;
BA_ "CI_ParId" SG_ 2566904855 PopupIx_FFDC17 "I322";
BA_ "CI_SigId" SG_ 2566904855 PopupIx_FFDC17 4865;
BA_ "CI_SigName" SG_ 2566904855 PopupIx_FFDC17 "Popup Index";
BA_ "GenSigSendType" SG_ 2566904855 PopupIx_FFDC17 3;
BA_ "CI_ParId" SG_ 2566904855 IndActvSts "I324";
BA_ "CI_SigId" SG_ 2566904855 IndActvSts 4864;
BA_ "CI_SigName" SG_ 2566904855 IndActvSts "Indicator Activation Status";
BA_ "GenSigSendType" SG_ 2566904855 IndActvSts 3;
BA_ "SigType" SG_ 2566904855 IndActvSts 4;
BA_ "CI_ParId" SG_ 2566904855 IndIx_FFDC17 "I321";
BA_ "CI_SigId" SG_ 2566904855 IndIx_FFDC17 4863;
BA_ "CI_SigName" SG_ 2566904855 IndIx_FFDC17 "Indicator Index";
BA_ "GenSigSendType" SG_ 2566904855 IndIx_FFDC17 3;
BA_ "CI_ParId" SG_ 2315191791 HVVoltage "ACT015";
BA_ "CI_SigId" SG_ 2315191791 HVVoltage 45146;
BA_ "CI_SigName" SG_ 2315191791 HVVoltage "Inverter high voltage Input";
BA_ "GenSigTimeoutTime_PCM" SG_ 2315191791 HVVoltage 500;
BA_ "SigType" SG_ 2315191791 HVVoltage 1;
BA_ "CI_ParId" SG_ 2315191791 EST_HVDCCurrent "ACT036";
BA_ "CI_SigId" SG_ 2315191791 EST_HVDCCurrent 45145;
BA_ "CI_SigName" SG_ 2315191791 EST_HVDCCurrent "Estimated DC Current";
BA_ "GenSigTimeoutTime_PCM" SG_ 2315191791 EST_HVDCCurrent 500;
BA_ "SigType" SG_ 2315191791 EST_HVDCCurrent 1;
BA_ "CI_ParId" SG_ 2315191791 Torque_applied "ACT027";
BA_ "CI_SigId" SG_ 2315191791 Torque_applied 45144;
BA_ "CI_SigName" SG_ 2315191791 Torque_applied "Torque applied";
BA_ "GenSigTimeoutTime_PCM" SG_ 2315191791 Torque_applied 500;
BA_ "SigType" SG_ 2315191791 Torque_applied 1;
BA_ "CI_ParId" SG_ 2315191791 DeratingStatus "ACT030";
BA_ "CI_SigId" SG_ 2315191791 DeratingStatus 45143;
BA_ "CI_SigName" SG_ 2315191791 DeratingStatus "Derating Status";
BA_ "GenSigTimeoutTime_PCM" SG_ 2315191791 DeratingStatus 500;
BA_ "SigType" SG_ 2315191791 DeratingStatus 4;
BA_ "CI_ParId" SG_ 2315191791 Direction "ACT037";
BA_ "CI_SigId" SG_ 2315191791 Direction 45142;
BA_ "CI_SigName" SG_ 2315191791 Direction "Direction Signal";
BA_ "GenSigTimeoutTime_PCM" SG_ 2315191791 Direction 500;
BA_ "SigType" SG_ 2315191791 Direction 4;
BA_ "CI_ParId" SG_ 2583627762 Mot_Gen1InvTemp1_FF07F2 "10216";
BA_ "CI_SigId" SG_ 2583627762 Mot_Gen1InvTemp1_FF07F2 45220;
BA_ "CI_SigName" SG_ 2583627762 Mot_Gen1InvTemp1_FF07F2 "Motor/Generator 1 Inverter Temperature 1";
BA_ "GenSigTimeoutTime_PCM" SG_ 2583627762 Mot_Gen1InvTemp1_FF07F2 5000;
BA_ "SPN" SG_ 2583627762 Mot_Gen1InvTemp1_FF07F2 10216;
BA_ "SigType" SG_ 2583627762 Mot_Gen1InvTemp1_FF07F2 1;
BA_ "CI_ParId" SG_ 2583627762 Mot_Gen1Temp1_FF07F2 "9059";
BA_ "CI_SigId" SG_ 2583627762 Mot_Gen1Temp1_FF07F2 45219;
BA_ "CI_SigName" SG_ 2583627762 Mot_Gen1Temp1_FF07F2 "Motor/Generator 1 Temperature 1";
BA_ "GenSigTimeoutTime_PCM" SG_ 2583627762 Mot_Gen1Temp1_FF07F2 5000;
BA_ "SPN" SG_ 2583627762 Mot_Gen1Temp1_FF07F2 9059;
BA_ "SigType" SG_ 2583627762 Mot_Gen1Temp1_FF07F2 1;
BA_ "CI_ParId" SG_ 2583627762 CoastDwSts "ID2581";
BA_ "CI_SigId" SG_ 2583627762 CoastDwSts 45383;
BA_ "CI_SigName" SG_ 2583627762 CoastDwSts "Coast Down Status";
BA_ "GenSigTimeoutTime_PCM" SG_ 2583627762 CoastDwSts 5000;
BA_ "SigType" SG_ 2583627762 CoastDwSts 4;
BA_ "CI_ParId" SG_ 2566894871 IAccMan_AutoCfg "ID2446";
BA_ "CI_SigId" SG_ 2566894871 IAccMan_AutoCfg 44590;
BA_ "CI_SigName" SG_ 2566894871 IAccMan_AutoCfg "i-ACC Manual/Automatic Configuration";
BA_ "GenSigSendType" SG_ 2566894871 IAccMan_AutoCfg 3;
BA_ "GenSigTimeoutTime_PCM" SG_ 2566894871 IAccMan_AutoCfg 5000;
BA_ "CI_ParId" SG_ 2566894871 IsaSpeedLimCfg "ID2437";
BA_ "CI_SigId" SG_ 2566894871 IsaSpeedLimCfg 44436;
BA_ "CI_SigName" SG_ 2566894871 IsaSpeedLimCfg "ISA Speed Limiter Configuration";
BA_ "GenSigSendType" SG_ 2566894871 IsaSpeedLimCfg 3;
BA_ "GenSigTimeoutTime_PCM" SG_ 2566894871 IsaSpeedLimCfg 5000;
BA_ "CI_ParId" SG_ 2566894871 IAccSpeedLimOfs "ID2428";
BA_ "CI_SigId" SG_ 2566894871 IAccSpeedLimOfs 44318;
BA_ "CI_SigName" SG_ 2566894871 IAccSpeedLimOfs "i-ACC Speed Limit Offset ";
BA_ "GenSigSendType" SG_ 2566894871 IAccSpeedLimOfs 3;
BA_ "GenSigTimeoutTime_PCM" SG_ 2566894871 IAccSpeedLimOfs 5000;
BA_ "CI_ParId" SG_ 2566894871 IsaSwlfAcousticNotificationWarnC "ID2438";
BA_ "CI_SigId" SG_ 2566894871 IsaSwlfAcousticNotificationWarnC 44435;
BA_ "CI_SigName" SG_ 2566894871 IsaSwlfAcousticNotificationWarnC "ISA SWLF Acoustic Notification Warning Configuration";
BA_ "GenSigSendType" SG_ 2566894871 IsaSwlfAcousticNotificationWarnC 3;
BA_ "GenSigTimeoutTime_PCM" SG_ 2566894871 IsaSwlfAcousticNotificationWarnC 5000;
BA_ "SigType" SG_ 2566894871 IsaSwlfAcousticNotificationWarnC 4;
BA_ "CI_ParId" SG_ 2566894871 IntelligentSpeedAssantCfg "ID2317";
BA_ "CI_SigId" SG_ 2566894871 IntelligentSpeedAssantCfg 42358;
BA_ "CI_SigName" SG_ 2566894871 IntelligentSpeedAssantCfg "Intelligent Speed Assistant Configuration";
BA_ "GenSigSendType" SG_ 2566894871 IntelligentSpeedAssantCfg 3;
BA_ "GenSigTimeoutTime_PCM" SG_ 2566894871 IntelligentSpeedAssantCfg 5000;
BA_ "SigType" SG_ 2566894871 IntelligentSpeedAssantCfg 4;
BA_ "CI_ParId" SG_ 2566894871 IsaSwlfOpticWarnCfg "ID2403";
BA_ "CI_SigId" SG_ 2566894871 IsaSwlfOpticWarnCfg 42360;
BA_ "CI_SigName" SG_ 2566894871 IsaSwlfOpticWarnCfg "ISA SWLF Optical Warning Configuration (Visual + Acoustic)";
BA_ "GenSigSendType" SG_ 2566894871 IsaSwlfOpticWarnCfg 3;
BA_ "GenSigTimeoutTime_PCM" SG_ 2566894871 IsaSwlfOpticWarnCfg 5000;
BA_ "SigType" SG_ 2566894871 IsaSwlfOpticWarnCfg 4;
BA_ "CI_ParId" SG_ 2566894871 IsaAcousticWarnCfg "ID2402";
BA_ "CI_SigId" SG_ 2566894871 IsaAcousticWarnCfg 42359;
BA_ "CI_SigName" SG_ 2566894871 IsaAcousticWarnCfg "ISA Acoustic Warning Configuration";
BA_ "GenSigSendType" SG_ 2566894871 IsaAcousticWarnCfg 3;
BA_ "GenSigTimeoutTime_PCM" SG_ 2566894871 IsaAcousticWarnCfg 5000;
BA_ "SigType" SG_ 2566894871 IsaAcousticWarnCfg 4;
BA_ "CI_ParId" SG_ 2566894890 IsaSpeedLimOvr "ID2579";
BA_ "CI_SigId" SG_ 2566894890 IsaSpeedLimOvr 45357;
BA_ "CI_SigName" SG_ 2566894890 IsaSpeedLimOvr "ISA Speed Limit Override";
BA_ "GenSigSendType" SG_ 2566894890 IsaSpeedLimOvr 3;
BA_ "GenSigTimeoutTime_PCM" SG_ 2566894890 IsaSpeedLimOvr 5000;
BA_ "SigType" SG_ 2566894890 IsaSpeedLimOvr 4;
BA_ "CI_ParId" SG_ 2566894890 TsaSts "ID2512";
BA_ "CI_SigId" SG_ 2566894890 TsaSts 44738;
BA_ "CI_SigName" SG_ 2566894890 TsaSts "TSA State";
BA_ "GenSigSendType" SG_ 2566894890 TsaSts 3;
BA_ "GenSigTimeoutTime_PCM" SG_ 2566894890 TsaSts 5000;
BA_ "CI_ParId" SG_ 2566894890 IntelligentVehSpeedAssantSts "ID2320";
BA_ "CI_SigId" SG_ 2566894890 IntelligentVehSpeedAssantSts 42368;
BA_ "CI_SigName" SG_ 2566894890 IntelligentVehSpeedAssantSts "Intelligent Vehicle Speed Assistant Status";
BA_ "GenSigSendType" SG_ 2566894890 IntelligentVehSpeedAssantSts 3;
BA_ "GenSigTimeoutTime_PCM" SG_ 2566894890 IntelligentVehSpeedAssantSts 5000;
BA_ "CI_ParId" SG_ 2566894890 SpeedUnit "ID2409";
BA_ "CI_SigId" SG_ 2566894890 SpeedUnit 42366;
BA_ "CI_SigName" SG_ 2566894890 SpeedUnit "Speed Unit";
BA_ "GenSigSendType" SG_ 2566894890 SpeedUnit 3;
BA_ "GenSigTimeoutTime_PCM" SG_ 2566894890 SpeedUnit 5000;
BA_ "SigType" SG_ 2566894890 SpeedUnit 4;
BA_ "CI_ParId" SG_ 2566894890 IsaWarnType "ID2318";
BA_ "CI_SigId" SG_ 2566894890 IsaWarnType 42365;
BA_ "CI_SigName" SG_ 2566894890 IsaWarnType "ISA Warning Type";
BA_ "GenSigSendType" SG_ 2566894890 IsaWarnType 3;
BA_ "GenSigTimeoutTime_PCM" SG_ 2566894890 IsaWarnType 5000;
BA_ "SigType" SG_ 2566894890 IsaWarnType 4;
BA_ "CI_ParId" SG_ 2566894922 IAccMan_AutoCfg_FFB54A "ID2446";
BA_ "CI_SigId" SG_ 2566894922 IAccMan_AutoCfg_FFB54A 42372;
BA_ "CI_SigName" SG_ 2566894922 IAccMan_AutoCfg_FFB54A "i-ACC Manual/Automatic Configuration";
BA_ "CI_ParId" SG_ 2566894922 IsaSpeedLimCfg_FFB54A "ID2437";
BA_ "CI_SigId" SG_ 2566894922 IsaSpeedLimCfg_FFB54A 44765;
BA_ "CI_SigName" SG_ 2566894922 IsaSpeedLimCfg_FFB54A "ISA Speed Limiter Configuration";
BA_ "CI_ParId" SG_ 2566894922 IAccSpeedLimOfs_FFB54A "ID2428";
BA_ "CI_SigId" SG_ 2566894922 IAccSpeedLimOfs_FFB54A 44524;
BA_ "CI_SigName" SG_ 2566894922 IAccSpeedLimOfs_FFB54A "i-ACC Speed Limit Offset ";
BA_ "CI_ParId" SG_ 2566890538 WrongWayWarn "ID2418";
BA_ "CI_SigId" SG_ 2566890538 WrongWayWarn 43972;
BA_ "CI_SigName" SG_ 2566890538 WrongWayWarn "Wrong Way Warning";
BA_ "GenSigSendType" SG_ 2566890538 WrongWayWarn 3;
BA_ "GenSigTimeoutTime_PCM" SG_ 2566890538 WrongWayWarn 5000;
BA_ "SigType" SG_ 2566890538 WrongWayWarn 4;
BA_ "CI_ParId" SG_ 2566890538 SpeedLimWarn "ID2416";
BA_ "CI_SigId" SG_ 2566890538 SpeedLimWarn 43970;
BA_ "CI_SigName" SG_ 2566890538 SpeedLimWarn "Speed Limit Warning";
BA_ "GenSigSendType" SG_ 2566890538 SpeedLimWarn 3;
BA_ "GenSigTimeoutTime_PCM" SG_ 2566890538 SpeedLimWarn 5000;
BA_ "SigType" SG_ 2566890538 SpeedLimWarn 4;
BA_ "CI_ParId" SG_ 2566890538 NoOverpassingWarn "ID2415";
BA_ "CI_SigId" SG_ 2566890538 NoOverpassingWarn 43969;
BA_ "CI_SigName" SG_ 2566890538 NoOverpassingWarn "No Overpassing Warning";
BA_ "GenSigSendType" SG_ 2566890538 NoOverpassingWarn 3;
BA_ "GenSigTimeoutTime_PCM" SG_ 2566890538 NoOverpassingWarn 5000;
BA_ "SigType" SG_ 2566890538 NoOverpassingWarn 4;
BA_ "CI_ParId" SG_ 2566890538 GivewayTimeToEvt "ID2406";
BA_ "CI_SigId" SG_ 2566890538 GivewayTimeToEvt 43968;
BA_ "CI_SigName" SG_ 2566890538 GivewayTimeToEvt "GiveWay Time to Event";
BA_ "GenSigSendType" SG_ 2566890538 GivewayTimeToEvt 3;
BA_ "GenSigTimeoutTime_PCM" SG_ 2566890538 GivewayTimeToEvt 5000;
BA_ "CI_ParId" SG_ 2566890538 GivewayDistToEvt "ID2405";
BA_ "CI_SigId" SG_ 2566890538 GivewayDistToEvt 43967;
BA_ "CI_SigName" SG_ 2566890538 GivewayDistToEvt "GiveWay Distance to Event";
BA_ "GenSigSendType" SG_ 2566890538 GivewayDistToEvt 3;
BA_ "GenSigTimeoutTime_PCM" SG_ 2566890538 GivewayDistToEvt 5000;
BA_ "CI_ParId" SG_ 2566890538 GiveWayTypeOfEvt "ID2407";
BA_ "CI_SigId" SG_ 2566890538 GiveWayTypeOfEvt 43966;
BA_ "CI_SigName" SG_ 2566890538 GiveWayTypeOfEvt "Give Way Type of Event";
BA_ "GenSigSendType" SG_ 2566890538 GiveWayTypeOfEvt 3;
BA_ "GenSigTimeoutTime_PCM" SG_ 2566890538 GiveWayTypeOfEvt 5000;
BA_ "CI_ParId" SG_ 2566890538 NoOverpassingSts "ID2408";
BA_ "CI_SigId" SG_ 2566890538 NoOverpassingSts 42385;
BA_ "CI_SigName" SG_ 2566890538 NoOverpassingSts "No Overpassing Status";
BA_ "GenSigSendType" SG_ 2566890538 NoOverpassingSts 3;
BA_ "GenSigTimeoutTime_PCM" SG_ 2566890538 NoOverpassingSts 5000;
BA_ "CI_ParId" SG_ 2566890538 SpeedLimUnitless "ID2412";
BA_ "CI_SigId" SG_ 2566890538 SpeedLimUnitless 42384;
BA_ "CI_SigName" SG_ 2566890538 SpeedLimUnitless "Speed Limit Unitless";
BA_ "GenSigSendType" SG_ 2566890538 SpeedLimUnitless 3;
BA_ "GenSigTimeoutTime_PCM" SG_ 2566890538 SpeedLimUnitless 5000;
BA_ "CI_ParId" SG_ 2566890538 SupplSignInfo "ID2414";
BA_ "CI_SigId" SG_ 2566890538 SupplSignInfo 42383;
BA_ "CI_SigName" SG_ 2566890538 SupplSignInfo "Supplementary Sign Info";
BA_ "GenSigSendType" SG_ 2566890538 SupplSignInfo 3;
BA_ "GenSigTimeoutTime_PCM" SG_ 2566890538 SupplSignInfo 5000;
BA_ "CI_ParId" SG_ 2566890538 TrafficSignType "ID2410";
BA_ "CI_SigId" SG_ 2566890538 TrafficSignType 42381;
BA_ "CI_SigName" SG_ 2566890538 TrafficSignType "Traffic Sign Type";
BA_ "GenSigSendType" SG_ 2566890538 TrafficSignType 3;
BA_ "GenSigTimeoutTime_PCM" SG_ 2566890538 TrafficSignType 5000;
BA_ "CI_ParId" SG_ 2566852119 QaMode "I458";
BA_ "CI_SigId" SG_ 2566852119 QaMode 6401;
BA_ "CI_SigName" SG_ 2566852119 QaMode "Queue Assist Mode";
BA_ "GenSigSendType" SG_ 2566852119 QaMode 3;
BA_ "GenSigTimeoutTime_PCM" SG_ 2566852119 QaMode 5000;
BA_ "CI_ParId" SG_ 2566852119 LkaStr "I423";
BA_ "CI_SigId" SG_ 2566852119 LkaStr 6400;
BA_ "CI_SigName" SG_ 2566852119 LkaStr "Lane Keep Assist Strength";
BA_ "GenSigSendType" SG_ 2566852119 LkaStr 3;
BA_ "GenSigTimeoutTime_PCM" SG_ 2566852119 LkaStr 5000;
BA_ "CI_ParId" SG_ 2566852119 LaneSensDist "I422";
BA_ "CI_SigId" SG_ 2566852119 LaneSensDist 6399;
BA_ "CI_SigName" SG_ 2566852119 LaneSensDist "Lane Sense Distance";
BA_ "GenSigSendType" SG_ 2566852119 LaneSensDist 3;
BA_ "GenSigTimeoutTime_PCM" SG_ 2566852119 LaneSensDist 5000;
BA_ "CI_ParId" SG_ 2566852119 LatCtrlFunctsAudioMute "ID2397";
BA_ "CI_SigId" SG_ 2566852119 LatCtrlFunctsAudioMute 43960;
BA_ "CI_SigName" SG_ 2566852119 LatCtrlFunctsAudioMute "Lateral Control Functions Audio Mute";
BA_ "GenSigSendType" SG_ 2566852119 LatCtrlFunctsAudioMute 3;
BA_ "GenSigTimeoutTime_PCM" SG_ 2566852119 LatCtrlFunctsAudioMute 5000;
BA_ "SigType" SG_ 2566852119 LatCtrlFunctsAudioMute 4;
BA_ "CI_ParId" SG_ 2566852119 Lca "I401";
BA_ "CI_SigId" SG_ 2566852119 Lca 6398;
BA_ "CI_SigName" SG_ 2566852119 Lca "Lane Centering Assist";
BA_ "GenSigSendType" SG_ 2566852119 Lca 3;
BA_ "GenSigTimeoutTime_PCM" SG_ 2566852119 Lca 5000;
BA_ "SigType" SG_ 2566852119 Lca 4;
BA_ "CI_ParId" SG_ 2566852119 Lka "I400";
BA_ "CI_SigId" SG_ 2566852119 Lka 6397;
BA_ "CI_SigName" SG_ 2566852119 Lka "Lane Keep Assist";
BA_ "GenSigSendType" SG_ 2566852119 Lka 3;
BA_ "GenSigTimeoutTime_PCM" SG_ 2566852119 Lka 5000;
BA_ "SigType" SG_ 2566852119 Lka 4;
BA_ "CI_ParId" SG_ 2566852119 AccOvertakePrev "ID2391";
BA_ "CI_SigId" SG_ 2566852119 AccOvertakePrev 43782;
BA_ "CI_SigName" SG_ 2566852119 AccOvertakePrev "ACC Overtake Prevention";
BA_ "GenSigSendType" SG_ 2566852119 AccOvertakePrev 3;
BA_ "GenSigTimeoutTime_PCM" SG_ 2566852119 AccOvertakePrev 5000;
BA_ "SigType" SG_ 2566852119 AccOvertakePrev 4;
BA_ "CI_ParId" SG_ 2566852119 ParkBrkAutoApply "I377";
BA_ "CI_SigId" SG_ 2566852119 ParkBrkAutoApply 6394;
BA_ "CI_SigName" SG_ 2566852119 ParkBrkAutoApply "Park Brake Auto Apply";
BA_ "GenSigSendType" SG_ 2566852119 ParkBrkAutoApply 3;
BA_ "GenSigTimeoutTime_PCM" SG_ 2566852119 ParkBrkAutoApply 5000;
BA_ "SigType" SG_ 2566852119 ParkBrkAutoApply 4;
BA_ "CI_ParId" SG_ 2566852119 ParkBrkDrivAw "I424";
BA_ "CI_SigId" SG_ 2566852119 ParkBrkDrivAw 6393;
BA_ "CI_SigName" SG_ 2566852119 ParkBrkDrivAw "Park Brake Drive Away";
BA_ "GenSigSendType" SG_ 2566852119 ParkBrkDrivAw 3;
BA_ "GenSigTimeoutTime_PCM" SG_ 2566852119 ParkBrkDrivAw 5000;
BA_ "SigType" SG_ 2566852119 ParkBrkDrivAw 4;
BA_ "CI_ParId" SG_ 2566852129 Hdc_FF0E21 "I398";
BA_ "CI_SigId" SG_ 2566852129 Hdc_FF0E21 44307;
BA_ "CI_SigName" SG_ 2566852129 Hdc_FF0E21 "Hill Descent Control";
BA_ "GenSigSendType" SG_ 2566852129 Hdc_FF0E21 3;
BA_ "GenSigTimeoutTime_PCM" SG_ 2566852129 Hdc_FF0E21 5000;
BA_ "CI_ParId" SG_ 2566852129 LatCtrlFunctsAudioMute_FF0E21 "ID2397";
BA_ "CI_SigId" SG_ 2566852129 LatCtrlFunctsAudioMute_FF0E21 43953;
BA_ "CI_SigName" SG_ 2566852129 LatCtrlFunctsAudioMute_FF0E21 "Lateral Control Functions Audio Mute";
BA_ "GenSigSendType" SG_ 2566852129 LatCtrlFunctsAudioMute_FF0E21 3;
BA_ "GenSigTimeoutTime_PCM" SG_ 2566852129 LatCtrlFunctsAudioMute_FF0E21 5000;
BA_ "SigType" SG_ 2566852129 LatCtrlFunctsAudioMute_FF0E21 4;
BA_ "CI_ParId" SG_ 2566852129 PwrSteerCityMode "I399";
BA_ "CI_SigId" SG_ 2566852129 PwrSteerCityMode 6407;
BA_ "CI_SigName" SG_ 2566852129 PwrSteerCityMode "Power Steering City Mode";
BA_ "GenSigSendType" SG_ 2566852129 PwrSteerCityMode 3;
BA_ "GenSigTimeoutTime_PCM" SG_ 2566852129 PwrSteerCityMode 5000;
BA_ "SigType" SG_ 2566852129 PwrSteerCityMode 4;
BA_ "CI_ParId" SG_ 2566852138 LcaIntervRh "ID2425";
BA_ "CI_SigId" SG_ 2566852138 LcaIntervRh 44234;
BA_ "CI_SigName" SG_ 2566852138 LcaIntervRh "Lane Centering Intervention Right Hand ";
BA_ "GenSigSendType" SG_ 2566852138 LcaIntervRh 3;
BA_ "GenSigTimeoutTime_PCM" SG_ 2566852138 LcaIntervRh 5000;
BA_ "SigType" SG_ 2566852138 LcaIntervRh 4;
BA_ "CI_ParId" SG_ 2566852138 LcaIntervLh "ID2424";
BA_ "CI_SigId" SG_ 2566852138 LcaIntervLh 44233;
BA_ "CI_SigName" SG_ 2566852138 LcaIntervLh "Lane Centering Intervention Left Hand ";
BA_ "GenSigSendType" SG_ 2566852138 LcaIntervLh 3;
BA_ "GenSigTimeoutTime_PCM" SG_ 2566852138 LcaIntervLh 5000;
BA_ "SigType" SG_ 2566852138 LcaIntervLh 4;
BA_ "CI_ParId" SG_ 2566852138 LkaSysSts "I428";
BA_ "CI_SigId" SG_ 2566852138 LkaSysSts 6417;
BA_ "CI_SigName" SG_ 2566852138 LkaSysSts "Lane Keep Assist System State";
BA_ "GenSigSendType" SG_ 2566852138 LkaSysSts 3;
BA_ "GenSigTimeoutTime_PCM" SG_ 2566852138 LkaSysSts 5000;
BA_ "CI_ParId" SG_ 2566852138 LkaIntervRh "I427";
BA_ "CI_SigId" SG_ 2566852138 LkaIntervRh 44526;
BA_ "CI_SigName" SG_ 2566852138 LkaIntervRh "Lane Keep Assist Intervention Right Hand ";
BA_ "GenSigSendType" SG_ 2566852138 LkaIntervRh 3;
BA_ "GenSigTimeoutTime_PCM" SG_ 2566852138 LkaIntervRh 5000;
BA_ "SigType" SG_ 2566852138 LkaIntervRh 4;
BA_ "CI_ParId" SG_ 2566852138 LkaIntervLh "I426";
BA_ "CI_SigId" SG_ 2566852138 LkaIntervLh 44525;
BA_ "CI_SigName" SG_ 2566852138 LkaIntervLh "Lane Keep Assist Intervention Left Hand ";
BA_ "GenSigSendType" SG_ 2566852138 LkaIntervLh 3;
BA_ "GenSigTimeoutTime_PCM" SG_ 2566852138 LkaIntervLh 5000;
BA_ "SigType" SG_ 2566852138 LkaIntervLh 4;
BA_ "CI_ParId" SG_ 2566852138 LcaSysSts "ID2423";
BA_ "CI_SigId" SG_ 2566852138 LcaSysSts 44232;
BA_ "CI_SigName" SG_ 2566852138 LcaSysSts "Lane Centering System Status";
BA_ "GenSigSendType" SG_ 2566852138 LcaSysSts 3;
BA_ "GenSigTimeoutTime_PCM" SG_ 2566852138 LcaSysSts 5000;
BA_ "CI_ParId" SG_ 2566852138 QaMode_FF0E2A "I458";
BA_ "CI_SigId" SG_ 2566852138 QaMode_FF0E2A 43738;
BA_ "CI_SigName" SG_ 2566852138 QaMode_FF0E2A "Queue Assist Mode";
BA_ "GenSigSendType" SG_ 2566852138 QaMode_FF0E2A 3;
BA_ "GenSigTimeoutTime_PCM" SG_ 2566852138 QaMode_FF0E2A 5000;
BA_ "CI_ParId" SG_ 2566852138 TrafficJamAss "ID2400";
BA_ "CI_SigId" SG_ 2566852138 TrafficJamAss 43956;
BA_ "CI_SigName" SG_ 2566852138 TrafficJamAss "Traffic Jam Assist";
BA_ "GenSigSendType" SG_ 2566852138 TrafficJamAss 3;
BA_ "GenSigTimeoutTime_PCM" SG_ 2566852138 TrafficJamAss 5000;
BA_ "SigType" SG_ 2566852138 TrafficJamAss 4;
BA_ "CI_ParId" SG_ 2566852138 Lca_FF0E2A "I401";
BA_ "CI_SigId" SG_ 2566852138 Lca_FF0E2A 6412;
BA_ "CI_SigName" SG_ 2566852138 Lca_FF0E2A "Lane Centering Assist";
BA_ "GenSigSendType" SG_ 2566852138 Lca_FF0E2A 3;
BA_ "GenSigTimeoutTime_PCM" SG_ 2566852138 Lca_FF0E2A 5000;
BA_ "SigType" SG_ 2566852138 Lca_FF0E2A 4;
BA_ "CI_ParId" SG_ 2566852138 Lka_FF0E2A "I400";
BA_ "CI_SigId" SG_ 2566852138 Lka_FF0E2A 6411;
BA_ "CI_SigName" SG_ 2566852138 Lka_FF0E2A "Lane Keep Assist";
BA_ "GenSigSendType" SG_ 2566852138 Lka_FF0E2A 3;
BA_ "GenSigTimeoutTime_PCM" SG_ 2566852138 Lka_FF0E2A 5000;
BA_ "SigType" SG_ 2566852138 Lka_FF0E2A 4;
BA_ "CI_ParId" SG_ 2566852138 Ldw "I421";
BA_ "CI_SigId" SG_ 2566852138 Ldw 6410;
BA_ "CI_SigName" SG_ 2566852138 Ldw "Lane Departure Warning";
BA_ "GenSigSendType" SG_ 2566852138 Ldw 3;
BA_ "GenSigTimeoutTime_PCM" SG_ 2566852138 Ldw 5000;
BA_ "SigType" SG_ 2566852138 Ldw 4;
BA_ "CI_ParId" SG_ 2566852138 AhbcTurnOffReas "ID2390";
BA_ "CI_SigId" SG_ 2566852138 AhbcTurnOffReas 43781;
BA_ "CI_SigName" SG_ 2566852138 AhbcTurnOffReas "AHBC Turn Off Reason";
BA_ "GenSigSendType" SG_ 2566852138 AhbcTurnOffReas 3;
BA_ "CI_ParId" SG_ 2566852138 AccOvertakePrev_FF0E2A "ID2391";
BA_ "CI_SigId" SG_ 2566852138 AccOvertakePrev_FF0E2A 43783;
BA_ "CI_SigName" SG_ 2566852138 AccOvertakePrev_FF0E2A "ACC Overtake Prevention";
BA_ "GenSigSendType" SG_ 2566852138 AccOvertakePrev_FF0E2A 3;
BA_ "GenSigTimeoutTime_PCM" SG_ 2566852138 AccOvertakePrev_FF0E2A 5000;
BA_ "SigType" SG_ 2566852138 AccOvertakePrev_FF0E2A 4;
BA_ "CI_ParId" SG_ 2583664161 WndLifterRight "ID2500";
BA_ "CI_SigId" SG_ 2583664161 WndLifterRight 44708;
BA_ "CI_SigName" SG_ 2583664161 WndLifterRight "Window Lifter Right";
BA_ "CI_ParId" SG_ 2583664161 WndLifterLeft "ID2499";
BA_ "CI_SigId" SG_ 2583664161 WndLifterLeft 44707;
BA_ "CI_SigName" SG_ 2583664161 WndLifterLeft "Window Lifter Left";
BA_ "CI_ParId" SG_ 2583664161 Door5Lck_Unlck "ID2498";
BA_ "CI_SigId" SG_ 2583664161 Door5Lck_Unlck 44706;
BA_ "CI_SigName" SG_ 2583664161 Door5Lck_Unlck "Door 5 Lock/Unlock";
BA_ "SigType" SG_ 2583664161 Door5Lck_Unlck 4;
BA_ "CI_ParId" SG_ 2583664161 Door4Lck_Unlck "ID2497";
BA_ "CI_SigId" SG_ 2583664161 Door4Lck_Unlck 44705;
BA_ "CI_SigName" SG_ 2583664161 Door4Lck_Unlck "Door 4 Lock/Unlock";
BA_ "SigType" SG_ 2583664161 Door4Lck_Unlck 4;
BA_ "CI_ParId" SG_ 2583664161 Door3Lck_Unlck "ID2496";
BA_ "CI_SigId" SG_ 2583664161 Door3Lck_Unlck 44704;
BA_ "CI_SigName" SG_ 2583664161 Door3Lck_Unlck "Door 3 Lock/Unlock";
BA_ "SigType" SG_ 2583664161 Door3Lck_Unlck 4;
BA_ "CI_ParId" SG_ 2583664161 Door2Lck_Unlck "ID2495";
BA_ "CI_SigId" SG_ 2583664161 Door2Lck_Unlck 44703;
BA_ "CI_SigName" SG_ 2583664161 Door2Lck_Unlck "Door 2 Lock/Unlock";
BA_ "SigType" SG_ 2583664161 Door2Lck_Unlck 4;
BA_ "CI_ParId" SG_ 2583664161 Door1Lck_Unlck "ID2494";
BA_ "CI_SigId" SG_ 2583664161 Door1Lck_Unlck 44702;
BA_ "CI_SigName" SG_ 2583664161 Door1Lck_Unlck "Door 1 Lock/Unlock";
BA_ "SigType" SG_ 2583664161 Door1Lck_Unlck 4;
BA_ "CI_ParId" SG_ 2583664161 MsgCntEx "ID2493";
BA_ "CI_SigId" SG_ 2583664161 MsgCntEx 44701;
BA_ "CI_SigName" SG_ 2583664161 MsgCntEx "Message Counter Extended";
BA_ "CI_ParId" SG_ 2583664161 TruncatedMac "ID2492";
BA_ "CI_SigId" SG_ 2583664161 TruncatedMac 44700;
BA_ "CI_SigName" SG_ 2583664161 TruncatedMac "Truncated MAC";
BA_ "CI_ParId" SG_ 2583664202 WndLifterRight_FF964A "ID2500";
BA_ "CI_SigId" SG_ 2583664202 WndLifterRight_FF964A 44698;
BA_ "CI_SigName" SG_ 2583664202 WndLifterRight_FF964A "Window Lifter Right";
BA_ "CI_ParId" SG_ 2583664202 WndLifterLeft_FF964A "ID2499";
BA_ "CI_SigId" SG_ 2583664202 WndLifterLeft_FF964A 44697;
BA_ "CI_SigName" SG_ 2583664202 WndLifterLeft_FF964A "Window Lifter Left";
BA_ "CI_ParId" SG_ 2583664202 Door5Lck_Unlck_FF964A "ID2498";
BA_ "CI_SigId" SG_ 2583664202 Door5Lck_Unlck_FF964A 44696;
BA_ "CI_SigName" SG_ 2583664202 Door5Lck_Unlck_FF964A "Door 5 Lock/Unlock";
BA_ "SigType" SG_ 2583664202 Door5Lck_Unlck_FF964A 4;
BA_ "CI_ParId" SG_ 2583664202 Door4Lck_Unlck_FF964A "ID2497";
BA_ "CI_SigId" SG_ 2583664202 Door4Lck_Unlck_FF964A 44695;
BA_ "CI_SigName" SG_ 2583664202 Door4Lck_Unlck_FF964A "Door 4 Lock/Unlock";
BA_ "SigType" SG_ 2583664202 Door4Lck_Unlck_FF964A 4;
BA_ "CI_ParId" SG_ 2583664202 Door3Lck_Unlck_FF964A "ID2496";
BA_ "CI_SigId" SG_ 2583664202 Door3Lck_Unlck_FF964A 44694;
BA_ "CI_SigName" SG_ 2583664202 Door3Lck_Unlck_FF964A "Door 3 Lock/Unlock";
BA_ "SigType" SG_ 2583664202 Door3Lck_Unlck_FF964A 4;
BA_ "CI_ParId" SG_ 2583664202 Door2Lck_Unlck_FF964A "ID2495";
BA_ "CI_SigId" SG_ 2583664202 Door2Lck_Unlck_FF964A 44693;
BA_ "CI_SigName" SG_ 2583664202 Door2Lck_Unlck_FF964A "Door 2 Lock/Unlock";
BA_ "SigType" SG_ 2583664202 Door2Lck_Unlck_FF964A 4;
BA_ "CI_ParId" SG_ 2583664202 Door1Lck_Unlck_FF964A "ID2494";
BA_ "CI_SigId" SG_ 2583664202 Door1Lck_Unlck_FF964A 44692;
BA_ "CI_SigName" SG_ 2583664202 Door1Lck_Unlck_FF964A "Door 1 Lock/Unlock";
BA_ "SigType" SG_ 2583664202 Door1Lck_Unlck_FF964A 4;
BA_ "CI_ParId" SG_ 2583664202 MsgCntEx_FF964A "ID2493";
BA_ "CI_SigId" SG_ 2583664202 MsgCntEx_FF964A 44691;
BA_ "CI_SigName" SG_ 2583664202 MsgCntEx_FF964A "Message Counter Extended";
BA_ "CI_ParId" SG_ 2583664202 TruncatedMac_FF964A "ID2492";
BA_ "CI_SigId" SG_ 2583664202 TruncatedMac_FF964A 44690;
BA_ "CI_SigName" SG_ 2583664202 TruncatedMac_FF964A "Truncated MAC";
BA_ "CI_ParId" SG_ 2583664417 CrkEnaReq "ID2484";
BA_ "CI_SigId" SG_ 2583664417 CrkEnaReq 44729;
BA_ "CI_SigName" SG_ 2583664417 CrkEnaReq "Crank Enable Request";
BA_ "SigType" SG_ 2583664417 CrkEnaReq 4;
BA_ "CI_ParId" SG_ 2583664417 MsgCntEx_FF9721 "ID2493";
BA_ "CI_SigId" SG_ 2583664417 MsgCntEx_FF9721 44728;
BA_ "CI_SigName" SG_ 2583664417 MsgCntEx_FF9721 "Message Counter Extended";
BA_ "CI_ParId" SG_ 2583664417 TruncatedMac_FF9721 "ID2492";
BA_ "CI_SigId" SG_ 2583664417 TruncatedMac_FF9721 44727;
BA_ "CI_SigName" SG_ 2583664417 TruncatedMac_FF9721 "Truncated MAC";
BA_ "CI_ParId" SG_ 2583664458 CrkEnaReq_FF974A "ID2484";
BA_ "CI_SigId" SG_ 2583664458 CrkEnaReq_FF974A 44712;
BA_ "CI_SigName" SG_ 2583664458 CrkEnaReq_FF974A "Crank Enable Request";
BA_ "SigType" SG_ 2583664458 CrkEnaReq_FF974A 4;
BA_ "CI_ParId" SG_ 2583664458 MsgCntEx_FF974A "ID2493";
BA_ "CI_SigId" SG_ 2583664458 MsgCntEx_FF974A 44711;
BA_ "CI_SigName" SG_ 2583664458 MsgCntEx_FF974A "Message Counter Extended";
BA_ "CI_ParId" SG_ 2583664458 TruncatedMac_FF974A "ID2492";
BA_ "CI_SigId" SG_ 2583664458 TruncatedMac_FF974A 44710;
BA_ "CI_SigName" SG_ 2583664458 TruncatedMac_FF974A "Truncated MAC";
BA_ "CI_ParId" SG_ 2365579287 WakeupInDozeMode "I029";
BA_ "CI_SigId" SG_ 2365579287 WakeupInDozeMode 26532;
BA_ "CI_SigName" SG_ 2365579287 WakeupInDozeMode "WakeUp In Doze Mode";
BA_ "GenSigSendType" SG_ 2365579287 WakeupInDozeMode 5;
BA_ "GenSigTimeoutTime_PCM" SG_ 2365579287 WakeupInDozeMode 5000;
BA_ "SigType" SG_ 2365579287 WakeupInDozeMode 4;
BA_ "CI_ParId" SG_ 2365579303 MsgCks_FE027 "4207";
BA_ "CI_SigId" SG_ 2365579303 MsgCks_FE027 26559;
BA_ "CI_SigName" SG_ 2365579303 MsgCks_FE027 "Message Checksum";
BA_ "GenSigSendType" SG_ 2365579303 MsgCks_FE027 5;
BA_ "GenSigTimeoutTime_PCM" SG_ 2365579303 MsgCks_FE027 5000;
BA_ "SPN" SG_ 2365579303 MsgCks_FE027 4207;
BA_ "CI_ParId" SG_ 2365579303 MsgCnt_FE027 "4206";
BA_ "CI_SigId" SG_ 2365579303 MsgCnt_FE027 26558;
BA_ "CI_SigName" SG_ 2365579303 MsgCnt_FE027 "Message Counter";
BA_ "GenSigSendType" SG_ 2365579303 MsgCnt_FE027 5;
BA_ "GenSigTimeoutTime_PCM" SG_ 2365579303 MsgCnt_FE027 5000;
BA_ "SPN" SG_ 2365579303 MsgCnt_FE027 4206;
BA_ "CI_ParId" SG_ 2365579303 WakeupBus "I015";
BA_ "CI_SigId" SG_ 2365579303 WakeupBus 26557;
BA_ "CI_SigName" SG_ 2365579303 WakeupBus "Wakeup Bus";
BA_ "GenSigSendType" SG_ 2365579303 WakeupBus 5;
BA_ "GenSigTimeoutTime_PCM" SG_ 2365579303 WakeupBus 5000;
BA_ "CI_ParId" SG_ 2365579303 WakeupInDozeMode_FE027 "I029";
BA_ "CI_SigId" SG_ 2365579303 WakeupInDozeMode_FE027 26554;
BA_ "CI_SigName" SG_ 2365579303 WakeupInDozeMode_FE027 "WakeUp In Doze Mode";
BA_ "GenSigSendType" SG_ 2365579303 WakeupInDozeMode_FE027 5;
BA_ "GenSigTimeoutTime_PCM" SG_ 2365579303 WakeupInDozeMode_FE027 5000;
BA_ "SigType" SG_ 2365579303 WakeupInDozeMode_FE027 4;
BA_ "CI_ParId" SG_ 2365579329 WakeupInDozeMode_FE041 "I029";
BA_ "CI_SigId" SG_ 2365579329 WakeupInDozeMode_FE041 26570;
BA_ "CI_SigName" SG_ 2365579329 WakeupInDozeMode_FE041 "WakeUp In Doze Mode";
BA_ "GenSigSendType" SG_ 2365579329 WakeupInDozeMode_FE041 5;
BA_ "GenSigTimeoutTime_PCM" SG_ 2365579329 WakeupInDozeMode_FE041 5000;
BA_ "SigType" SG_ 2365579329 WakeupInDozeMode_FE041 4;
BA_ "CI_ParId" SG_ 2365579338 MsgCks_FE04A "4207";
BA_ "CI_SigId" SG_ 2365579338 MsgCks_FE04A 26582;
BA_ "CI_SigName" SG_ 2365579338 MsgCks_FE04A "Message Checksum";
BA_ "GenSigSendType" SG_ 2365579338 MsgCks_FE04A 5;
BA_ "GenSigTimeoutTime_SGW" SG_ 2365579338 MsgCks_FE04A 5000;
BA_ "SPN" SG_ 2365579338 MsgCks_FE04A 4207;
BA_ "CI_ParId" SG_ 2365579338 MsgCnt_FE04A "4206";
BA_ "CI_SigId" SG_ 2365579338 MsgCnt_FE04A 26581;
BA_ "CI_SigName" SG_ 2365579338 MsgCnt_FE04A "Message Counter";
BA_ "GenSigSendType" SG_ 2365579338 MsgCnt_FE04A 5;
BA_ "GenSigTimeoutTime_SGW" SG_ 2365579338 MsgCnt_FE04A 5000;
BA_ "SPN" SG_ 2365579338 MsgCnt_FE04A 4206;
BA_ "CI_ParId" SG_ 2365579338 WakeupInDozeMode_FE04A "I029";
BA_ "CI_SigId" SG_ 2365579338 WakeupInDozeMode_FE04A 26577;
BA_ "CI_SigName" SG_ 2365579338 WakeupInDozeMode_FE04A "WakeUp In Doze Mode";
BA_ "GenSigSendType" SG_ 2365579338 WakeupInDozeMode_FE04A 5;
BA_ "GenSigTimeoutTime_SGW" SG_ 2365579338 WakeupInDozeMode_FE04A 5000;
BA_ "SigType" SG_ 2365579338 WakeupInDozeMode_FE04A 4;
BA_ "CI_ParId" SG_ 2365579341 MsgCks_FE04D "4207";
BA_ "CI_SigId" SG_ 2365579341 MsgCks_FE04D 26589;
BA_ "CI_SigName" SG_ 2365579341 MsgCks_FE04D "Message Checksum";
BA_ "GenSigSendType" SG_ 2365579341 MsgCks_FE04D 5;
BA_ "GenSigTimeoutTime_PCM" SG_ 2365579341 MsgCks_FE04D 5000;
BA_ "SPN" SG_ 2365579341 MsgCks_FE04D 4207;
BA_ "CI_ParId" SG_ 2365579341 MsgCnt_FE04D "4206";
BA_ "CI_SigId" SG_ 2365579341 MsgCnt_FE04D 26588;
BA_ "CI_SigName" SG_ 2365579341 MsgCnt_FE04D "Message Counter";
BA_ "GenSigSendType" SG_ 2365579341 MsgCnt_FE04D 5;
BA_ "GenSigTimeoutTime_PCM" SG_ 2365579341 MsgCnt_FE04D 5000;
BA_ "SPN" SG_ 2365579341 MsgCnt_FE04D 4206;
BA_ "CI_ParId" SG_ 2365579341 BatMainSwHoldReq_FE04D "1682";
BA_ "CI_SigId" SG_ 2365579341 BatMainSwHoldReq_FE04D 26585;
BA_ "CI_SigName" SG_ 2365579341 BatMainSwHoldReq_FE04D "Battery Main Switch Hold Request";
BA_ "GenSigSendType" SG_ 2365579341 BatMainSwHoldReq_FE04D 5;
BA_ "GenSigTimeoutTime_PCM" SG_ 2365579341 BatMainSwHoldReq_FE04D 5000;
BA_ "SPN" SG_ 2365579341 BatMainSwHoldReq_FE04D 1682;
BA_ "SigType" SG_ 2365579341 BatMainSwHoldReq_FE04D 4;
BA_ "CI_ParId" SG_ 2365575713 MsgCks_FD221 "4207";
BA_ "CI_SigId" SG_ 2365575713 MsgCks_FD221 26520;
BA_ "CI_SigName" SG_ 2365575713 MsgCks_FD221 "Message Checksum";
BA_ "GenSigSendType" SG_ 2365575713 MsgCks_FD221 3;
BA_ "GenSigTimeoutTime_PCM" SG_ 2365575713 MsgCks_FD221 5000;
BA_ "SPN" SG_ 2365575713 MsgCks_FD221 4207;
BA_ "CI_ParId" SG_ 2365575713 MsgCnt_FD221 "4206";
BA_ "CI_SigId" SG_ 2365575713 MsgCnt_FD221 26519;
BA_ "CI_SigName" SG_ 2365575713 MsgCnt_FD221 "Message Counter";
BA_ "GenSigSendType" SG_ 2365575713 MsgCnt_FD221 3;
BA_ "GenSigTimeoutTime_PCM" SG_ 2365575713 MsgCnt_FD221 5000;
BA_ "SPN" SG_ 2365575713 MsgCnt_FD221 4206;
BA_ "CI_ParId" SG_ 2365575713 IgnBtnSts "I816";
BA_ "CI_SigId" SG_ 2365575713 IgnBtnSts 33136;
BA_ "CI_SigName" SG_ 2365575713 IgnBtnSts "Ignition Button Status";
BA_ "GenSigSendType" SG_ 2365575713 IgnBtnSts 3;
BA_ "GenSigTimeoutTime_PCM" SG_ 2365575713 IgnBtnSts 5000;
BA_ "SigType" SG_ 2365575713 IgnBtnSts 4;
BA_ "CI_ParId" SG_ 2365575713 EngStarterSts "I186";
BA_ "CI_SigId" SG_ 2365575713 EngStarterSts 26518;
BA_ "CI_SigName" SG_ 2365575713 EngStarterSts "Engine Starter Status";
BA_ "GenSigSendType" SG_ 2365575713 EngStarterSts 3;
BA_ "GenSigTimeoutTime_PCM" SG_ 2365575713 EngStarterSts 5000;
BA_ "SigType" SG_ 2365575713 EngStarterSts 4;
BA_ "CI_ParId" SG_ 2365575713 VehMov_FD221 "I185";
BA_ "CI_SigId" SG_ 2365575713 VehMov_FD221 26517;
BA_ "CI_SigName" SG_ 2365575713 VehMov_FD221 "Vehicle Moving";
BA_ "GenSigSendType" SG_ 2365575713 VehMov_FD221 3;
BA_ "GenSigTimeoutTime_PCM" SG_ 2365575713 VehMov_FD221 5000;
BA_ "SigType" SG_ 2365575713 VehMov_FD221 4;
BA_ "CI_ParId" SG_ 2365575713 EngRun "I184";
BA_ "CI_SigId" SG_ 2365575713 EngRun 26516;
BA_ "CI_SigName" SG_ 2365575713 EngRun "Engine Running";
BA_ "GenSigSendType" SG_ 2365575713 EngRun 3;
BA_ "GenSigTimeoutTime_PCM" SG_ 2365575713 EngRun 5000;
BA_ "SigType" SG_ 2365575713 EngRun 4;
BA_ "CI_ParId" SG_ 2365575713 WakeupBus_FD221 "I015";
BA_ "CI_SigId" SG_ 2365575713 WakeupBus_FD221 26515;
BA_ "CI_SigName" SG_ 2365575713 WakeupBus_FD221 "Wakeup Bus";
BA_ "GenSigSendType" SG_ 2365575713 WakeupBus_FD221 3;
BA_ "GenSigTimeoutTime_PCM" SG_ 2365575713 WakeupBus_FD221 5000;
BA_ "CI_ParId" SG_ 2365575713 IgnOn "I013";
BA_ "CI_SigId" SG_ 2365575713 IgnOn 26514;
BA_ "CI_SigName" SG_ 2365575713 IgnOn "Ignition On";
BA_ "GenSigSendType" SG_ 2365575713 IgnOn 3;
BA_ "GenSigTimeoutTime_PCM" SG_ 2365575713 IgnOn 5000;
BA_ "SigType" SG_ 2365575713 IgnOn 4;
BA_ "CI_ParId" SG_ 2365575713 BatMainSwHoldSts "1681";
BA_ "CI_SigId" SG_ 2365575713 BatMainSwHoldSts 26513;
BA_ "CI_SigName" SG_ 2365575713 BatMainSwHoldSts "Battery Main Switch Hold State";
BA_ "GenSigSendType" SG_ 2365575713 BatMainSwHoldSts 3;
BA_ "GenSigTimeoutTime_PCM" SG_ 2365575713 BatMainSwHoldSts 5000;
BA_ "SPN" SG_ 2365575713 BatMainSwHoldSts 1681;
BA_ "SigType" SG_ 2365575713 BatMainSwHoldSts 4;
BA_ "CI_ParId" SG_ 2365575713 WakeupInDozeMode_FD221 "I029";
BA_ "CI_SigId" SG_ 2365575713 WakeupInDozeMode_FD221 26512;
BA_ "CI_SigName" SG_ 2365575713 WakeupInDozeMode_FD221 "WakeUp In Doze Mode";
BA_ "GenSigSendType" SG_ 2365575713 WakeupInDozeMode_FD221 3;
BA_ "GenSigTimeoutTime_PCM" SG_ 2365575713 WakeupInDozeMode_FD221 5000;
BA_ "SigType" SG_ 2365575713 WakeupInDozeMode_FD221 4;
BA_ "CI_ParId" SG_ 2365528587 WhThCntTs "St007";
BA_ "CI_SigId" SG_ 2365528587 WhThCntTs 6161;
BA_ "CI_SigName" SG_ 2365528587 WhThCntTs "Wheel Tooth Count Timestamp";
BA_ "GenSigTimeoutTime_PCM" SG_ 2365528587 WhThCntTs 500;
BA_ "SigType" SG_ 2365528587 WhThCntTs 1;
BA_ "CI_ParId" SG_ 2365528587 RaRThCnt "St004";
BA_ "CI_SigId" SG_ 2365528587 RaRThCnt 6158;
BA_ "CI_SigName" SG_ 2365528587 RaRThCnt "Rear Axle Right Wheel Tooth Count";
BA_ "GenSigTimeoutTime_PCM" SG_ 2365528587 RaRThCnt 500;
BA_ "SigType" SG_ 2365528587 RaRThCnt 1;
BA_ "CI_ParId" SG_ 2365528587 RaLThCnt "St003";
BA_ "CI_SigId" SG_ 2365528587 RaLThCnt 6157;
BA_ "CI_SigName" SG_ 2365528587 RaLThCnt "Rear Axle Left Wheel Tooth Count";
BA_ "GenSigTimeoutTime_PCM" SG_ 2365528587 RaLThCnt 500;
BA_ "SigType" SG_ 2365528587 RaLThCnt 1;
BA_ "CI_ParId" SG_ 2365528587 FaRThCnt "St002";
BA_ "CI_SigId" SG_ 2365528587 FaRThCnt 6156;
BA_ "CI_SigName" SG_ 2365528587 FaRThCnt "Front Axle Right Wheel Tooth Count";
BA_ "GenSigTimeoutTime_PCM" SG_ 2365528587 FaRThCnt 500;
BA_ "SigType" SG_ 2365528587 FaRThCnt 1;
BA_ "CI_ParId" SG_ 2365528587 FaLThCnt "St001";
BA_ "CI_SigId" SG_ 2365528587 FaLThCnt 6155;
BA_ "CI_SigName" SG_ 2365528587 FaLThCnt "Front Axle Left Wheel Tooth Count";
BA_ "GenSigTimeoutTime_PCM" SG_ 2365528587 FaLThCnt 500;
BA_ "SigType" SG_ 2365528587 FaLThCnt 1;
BA_ "CI_ParId" SG_ 2566891593 WOBC_Power "E037";
BA_ "CI_SigId" SG_ 2566891593 WOBC_Power 35307;
BA_ "CI_SigName" SG_ 2566891593 WOBC_Power "Whole Instantaneous power on OBC";
BA_ "GenSigTimeoutTime_PCM" SG_ 2566891593 WOBC_Power 500;
BA_ "SigType" SG_ 2566891593 WOBC_Power 1;
BA_ "CI_ParId" SG_ 2566891593 WOBC_MaxAvailablePower "E042";
BA_ "CI_SigId" SG_ 2566891593 WOBC_MaxAvailablePower 35306;
BA_ "CI_SigName" SG_ 2566891593 WOBC_MaxAvailablePower "Maximum Power delivered by Whole OBC";
BA_ "GenSigTimeoutTime_PCM" SG_ 2566891593 WOBC_MaxAvailablePower 500;
BA_ "SigType" SG_ 2566891593 WOBC_MaxAvailablePower 1;
BA_ "CI_ParId" SG_ 2566891593 WOBC_MaxAvailableIout "E041";
BA_ "CI_SigId" SG_ 2566891593 WOBC_MaxAvailableIout 35305;
BA_ "CI_SigName" SG_ 2566891593 WOBC_MaxAvailableIout "Maximum available current by Whole OBC";
BA_ "GenSigTimeoutTime_PCM" SG_ 2566891593 WOBC_MaxAvailableIout 500;
BA_ "SigType" SG_ 2566891593 WOBC_MaxAvailableIout 1;
BA_ "CI_ParId" SG_ 2566858007 AudioMute "I289";
BA_ "CI_SigId" SG_ 2566858007 AudioMute 9533;
BA_ "CI_SigName" SG_ 2566858007 AudioMute "Audio Mute";
BA_ "GenSigSendType" SG_ 2566858007 AudioMute 3;
BA_ "GenSigTimeoutTime_PCM" SG_ 2566858007 AudioMute 5000;
BA_ "SigType" SG_ 2566858007 AudioMute 4;
BA_ "CI_ParId" SG_ 2566858007 MutePrioReq "IMH0102";
BA_ "CI_SigId" SG_ 2566858007 MutePrioReq 43016;
BA_ "CI_SigName" SG_ 2566858007 MutePrioReq "Mute Priority Request";
BA_ "GenSigSendType" SG_ 2566858007 MutePrioReq 3;
BA_ "GenSigTimeoutTime_PCM" SG_ 2566858007 MutePrioReq 5000;
BA_ "CI_ParId" SG_ 2566858007 CallFromLogIx "I460";
BA_ "CI_SigId" SG_ 2566858007 CallFromLogIx 9530;
BA_ "CI_SigName" SG_ 2566858007 CallFromLogIx "Call From Log Index";
BA_ "GenSigSendType" SG_ 2566858007 CallFromLogIx 3;
BA_ "GenSigTimeoutTime_PCM" SG_ 2566858007 CallFromLogIx 5000;
BA_ "CI_ParId" SG_ 2566858007 UnitSysSet "I1078";
BA_ "CI_SigId" SG_ 2566858007 UnitSysSet 44743;
BA_ "CI_SigName" SG_ 2566858007 UnitSysSet "Unit System Setting";
BA_ "GenSigSendType" SG_ 2566858007 UnitSysSet 3;
BA_ "GenSigTimeoutTime_PCM" SG_ 2566858007 UnitSysSet 5000;
BA_ "SigType" SG_ 2566858007 UnitSysSet 4;
BA_ "CI_ParId" SG_ 2566858007 DevIx_FF2517 "I1001";
BA_ "CI_SigId" SG_ 2566858007 DevIx_FF2517 42032;
BA_ "CI_SigName" SG_ 2566858007 DevIx_FF2517 "Device Index";
BA_ "GenSigSendType" SG_ 2566858007 DevIx_FF2517 3;
BA_ "GenSigTimeoutTime_PCM" SG_ 2566858007 DevIx_FF2517 5000;
BA_ "SigType" SG_ 2566858007 DevIx_FF2517 4;
BA_ "CI_ParId" SG_ 2566858017 AudioMute_FF2521 "I289";
BA_ "CI_SigId" SG_ 2566858017 AudioMute_FF2521 9547;
BA_ "CI_SigName" SG_ 2566858017 AudioMute_FF2521 "Audio Mute";
BA_ "GenSigSendType" SG_ 2566858017 AudioMute_FF2521 3;
BA_ "GenSigTimeoutTime_PCM" SG_ 2566858017 AudioMute_FF2521 5000;
BA_ "SigType" SG_ 2566858017 AudioMute_FF2521 4;
BA_ "CI_ParId" SG_ 2566858017 Track_RadioUp_Dw "I295";
BA_ "CI_SigId" SG_ 2566858017 Track_RadioUp_Dw 9542;
BA_ "CI_SigName" SG_ 2566858017 Track_RadioUp_Dw "Track/Radio Up/Down";
BA_ "GenSigSendType" SG_ 2566858017 Track_RadioUp_Dw 3;
BA_ "GenSigTimeoutTime_PCM" SG_ 2566858017 Track_RadioUp_Dw 5000;
BA_ "SigType" SG_ 2566858017 Track_RadioUp_Dw 4;
BA_ "CI_ParId" SG_ 2566858017 SrcUp_Dw "I292";
BA_ "CI_SigId" SG_ 2566858017 SrcUp_Dw 9540;
BA_ "CI_SigName" SG_ 2566858017 SrcUp_Dw "Source Up/Down";
BA_ "GenSigSendType" SG_ 2566858017 SrcUp_Dw 3;
BA_ "GenSigTimeoutTime_PCM" SG_ 2566858017 SrcUp_Dw 5000;
BA_ "SigType" SG_ 2566858017 SrcUp_Dw 4;
BA_ "CI_ParId" SG_ 2566858017 VoiceRec "I291";
BA_ "CI_SigId" SG_ 2566858017 VoiceRec 9538;
BA_ "CI_SigName" SG_ 2566858017 VoiceRec "Voice Recognition";
BA_ "GenSigSendType" SG_ 2566858017 VoiceRec 3;
BA_ "GenSigTimeoutTime_PCM" SG_ 2566858017 VoiceRec 5000;
BA_ "SigType" SG_ 2566858017 VoiceRec 4;
BA_ "CI_ParId" SG_ 2566858017 PhoneCallCmd "I290";
BA_ "CI_SigId" SG_ 2566858017 PhoneCallCmd 9537;
BA_ "CI_SigName" SG_ 2566858017 PhoneCallCmd "Phone Call Command";
BA_ "GenSigSendType" SG_ 2566858017 PhoneCallCmd 3;
BA_ "GenSigTimeoutTime_PCM" SG_ 2566858017 PhoneCallCmd 5000;
BA_ "SigType" SG_ 2566858017 PhoneCallCmd 4;
BA_ "CI_ParId" SG_ 2566858017 ReqInc_DecVol "IS316";
BA_ "CI_SigId" SG_ 2566858017 ReqInc_DecVol 9536;
BA_ "CI_SigName" SG_ 2566858017 ReqInc_DecVol "Request Increment/Decrement Volume";
BA_ "GenSigSendType" SG_ 2566858017 ReqInc_DecVol 3;
BA_ "GenSigTimeoutTime_PCM" SG_ 2566858017 ReqInc_DecVol 5000;
BA_ "SigType" SG_ 2566858017 ReqInc_DecVol 4;
BA_ "CI_ParId" SG_ 2566858058 AudioMute_FF254A "I289";
BA_ "CI_SigId" SG_ 2566858058 AudioMute_FF254A 9561;
BA_ "CI_SigName" SG_ 2566858058 AudioMute_FF254A "Audio Mute";
BA_ "GenSigSendType" SG_ 2566858058 AudioMute_FF254A 3;
BA_ "GenSigTimeoutTime_SGW" SG_ 2566858058 AudioMute_FF254A 5000;
BA_ "SigType" SG_ 2566858058 AudioMute_FF254A 4;
BA_ "CI_ParId" SG_ 2566858058 AudioVol "I305";
BA_ "CI_SigId" SG_ 2566858058 AudioVol 9559;
BA_ "CI_SigName" SG_ 2566858058 AudioVol "Audio Volume";
BA_ "GenSigSendType" SG_ 2566858058 AudioVol 3;
BA_ "GenSigTimeoutTime_SGW" SG_ 2566858058 AudioVol 5000;
BA_ "CI_ParId" SG_ 2566858058 ActvVideoSrc "I402";
BA_ "CI_SigId" SG_ 2566858058 ActvVideoSrc 9557;
BA_ "CI_SigName" SG_ 2566858058 ActvVideoSrc "Active Video Source";
BA_ "GenSigSendType" SG_ 2566858058 ActvVideoSrc 3;
BA_ "GenSigTimeoutTime_SGW" SG_ 2566858058 ActvVideoSrc 5000;
BA_ "CI_ParId" SG_ 2566858058 Track_RadioUp_Dw_FF254A "I295";
BA_ "CI_SigId" SG_ 2566858058 Track_RadioUp_Dw_FF254A 9556;
BA_ "CI_SigName" SG_ 2566858058 Track_RadioUp_Dw_FF254A "Track/Radio Up/Down";
BA_ "GenSigSendType" SG_ 2566858058 Track_RadioUp_Dw_FF254A 3;
BA_ "GenSigTimeoutTime_SGW" SG_ 2566858058 Track_RadioUp_Dw_FF254A 5000;
BA_ "SigType" SG_ 2566858058 Track_RadioUp_Dw_FF254A 4;
BA_ "CI_ParId" SG_ 2566858058 SrcUp_Dw_FF254A "I292";
BA_ "CI_SigId" SG_ 2566858058 SrcUp_Dw_FF254A 9554;
BA_ "CI_SigName" SG_ 2566858058 SrcUp_Dw_FF254A "Source Up/Down";
BA_ "GenSigSendType" SG_ 2566858058 SrcUp_Dw_FF254A 3;
BA_ "GenSigTimeoutTime_SGW" SG_ 2566858058 SrcUp_Dw_FF254A 5000;
BA_ "SigType" SG_ 2566858058 SrcUp_Dw_FF254A 4;
BA_ "CI_ParId" SG_ 2566858058 HtmlPageMode "I403";
BA_ "CI_SigId" SG_ 2566858058 HtmlPageMode 9553;
BA_ "CI_SigName" SG_ 2566858058 HtmlPageMode "HTML Page Mode";
BA_ "GenSigSendType" SG_ 2566858058 HtmlPageMode 3;
BA_ "GenSigTimeoutTime_SGW" SG_ 2566858058 HtmlPageMode 5000;
BA_ "SigType" SG_ 2566858058 HtmlPageMode 4;
BA_ "CI_ParId" SG_ 2566858058 ReqInc_DecVol_FF254A "IS316";
BA_ "CI_SigId" SG_ 2566858058 ReqInc_DecVol_FF254A 9550;
BA_ "CI_SigName" SG_ 2566858058 ReqInc_DecVol_FF254A "Request Increment/Decrement Volume";
BA_ "GenSigSendType" SG_ 2566858058 ReqInc_DecVol_FF254A 3;
BA_ "GenSigTimeoutTime_SGW" SG_ 2566858058 ReqInc_DecVol_FF254A 5000;
BA_ "SigType" SG_ 2566858058 ReqInc_DecVol_FF254A 4;
BA_ "CI_ParId" SG_ 2566858058 RadioOn_Off "IS317";
BA_ "CI_SigId" SG_ 2566858058 RadioOn_Off 44250;
BA_ "CI_SigName" SG_ 2566858058 RadioOn_Off "Radio On/Off";
BA_ "GenSigSendType" SG_ 2566858058 RadioOn_Off 3;
BA_ "GenSigTimeoutTime_SGW" SG_ 2566858058 RadioOn_Off 5000;
BA_ "SigType" SG_ 2566858058 RadioOn_Off 4;
BA_ "CI_ParId" SG_ 2566897729 TxtDis "I483";
BA_ "CI_SigId" SG_ 2566897729 TxtDis 42151;
BA_ "CI_SigName" SG_ 2566897729 TxtDis "Text Display";
BA_ "GenSigSendType" SG_ 2566897729 TxtDis 3;
BA_ "GenSigTimeoutTime_PCM" SG_ 2566897729 TxtDis 5000;
BA_ "SigType" SG_ 2566897729 TxtDis 8;
BA_ "CI_ParId" SG_ 2566897729 DevIx_FFC041 "I1001";
BA_ "CI_SigId" SG_ 2566897729 DevIx_FFC041 42150;
BA_ "CI_SigName" SG_ 2566897729 DevIx_FFC041 "Device Index";
BA_ "GenSigSendType" SG_ 2566897729 DevIx_FFC041 3;
BA_ "GenSigTimeoutTime_PCM" SG_ 2566897729 DevIx_FFC041 5000;
BA_ "SigType" SG_ 2566897729 DevIx_FFC041 4;
BA_ "CI_ParId" SG_ 2566857793 DevIx_FF2441 "I1001";
BA_ "CI_SigId" SG_ 2566857793 DevIx_FF2441 42033;
BA_ "CI_SigName" SG_ 2566857793 DevIx_FF2441 "Device Index";
BA_ "GenSigSendType" SG_ 2566857793 DevIx_FF2441 3;
BA_ "GenSigTimeoutTime_PCM" SG_ 2566857793 DevIx_FF2441 5000;
BA_ "SigType" SG_ 2566857793 DevIx_FF2441 4;
BA_ "CI_ParId" SG_ 2566857793 ActvVideoSrc_FF2441 "I402";
BA_ "CI_SigId" SG_ 2566857793 ActvVideoSrc_FF2441 9717;
BA_ "CI_SigName" SG_ 2566857793 ActvVideoSrc_FF2441 "Active Video Source";
BA_ "GenSigSendType" SG_ 2566857793 ActvVideoSrc_FF2441 3;
BA_ "GenSigTimeoutTime_PCM" SG_ 2566857793 ActvVideoSrc_FF2441 5000;
BA_ "CI_ParId" SG_ 2566857793 HtmlPageMode_FF2441 "I403";
BA_ "CI_SigId" SG_ 2566857793 HtmlPageMode_FF2441 9716;
BA_ "CI_SigName" SG_ 2566857793 HtmlPageMode_FF2441 "HTML Page Mode";
BA_ "GenSigSendType" SG_ 2566857793 HtmlPageMode_FF2441 3;
BA_ "GenSigTimeoutTime_PCM" SG_ 2566857793 HtmlPageMode_FF2441 5000;
BA_ "SigType" SG_ 2566857793 HtmlPageMode_FF2441 4;
BA_ "CI_ParId" SG_ 2566857793 AudioVol_FF2441 "I305";
BA_ "CI_SigId" SG_ 2566857793 AudioVol_FF2441 9715;
BA_ "CI_SigName" SG_ 2566857793 AudioVol_FF2441 "Audio Volume";
BA_ "GenSigSendType" SG_ 2566857793 AudioVol_FF2441 3;
BA_ "GenSigTimeoutTime_PCM" SG_ 2566857793 AudioVol_FF2441 5000;
BA_ "CI_ParId" SG_ 2566857793 AudioMute_FF2441 "I289";
BA_ "CI_SigId" SG_ 2566857793 AudioMute_FF2441 9714;
BA_ "CI_SigName" SG_ 2566857793 AudioMute_FF2441 "Audio Mute";
BA_ "GenSigSendType" SG_ 2566857793 AudioMute_FF2441 3;
BA_ "GenSigTimeoutTime_PCM" SG_ 2566857793 AudioMute_FF2441 5000;
BA_ "SigType" SG_ 2566857793 AudioMute_FF2441 4;
BA_ "CI_ParId" SG_ 2566857793 ActvSrcEx "I284";
BA_ "CI_SigId" SG_ 2566857793 ActvSrcEx 9713;
BA_ "CI_SigName" SG_ 2566857793 ActvSrcEx "Active Source (Extended)";
BA_ "GenSigSendType" SG_ 2566857793 ActvSrcEx 3;
BA_ "GenSigTimeoutTime_PCM" SG_ 2566857793 ActvSrcEx 5000;
BA_ "CI_ParId" SG_ 2566857793 RadioDotDis "IS335";
BA_ "CI_SigId" SG_ 2566857793 RadioDotDis 9710;
BA_ "CI_SigName" SG_ 2566857793 RadioDotDis "Radio Dot Display ";
BA_ "GenSigSendType" SG_ 2566857793 RadioDotDis 3;
BA_ "GenSigTimeoutTime_PCM" SG_ 2566857793 RadioDotDis 5000;
BA_ "CI_ParId" SG_ 2566857793 RadioColonDis "IS336";
BA_ "CI_SigId" SG_ 2566857793 RadioColonDis 9709;
BA_ "CI_SigName" SG_ 2566857793 RadioColonDis "Radio Colon Display";
BA_ "GenSigSendType" SG_ 2566857793 RadioColonDis 3;
BA_ "GenSigTimeoutTime_PCM" SG_ 2566857793 RadioColonDis 5000;
BA_ "CI_ParId" SG_ 2566857793 PhoneCallIn_Out "I288";
BA_ "CI_SigId" SG_ 2566857793 PhoneCallIn_Out 9708;
BA_ "CI_SigName" SG_ 2566857793 PhoneCallIn_Out "Phone Call Incoming/Outcoming";
BA_ "GenSigSendType" SG_ 2566857793 PhoneCallIn_Out 3;
BA_ "GenSigTimeoutTime_PCM" SG_ 2566857793 PhoneCallIn_Out 5000;
BA_ "SigType" SG_ 2566857793 PhoneCallIn_Out 4;
BA_ "CI_ParId" SG_ 2566857793 PhoneCallHeld "I287";
BA_ "CI_SigId" SG_ 2566857793 PhoneCallHeld 9707;
BA_ "CI_SigName" SG_ 2566857793 PhoneCallHeld "Phone Call Held";
BA_ "GenSigSendType" SG_ 2566857793 PhoneCallHeld 3;
BA_ "GenSigTimeoutTime_PCM" SG_ 2566857793 PhoneCallHeld 5000;
BA_ "SigType" SG_ 2566857793 PhoneCallHeld 4;
BA_ "CI_ParId" SG_ 2566857793 PhoneCallActv "I286";
BA_ "CI_SigId" SG_ 2566857793 PhoneCallActv 9706;
BA_ "CI_SigName" SG_ 2566857793 PhoneCallActv "Phone Call Active";
BA_ "GenSigSendType" SG_ 2566857793 PhoneCallActv 3;
BA_ "GenSigTimeoutTime_PCM" SG_ 2566857793 PhoneCallActv 5000;
BA_ "SigType" SG_ 2566857793 PhoneCallActv 4;
BA_ "CI_ParId" SG_ 2566857793 Mix "IS330";
BA_ "CI_SigId" SG_ 2566857793 Mix 9705;
BA_ "CI_SigName" SG_ 2566857793 Mix "MIX (in CD Mix Mode)";
BA_ "GenSigSendType" SG_ 2566857793 Mix 3;
BA_ "GenSigTimeoutTime_PCM" SG_ 2566857793 Mix 5000;
BA_ "CI_ParId" SG_ 2566857793 Rpt "IS331";
BA_ "CI_SigId" SG_ 2566857793 Rpt 9704;
BA_ "CI_SigName" SG_ 2566857793 Rpt "RPT (in CD Repeat Mode)";
BA_ "GenSigSendType" SG_ 2566857793 Rpt 3;
BA_ "GenSigTimeoutTime_PCM" SG_ 2566857793 Rpt 5000;
BA_ "CI_ParId" SG_ 2566857793 UnitSysSet_FF2441 "I1078";
BA_ "CI_SigId" SG_ 2566857793 UnitSysSet_FF2441 44744;
BA_ "CI_SigName" SG_ 2566857793 UnitSysSet_FF2441 "Unit System Setting";
BA_ "GenSigSendType" SG_ 2566857793 UnitSysSet_FF2441 3;
BA_ "GenSigTimeoutTime_PCM" SG_ 2566857793 UnitSysSet_FF2441 5000;
BA_ "SigType" SG_ 2566857793 UnitSysSet_FF2441 4;
BA_ "CI_ParId" SG_ 2566857793 CdSym "IS333";
BA_ "CI_SigId" SG_ 2566857793 CdSym 9701;
BA_ "CI_SigName" SG_ 2566857793 CdSym "CD Symbol (CD Active)";
BA_ "GenSigSendType" SG_ 2566857793 CdSym 3;
BA_ "GenSigTimeoutTime_PCM" SG_ 2566857793 CdSym 5000;
BA_ "CI_ParId" SG_ 2566857793 MsgSts "I285";
BA_ "CI_SigId" SG_ 2566857793 MsgSts 9699;
BA_ "CI_SigName" SG_ 2566857793 MsgSts "Message Status";
BA_ "GenSigSendType" SG_ 2566857793 MsgSts 3;
BA_ "GenSigTimeoutTime_PCM" SG_ 2566857793 MsgSts 5000;
BA_ "SigType" SG_ 2566857793 MsgSts 4;
BA_ "CI_ParId" SG_ 2566857793 AudioPause "I1002";
BA_ "CI_SigId" SG_ 2566857793 AudioPause 42188;
BA_ "CI_SigName" SG_ 2566857793 AudioPause "Audio Pause";
BA_ "GenSigSendType" SG_ 2566857793 AudioPause 3;
BA_ "GenSigTimeoutTime_PCM" SG_ 2566857793 AudioPause 5000;
BA_ "SigType" SG_ 2566857793 AudioPause 4;
BA_ "CI_ParId" SG_ 2566857793 ManSymLoudnessOn "IS326";
BA_ "CI_SigId" SG_ 2566857793 ManSymLoudnessOn 9697;
BA_ "CI_SigName" SG_ 2566857793 ManSymLoudnessOn "Man Symbol (Manual) Loudness On";
BA_ "GenSigSendType" SG_ 2566857793 ManSymLoudnessOn 3;
BA_ "GenSigTimeoutTime_PCM" SG_ 2566857793 ManSymLoudnessOn 5000;
BA_ "CI_ParId" SG_ 2566857793 LoSym "IS327";
BA_ "CI_SigId" SG_ 2566857793 LoSym 9696;
BA_ "CI_SigName" SG_ 2566857793 LoSym "Lo Symbol (Local)";
BA_ "GenSigSendType" SG_ 2566857793 LoSym 3;
BA_ "GenSigTimeoutTime_PCM" SG_ 2566857793 LoSym 5000;
BA_ "CI_ParId" SG_ 2566857793 AfSym "IS328";
BA_ "CI_SigId" SG_ 2566857793 AfSym 9695;
BA_ "CI_SigName" SG_ 2566857793 AfSym "AF Symbol (Alternate Frequency)";
BA_ "GenSigSendType" SG_ 2566857793 AfSym 3;
BA_ "GenSigTimeoutTime_PCM" SG_ 2566857793 AfSym 5000;
BA_ "CI_ParId" SG_ 2566857793 TaSym "IS329";
BA_ "CI_SigId" SG_ 2566857793 TaSym 9694;
BA_ "CI_SigName" SG_ 2566857793 TaSym "TA Symbol (Trafic Announcement)";
BA_ "GenSigSendType" SG_ 2566857793 TaSym 3;
BA_ "GenSigTimeoutTime_PCM" SG_ 2566857793 TaSym 5000;
BA_ "CI_ParId" SG_ 2566857793 DevMic "I1003";
BA_ "CI_SigId" SG_ 2566857793 DevMic 42189;
BA_ "CI_SigName" SG_ 2566857793 DevMic "Device Microphone";
BA_ "GenSigSendType" SG_ 2566857793 DevMic 3;
BA_ "GenSigTimeoutTime_PCM" SG_ 2566857793 DevMic 5000;
BA_ "SigType" SG_ 2566857793 DevMic 4;
BA_ "CI_ParId" SG_ 2566857793 InfotainmentSysSts "I1079";
BA_ "CI_SigId" SG_ 2566857793 InfotainmentSysSts 45117;
BA_ "CI_SigName" SG_ 2566857793 InfotainmentSysSts "Infotainment System Status";
BA_ "GenSigSendType" SG_ 2566857793 InfotainmentSysSts 3;
BA_ "GenSigTimeoutTime_PCM" SG_ 2566857793 InfotainmentSysSts 5000;
BA_ "CI_ParId" SG_ 2566857793 FmISym "IS324";
BA_ "CI_SigId" SG_ 2566857793 FmISym 9689;
BA_ "CI_SigName" SG_ 2566857793 FmISym "FM-I Symbol";
BA_ "GenSigSendType" SG_ 2566857793 FmISym 3;
BA_ "GenSigTimeoutTime_PCM" SG_ 2566857793 FmISym 5000;
BA_ "CI_ParId" SG_ 2583662631 ChgSts "ID1546";
BA_ "CI_SigId" SG_ 2583662631 ChgSts 35811;
BA_ "CI_SigName" SG_ 2583662631 ChgSts "Charging Status ";
BA_ "GenSigTimeoutTime_PCM" SG_ 2583662631 ChgSts 5000;
BA_ "CI_ParId" SG_ 2583662631 SchedChgAuth "ID1513";
BA_ "CI_SigId" SG_ 2583662631 SchedChgAuth 35255;
BA_ "CI_SigName" SG_ 2583662631 SchedChgAuth "Scheduled Charging Authorization";
BA_ "GenSigTimeoutTime_PCM" SG_ 2583662631 SchedChgAuth 5000;
BA_ "CI_ParId" SG_ 2583662631 ChgModeSel "ID1512";
BA_ "CI_SigId" SG_ 2583662631 ChgModeSel 35254;
BA_ "CI_SigName" SG_ 2583662631 ChgModeSel "Charging Mode Selected";
BA_ "GenSigTimeoutTime_PCM" SG_ 2583662631 ChgModeSel 5000;
BA_ "CI_ParId" SG_ 2583662666 SchedChgAuth_FF904A "ID1513";
BA_ "CI_SigId" SG_ 2583662666 SchedChgAuth_FF904A 35258;
BA_ "CI_SigName" SG_ 2583662666 SchedChgAuth_FF904A "Scheduled Charging Authorization";
BA_ "CI_ParId" SG_ 2583666250 ExtChgCurLineLim "ID2138";
BA_ "CI_SigId" SG_ 2583666250 ExtChgCurLineLim 41810;
BA_ "CI_SigName" SG_ 2583666250 ExtChgCurLineLim "External Charging Current Line Limit";
BA_ "GenSigTimeoutTime_SGW" SG_ 2583666250 ExtChgCurLineLim 5000;
BA_ "SigType" SG_ 2583666250 ExtChgCurLineLim 1;
BA_ "CI_ParId" SG_ 2566910497 DeratingReq "ID2273";
BA_ "CI_SigId" SG_ 2566910497 DeratingReq 42627;
BA_ "CI_SigName" SG_ 2566910497 DeratingReq "Derating Request";
BA_ "GenSigTimeoutTime_PCM" SG_ 2566910497 DeratingReq 25000;
BA_ "SigType" SG_ 2566910497 DeratingReq 4;
BA_ "CI_ParId" SG_ 2650776966 NegRelayCounterAbove500 "F375";
BA_ "CI_SigId" SG_ 2650776966 NegRelayCounterAbove500 45691;
BA_ "CI_SigName" SG_ 2650776966 NegRelayCounterAbove500 "NegRelayCounterAbove500";
BA_ "GenSigTimeoutTime_PCM" SG_ 2650776966 NegRelayCounterAbove500 3000000;
BA_ "CI_ParId" SG_ 2650776966 PosRelayCounterAbove500 "F374";
BA_ "CI_SigId" SG_ 2650776966 PosRelayCounterAbove500 45690;
BA_ "CI_SigName" SG_ 2650776966 PosRelayCounterAbove500 "PosRelayCounterAbove500";
BA_ "GenSigTimeoutTime_PCM" SG_ 2650776966 PosRelayCounterAbove500 3000000;
BA_ "CI_ParId" SG_ 2650776966 NegRelayCounter400_500 "F373";
BA_ "CI_SigId" SG_ 2650776966 NegRelayCounter400_500 45689;
BA_ "CI_SigName" SG_ 2650776966 NegRelayCounter400_500 "NegRelayCounter400_500";
BA_ "GenSigTimeoutTime_PCM" SG_ 2650776966 NegRelayCounter400_500 3000000;
BA_ "CI_ParId" SG_ 2650776966 PosRelayCounter400_500 "F372";
BA_ "CI_SigId" SG_ 2650776966 PosRelayCounter400_500 45688;
BA_ "CI_SigName" SG_ 2650776966 PosRelayCounter400_500 "PosRelayCounter400_500";
BA_ "GenSigTimeoutTime_PCM" SG_ 2650776966 PosRelayCounter400_500 3000000;
BA_ "CI_ParId" SG_ 2650776966 NegRelayCounter250_400 "F371";
BA_ "CI_SigId" SG_ 2650776966 NegRelayCounter250_400 45473;
BA_ "CI_SigName" SG_ 2650776966 NegRelayCounter250_400 "NegRelayCounter250_400";
BA_ "GenSigTimeoutTime_PCM" SG_ 2650776966 NegRelayCounter250_400 3000000;
BA_ "CI_ParId" SG_ 2650776966 PosRelayCounter250_400 "F370";
BA_ "CI_SigId" SG_ 2650776966 PosRelayCounter250_400 45472;
BA_ "CI_SigName" SG_ 2650776966 PosRelayCounter250_400 "PosRelayCounter250_400";
BA_ "GenSigTimeoutTime_PCM" SG_ 2650776966 PosRelayCounter250_400 3000000;
BA_ "CI_ParId" SG_ 2650776966 NegRelayCounter50_250 "F369";
BA_ "CI_SigId" SG_ 2650776966 NegRelayCounter50_250 45471;
BA_ "CI_SigName" SG_ 2650776966 NegRelayCounter50_250 "NegRelayCounter50_250";
BA_ "GenSigTimeoutTime_PCM" SG_ 2650776966 NegRelayCounter50_250 3000000;
BA_ "CI_ParId" SG_ 2650776966 PosRelayCounter50_250 "F368";
BA_ "CI_SigId" SG_ 2650776966 PosRelayCounter50_250 45470;
BA_ "CI_SigName" SG_ 2650776966 PosRelayCounter50_250 "PosRelayCounter50_250";
BA_ "GenSigTimeoutTime_PCM" SG_ 2650776966 PosRelayCounter50_250 3000000;
BA_ "CI_ParId" SG_ 2650776966 NegRelayCounter "F367";
BA_ "CI_SigId" SG_ 2650776966 NegRelayCounter 45469;
BA_ "CI_SigName" SG_ 2650776966 NegRelayCounter "NegRelayCounter";
BA_ "GenSigTimeoutTime_PCM" SG_ 2650776966 NegRelayCounter 3000000;
BA_ "CI_ParId" SG_ 2650776966 PosRelayCounter "F366";
BA_ "CI_SigId" SG_ 2650776966 PosRelayCounter 45468;
BA_ "CI_SigName" SG_ 2650776966 PosRelayCounter "PosRelayCounter";
BA_ "GenSigTimeoutTime_PCM" SG_ 2650776966 PosRelayCounter 3000000;
BA_ "CI_ParId" SG_ 2650776966 PreRelayCounter "F365";
BA_ "CI_SigId" SG_ 2650776966 PreRelayCounter 45467;
BA_ "CI_SigName" SG_ 2650776966 PreRelayCounter "PreRelayCounter";
BA_ "GenSigTimeoutTime_PCM" SG_ 2650776966 PreRelayCounter 3000000;
VAL_ 2583663895 BSGTrqHighLowMode 0 "Full BSG Neg torque allowed" 1 "Reduced BSG Neg torque allowed" 2 "Error" 3 "Not available" ;
VAL_ 2583663895 BuzVolWarn 0 "Level 0 (min volume)" 1 "Level 1" 2 "Level 2" 3 "Level 3" 4 "Level 4" 5 "Level 5" 6 "Level 6" 7 "Level 7 (max volume)" ;
VAL_ 2583663895 BuzVolBtn 0 "Level 0 (min volume)" 1 "Level 1" 2 "Level 2" 3 "Level 3" 4 "Level 4" 5 "Level 5" 6 "Level 6" 7 "Level 7 (max volume)" ;
VAL_ 2583663895 WelcomeLightCfg 0 "Disable" 1 "Enable" 2 "Error" 3 "Not Available" ;
VAL_ 2583663895 PwrModeSts_FF9517 0 "Standard power" 1 "Logistic Mode On" 2 "Logistic Mode PR" 3 "LogisticModeOn + EngineOn" ;
VAL_ 2583663895 SeatBeltRemindEna 0 "Not Enabled" 1 "Enabled" 2 "Error" 3 "Not Available" ;
VAL_ 2583663895 DrivRespOnPtoMissIntrp 0 "Terminate PTO mission" 1 "Continue PTO mission" 3 "Response pending" ;
VAL_ 2583663895 AirbagLampFail 0 "Off, No fault present" 1 "Off, fault present" 2 "On, fault not present" 3 "Blinking, fault not present" ;
VAL_ 2583663895 AbsLampFail 0 "Off, No fault present" 1 "Off, Fault present" 2 "On, No fault present" 3 "Not Available" ;
VAL_ 2583663895 EbdLampFail 0 "Off, No fault present" 1 "Off, Fault present" 2 "On, No fault present" 3 "Not Available" ;
VAL_ 2583663895 VdcLampFail 0 "Off, No fault present" 1 "Off, Fault present" 2 "On, No fault present" 3 "Not Available" ;
VAL_ 2566904343 EcoMode_FFDA17 0 "Off" 1 "On (Eco Mode)" 2 "Power Mode" 3 "Not Available / No Action" ;
VAL_ 2566904345 EcoMode_FFDA19 0 "Off" 1 "On (Eco Mode)" 2 "Power Mode" 3 "Not Available / No Action" ;
VAL_ 2566904345 ClimaCtrlVentilMode_FFDA19 0 "Low" 1 "Medium" 2 "High" 3 "Not Available" ;
VAL_ 2566904345 AcReqDistrFt 0 "Open" 1 "Closed" 2 "Error Indicator" 3 "Not Available" ;
VAL_ 2566904345 AcReqDistrCentre 0 "Open" 1 "Closed" 2 "Error Indicator" 3 "Not Available" ;
VAL_ 2566904345 AcReqDistrTop 0 "Open" 1 "Closed" 2 "Error Indicator" 3 "Not Available" ;
VAL_ 2566904345 AcReqDistrWindsh 0 "Open" 1 "Closed" 2 "Error Indicator" 3 "Not Available" ;
VAL_ 2566904345 AcComprDis 0 "Off by Driver's Request" 1 "Off by Energy Saving" 2 "Off by Safety" 3 "No Action /No Disable" ;
VAL_ 2566904345 AcDurMode 0 "Short" 1 "Mid" 2 "Long" 3 "Don�t care/take no action" ;
VAL_ 2566904345 AcReqRecircMode 0 "Manual, fresh air" 1 "Automatic" 2 "Manual, recirculation" 3 "Closed by AQS" 4 "Reserved" 5 "Reserved" 6 "Reserved" 7 "Reserved" 8 "Reserved" 9 "Reserved" 10 "Reserved" 11 "Reserved" 12 "Reserved" 13 "Reserved" 14 "Reserved" 15 "Don�t care/take no action" ;
VAL_ 2566904345 AcCompr 0 "Off" 1 "On" 2 "Error Indicator" 3 "Not Available / No Action" ;
VAL_ 2566904345 AcMaxDefrost 0 "Off" 1 "On" 3 "No Action / Not Available" ;
VAL_ 2566904345 AcCtrlMode 0 "CLC Off" 1 "Full automatic" 2 "Semi automatic" 3 "Manual" 4 "IC Heating Request" 5 "BM Heating Request" 6 "Immediate Heating Request" 7 "IC Park Cooling Request" 8 "BM Park Cooling Request" 9 "Immediate Park Cooling Request" 10 "Reserved" 11 "Reserved" 12 "Reserved" 13 "Reserved" 14 "Reserved" 15 "Don�t care/take no action" ;
VAL_ 2566904353 EcoMode_FFDA21 0 "Off" 1 "On (Eco Mode)" 2 "Power Mode" 3 "Not Available / No Action" ;
VAL_ 2566904353 ClimaCtrlVentilMode_FFDA21 0 "Low" 1 "Medium" 2 "High" 3 "Not Available" ;
VAL_ 2566904353 AcBlowSpeedInc_Dec 0 "Decrement" 1 "Increment" 2 "Reserved" 3 "Not available/No Action" ;
VAL_ 2566904353 AcTempInc_Dec 0 "Decrement" 1 "Increment" 2 "Reserved" 3 "Not available/No Action" ;
VAL_ 2566904353 AcReqDistrFt_FFDA21 0 "Open" 1 "Closed" 2 "Error Indicator" 3 "Not Available" ;
VAL_ 2566904353 AcReqDistrCentre_FFDA21 0 "Open" 1 "Closed" 2 "Error Indicator" 3 "Not Available" ;
VAL_ 2566904353 AcReqDistrTop_FFDA21 0 "Open" 1 "Closed" 2 "Error Indicator" 3 "Not Available" ;
VAL_ 2566904353 AcReqDistrWindsh_FFDA21 0 "Open" 1 "Closed" 2 "Error Indicator" 3 "Not Available" ;
VAL_ 2566904353 AcDurMode_FFDA21 0 "Short" 1 "Mid" 2 "Long" 3 "Don�t care/take no action" ;
VAL_ 2566904353 AcReqRecircMode_FFDA21 0 "Manual, fresh air" 1 "Automatic" 2 "Manual, recirculation" 3 "Closed by AQS" 4 "Reserved" 5 "Reserved" 6 "Reserved" 7 "Reserved" 8 "Reserved" 9 "Reserved" 10 "Reserved" 11 "Reserved" 12 "Reserved" 13 "Reserved" 14 "Reserved" 15 "Don�t care/take no action" ;
VAL_ 2566904353 AcCompr_FFDA21 0 "Off" 1 "On" 2 "Error Indicator" 3 "Not Available / No Action" ;
VAL_ 2566904353 AcMaxDefrost_FFDA21 0 "Off" 1 "On" 3 "No Action / Not Available" ;
VAL_ 2566904353 AcCtrlMode_FFDA21 0 "CLC Off" 1 "Full automatic" 2 "Semi automatic" 3 "Manual" 4 "IC Heating Request" 5 "BM Heating Request" 6 "Immediate Heating Request" 7 "IC Park Cooling Request" 8 "BM Park Cooling Request" 9 "Immediate Park Cooling Request" 10 "Reserved" 11 "Reserved" 12 "Reserved" 13 "Reserved" 14 "Reserved" 15 "Don�t care/take no action" ;
VAL_ 2566904394 EcoMode_FFDA4A 0 "Off" 1 "On (Eco Mode)" 2 "Power Mode" 3 "Not Available / No Action" ;
VAL_ 2566904394 AcBlowSpeedInc_Dec_FFDA4A 0 "Decrement" 1 "Increment" 2 "Reserved" 3 "Not available/No Action" ;
VAL_ 2566904394 AcTempInc_Dec_FFDA4A 0 "Decrement" 1 "Increment" 2 "Reserved" 3 "Not available/No Action" ;
VAL_ 2566904394 AcReqDistrFt_FFDA4A 0 "Open" 1 "Closed" 2 "Error Indicator" 3 "Not Available" ;
VAL_ 2566904394 AcReqDistrCentre_FFDA4A 0 "Open" 1 "Closed" 2 "Error Indicator" 3 "Not Available" ;
VAL_ 2566904394 AcReqDistrTop_FFDA4A 0 "Open" 1 "Closed" 2 "Error Indicator" 3 "Not Available" ;
VAL_ 2566904394 AcReqRecircMode_FFDA4A 0 "Manual, fresh air" 1 "Automatic" 2 "Manual, recirculation" 3 "Closed by AQS" 4 "Reserved" 5 "Reserved" 6 "Reserved" 7 "Reserved" 8 "Reserved" 9 "Reserved" 10 "Reserved" 11 "Reserved" 12 "Reserved" 13 "Reserved" 14 "Reserved" 15 "Don�t care/take no action" ;
VAL_ 2566904394 AcMaxDefrost_FFDA4A 0 "Off" 1 "On" 3 "No Action / Not Available" ;
VAL_ 2566904394 AcCtrlMode_FFDA4A 0 "CLC Off" 1 "Full automatic" 2 "Semi automatic" 3 "Manual" 4 "IC Heating Request" 5 "BM Heating Request" 6 "Immediate Heating Request" 7 "IC Park Cooling Request" 8 "BM Park Cooling Request" 9 "Immediate Park Cooling Request" 10 "Reserved" 11 "Reserved" 12 "Reserved" 13 "Reserved" 14 "Reserved" 15 "Don�t care/take no action" ;
VAL_ 2382311251 MsgCnt_F2F53 8 "Reserved1" 9 "Reserved2" 10 "Reserved3" 11 "Reserved4" 12 "Reserved5" 13 "Reserved6" 14 "Reserved7" 15 "Not Available, request honored" ;
VAL_ 2382311251 SdmSevFault 0 "False" 1 "True" 2 "Error" 3 "Not Available" ;
VAL_ 2382311251 SdmWarnFault 0 "False" 1 "True" 2 "Error" 3 "Not Available" ;
VAL_ 2382311251 CrashSts 0 "Not Active" 1 "Active" 2 "Error" 3 "Not available" ;
VAL_ 2382311463 MsgCnt_F3027 8 "Reserved1" 9 "Reserved2" 10 "Reserved3" 11 "Reserved4" 12 "Reserved5" 13 "Reserved6" 14 "Reserved7" 15 "Not Available, request honored" ;
VAL_ 2382311463 HighVCutOffSts 0 "Not Active" 1 "Active" 2 "Error" 3 "Not available" ;
VAL_ 2583627910 PackDcirSts 0 "DCIR value in Range" 1 "DCIR out of Range" 2 "Error" 3 "Not Available" ;
VAL_ 2583627910 ThermEvtCause 0 "None/No event Detected" 1 "Pressure" 2 "Temperature" 4 "Humidity" 8 "Multigas" 16 "Voltage" ;
VAL_ 2583627910 OpSts 0 "Initialization in process" 1 "Initialization Complete" 2 "Operational" 3 "Normal Pwr-Down in Process" 4 "Emergency Pwr-Down In Process" 5 "Disabled by external command" 6 "Disabled by internal decision" 7 "Not Operational" 8 "Reserved" 9 "Reserved" 10 "Reserved" 11 "Reserved" 12 "Reserved" 13 "Reserved" 14 "Error" 15 "Not Available" ;
VAL_ 2583627910 SocSts 0 "Level is acceptable" 1 "Approaching lower limit" 2 "Lower limit" 3 "Below lower limit" 4 "Approaching upper limit" 5 "Upper limit" 6 "Above upper limit" 7 "Reserved" 8 "Reserved" 9 "Reserved" 10 "Reserved" 11 "Reserved" 12 "Reserved" 13 "Reserved" 14 "Error" 15 "Not Available" ;
VAL_ 2583627910 PackFuseDiag 0 "No Fuse Blown" 1 "Fuse Blown" 2 "Error" 3 "Not Available" ;
VAL_ 2583627911 PackDcirSts_FF0887 0 "DCIR value in Range" 1 "DCIR out of Range" 2 "Error" 3 "Not Available" ;
VAL_ 2583627911 ThermEvtCause_FF0887 0 "None/No event Detected" 1 "Pressure" 2 "Temperature" 4 "Humidity" 8 "Multigas" 16 "Voltage" ;
VAL_ 2583627911 OpSts_FF0887 0 "Initialization in process" 1 "Initialization Complete" 2 "Operational" 3 "Normal Pwr-Down in Process" 4 "Emergency Pwr-Down In Process" 5 "Disabled by external command" 6 "Disabled by internal decision" 7 "Not Operational" 8 "Reserved" 9 "Reserved" 10 "Reserved" 11 "Reserved" 12 "Reserved" 13 "Reserved" 14 "Error" 15 "Not Available" ;
VAL_ 2583627911 SocSts_FF0887 0 "Level is acceptable" 1 "Approaching lower limit" 2 "Lower limit" 3 "Below lower limit" 4 "Approaching upper limit" 5 "Upper limit" 6 "Above upper limit" 7 "Reserved" 8 "Reserved" 9 "Reserved" 10 "Reserved" 11 "Reserved" 12 "Reserved" 13 "Reserved" 14 "Error" 15 "Not Available" ;
VAL_ 2583627911 PackFuseDiag_FF0887 0 "No Fuse Blown" 1 "Fuse Blown" 2 "Error" 3 "Not Available" ;
VAL_ 2583628019 OpSts_FF08F3 0 "Initialization in process" 1 "Initialization Complete" 2 "Operational" 3 "Normal Pwr-Down in Process" 4 "Emergency Pwr-Down In Process" 5 "Disabled by external command" 6 "Disabled by internal decision" 7 "Not Operational" 8 "Reserved" 9 "Reserved" 10 "Reserved" 11 "Reserved" 12 "Reserved" 13 "Reserved" 14 "Error" 15 "Not Available" ;
VAL_ 2583628019 ThermEvtDet 0 "No Event Detected" 1 "Event Detected" 2 "Error" 3 "Not Available" ;
VAL_ 2583628020 PackDcirSts_FF08F4 0 "DCIR value in Range" 1 "DCIR out of Range" 2 "Error" 3 "Not Available" ;
VAL_ 2583628020 ThermEvtCause_FF08F4 0 "None/No event Detected" 1 "Pressure" 2 "Temperature" 4 "Humidity" 8 "Multigas" 16 "Voltage" ;
VAL_ 2583628020 OpSts_FF08F4 0 "Initialization in process" 1 "Initialization Complete" 2 "Operational" 3 "Normal Pwr-Down in Process" 4 "Emergency Pwr-Down In Process" 5 "Disabled by external command" 6 "Disabled by internal decision" 7 "Not Operational" 8 "Reserved" 9 "Reserved" 10 "Reserved" 11 "Reserved" 12 "Reserved" 13 "Reserved" 14 "Error" 15 "Not Available" ;
VAL_ 2583628020 SocSts_FF08F4 0 "Level is acceptable" 1 "Approaching lower limit" 2 "Lower limit" 3 "Below lower limit" 4 "Approaching upper limit" 5 "Upper limit" 6 "Above upper limit" 7 "Reserved" 8 "Reserved" 9 "Reserved" 10 "Reserved" 11 "Reserved" 12 "Reserved" 13 "Reserved" 14 "Error" 15 "Not Available" ;
VAL_ 2583628020 PackFuseDiag_FF08F4 0 "No Fuse Blown" 1 "Fuse Blown" 2 "Error" 3 "Not Available" ;
VAL_ 2583628021 PackDcirSts_FF08F5 0 "DCIR value in Range" 1 "DCIR out of Range" 2 "Error" 3 "Not Available" ;
VAL_ 2583628021 ThermEvtCause_FF08F5 0 "None/No event Detected" 1 "Pressure" 2 "Temperature" 4 "Humidity" 8 "Multigas" 16 "Voltage" ;
VAL_ 2583628021 OpSts_FF08F5 0 "Initialization in process" 1 "Initialization Complete" 2 "Operational" 3 "Normal Pwr-Down in Process" 4 "Emergency Pwr-Down In Process" 5 "Disabled by external command" 6 "Disabled by internal decision" 7 "Not Operational" 8 "Reserved" 9 "Reserved" 10 "Reserved" 11 "Reserved" 12 "Reserved" 13 "Reserved" 14 "Error" 15 "Not Available" ;
VAL_ 2583628021 SocSts_FF08F5 0 "Level is acceptable" 1 "Approaching lower limit" 2 "Lower limit" 3 "Below lower limit" 4 "Approaching upper limit" 5 "Upper limit" 6 "Above upper limit" 7 "Reserved" 8 "Reserved" 9 "Reserved" 10 "Reserved" 11 "Reserved" 12 "Reserved" 13 "Reserved" 14 "Error" 15 "Not Available" ;
VAL_ 2583628021 PackFuseDiag_FF08F5 0 "No Fuse Blown" 1 "Fuse Blown" 2 "Error" 3 "Not Available" ;
VAL_ 2583628022 PackDcirSts_FF08F6 0 "DCIR value in Range" 1 "DCIR out of Range" 2 "Error" 3 "Not Available" ;
VAL_ 2583628022 ThermEvtCause_FF08F6 0 "None/No event Detected" 1 "Pressure" 2 "Temperature" 4 "Humidity" 8 "Multigas" 16 "Voltage" ;
VAL_ 2583628022 OpSts_FF08F6 0 "Initialization in process" 1 "Initialization Complete" 2 "Operational" 3 "Normal Pwr-Down in Process" 4 "Emergency Pwr-Down In Process" 5 "Disabled by external command" 6 "Disabled by internal decision" 7 "Not Operational" 8 "Reserved" 9 "Reserved" 10 "Reserved" 11 "Reserved" 12 "Reserved" 13 "Reserved" 14 "Error" 15 "Not Available" ;
VAL_ 2583628022 SocSts_FF08F6 0 "Level is acceptable" 1 "Approaching lower limit" 2 "Lower limit" 3 "Below lower limit" 4 "Approaching upper limit" 5 "Upper limit" 6 "Above upper limit" 7 "Reserved" 8 "Reserved" 9 "Reserved" 10 "Reserved" 11 "Reserved" 12 "Reserved" 13 "Reserved" 14 "Error" 15 "Not Available" ;
VAL_ 2583628022 PackFuseDiag_FF08F6 0 "No Fuse Blown" 1 "Fuse Blown" 2 "Error" 3 "Not Available" ;
VAL_ 2634014026 TxtCharSet 0 "Latin1 Western Europe" 1 "Latin2 CentralEurope" 2 "Latin3 South Europe" 3 "Latin4 North Europe" 4 "Latin/Cyrillic" 5 "Latin/Arab" 6 "Latin/Greek" 7 "Latin/Hebrew" 8 "Latin5/Turkish" 9 "Latin6/Northern" 10 "Latin/Thai" 11 "Latin/Devanagari" 12 "Latin7 Baltic" 13 "Latin8 Celtic" 14 "Latin9" 15 "Latin10 Southeast Europe" ;
VAL_ 2634014026 PopupIx_FFDD4A 0 "Default Popup" 4095 "No Action, No Popup" ;
VAL_ 2634014066 TxtCharSet_FFDD72 0 "Latin1 Western Europe" 1 "Latin2 CentralEurope" 2 "Latin3 South Europe" 3 "Latin4 North Europe" 4 "Latin/Cyrillic" 5 "Latin/Arab" 6 "Latin/Greek" 7 "Latin/Hebrew" 8 "Latin5/Turkish" 9 "Latin6/Northern" 10 "Latin/Thai" 11 "Latin/Devanagari" 12 "Latin7 Baltic" 13 "Latin8 Celtic" 14 "Latin9" 15 "Latin10 Southeast Europe" ;
VAL_ 2634014066 PopupIx_FFDD72 0 "Default Popup" 4095 "No Action, No Popup" ;
VAL_ 2566904855 BuzLevEx_FFDC17 0 "Level 0" 1 "Level 1" 2 "Level 2" 3 "Level 3" 4 "Level 4" 5 "Level 5" 6 "Level 6" 7 "Level 7" 8 "Level 8" 9 "Level 9" 10 "Level 10" 11 "Level 11" 12 "Level 12" 13 "Level 13" 14 "Level 14" 15 "Not Available, Default Level" ;
VAL_ 2566904855 BuzToneEx_FFDC17 0 "Off" 1 "Preset Tone 1" 2 "Preset Tone 2" 3 "Preset Tone 3" 4 "Preset Tone 4" 5 "Preset Tone 5" 6 "Preset Tone 6" 7 "Preset Tone 7" 8 "Preset Tone 8" 9 "Preset Tone 9" 10 "Preset Tone 10" 11 "Preset Tone 11" 12 "Preset Tone 12" 13 "Preset Tone 13" 14 "Preset Tone 14" 15 "No Available, Default Tone" ;
VAL_ 2566904855 PopupAckSts 0 "No acknowledge given" 1 "Positive acknowledge received" 2 "Negative acknowledge received" 3 "Not Available" ;
VAL_ 2566904855 PopupActvSts 0 "Disabled/off" 1 "In foreground" 2 "In background" 3 "Not Available or error" ;
VAL_ 2566904855 PopupIx_FFDC17 0 "Default Popup" 4095 "No Action, No Popup" ;
VAL_ 2566904855 IndActvSts 0 "Off" 1 "On" 2 "Error" 3 "Not Available" ;
VAL_ 2566904855 IndIx_FFDC17 0 "Default Indicator" 4095 "No Action, No Indicator" ;
VAL_ 2315191791 DeratingStatus 0 "no derating" 1 "derating" ;
VAL_ 2315191791 Direction 0 "Anti Clockwise" 1 "Clockwise" 2 "Synchro-Resolver Default" 3 "Not Available" ;
VAL_ 2583627762 CoastDwSts 0 "Deactive" 1 "Active" 2 "Error" 3 "Not Available" ;
VAL_ 2566894871 IAccMan_AutoCfg 0 "Off" 1 "Manual" 2 "Auto" 6 "Error" 7 "Not Available" ;
VAL_ 2566894871 IsaSpeedLimCfg 0 "Off" 1 "Manual" 2 "Automatic" 3 "Reserved1" 4 "Reserved2" 5 "Reserved3" 6 "Error" 7 "Not Available" ;
VAL_ 2566894871 IsaSwlfAcousticNotificationWarnC 0 "Off" 1 "On" 2 "Error" 3 "Not Available" ;
VAL_ 2566894871 IntelligentSpeedAssantCfg 0 "Off" 1 "On" 2 "Error" 3 "Not Available" ;
VAL_ 2566894871 IsaSwlfOpticWarnCfg 0 "Disable" 1 "Enable" 2 "Error" 3 "Not Available" ;
VAL_ 2566894871 IsaAcousticWarnCfg 0 "Disable" 1 "Enable" 2 "Error" 3 "Not Available" ;
VAL_ 2566894890 IsaSpeedLimOvr 0 "Not overspeeding" 1 "Overspeeding" 2 "Error" 3 "Not Available" ;
VAL_ 2566894890 TsaSts 0 "Not Initialized" 1 "Running" 2 "Temporary Error" 3 "Permanent Error" 4 "Success" 5 "Reduced Availability" 6 "Not Running" 7 "Not Used" ;
VAL_ 2566894890 IntelligentVehSpeedAssantSts 0 "Off" 1 "Manual Enable" 2 "Manual Proposed" 3 "Manual Active" 4 "Auto" 5 "Reserved1" 6 "Error" 7 "Not Available" ;
VAL_ 2566894890 SpeedUnit 0 "km/h" 1 "mph" 2 "Error" 3 "Not Available" ;
VAL_ 2566894890 IsaWarnType 0 "No Warning" 1 "Acoustic Warning" 2 "Invalid" 3 "Not Used" ;
VAL_ 2566894922 IAccMan_AutoCfg_FFB54A 0 "Off" 1 "Manual" 2 "Auto" 6 "Error" 7 "Not Available" ;
VAL_ 2566894922 IsaSpeedLimCfg_FFB54A 0 "Off" 1 "Manual" 2 "Automatic" 3 "Reserved1" 4 "Reserved2" 5 "Reserved3" 6 "Error" 7 "Not Available" ;
VAL_ 2566890538 WrongWayWarn 0 "Off" 1 "On" 2 "Error" 3 "Not available" ;
VAL_ 2566890538 SpeedLimWarn 0 "INACTIVE" 1 "ACTIVE" 2 "Error" 3 "Not Available" ;
VAL_ 2566890538 NoOverpassingWarn 0 "OFF (no warning)" 1 "ON (warning present)" 2 "Error" 3 "Not Available" ;
VAL_ 2566890538 GiveWayTypeOfEvt 0 "IDLE" 1 "STOP_SIGN" 2 "GW_SIGN" 3 "TRAFFIC_LIGHT" 4 "Reserved1" 5 "Reserved2" 6 "Error" 7 "Not Available/Invalid" ;
VAL_ 2566890538 NoOverpassingSts 0 "IDLE_NOPASSINGSTATUS" 1 "ALLOWED_NOPASSINGSTATUS" 2 "CANCEL_NOPASSINGSTATUS" 3 "FORBIDDEN_NOPASSINGSTATUS" 4 "INVALID_NOPASSINGSTATUS" 5 "reserved1" 6 "reserved2" 7 "reserved3" ;
VAL_ 2566890538 SpeedLimUnitless 0 "0" 1 "5" 2 "10" 3 "15" 4 "20" 5 "25" 6 "30" 7 "35" 8 "40" 9 "45" 10 "50" 11 "55" 12 "60" 13 "65" 14 "70" 15 "75" 16 "80" 17 "85" 18 "90" 19 "95" 20 "100" 21 "105" 22 "110" 23 "115" 24 "120" 25 "125" 26 "130" 27 "No Speed Limit Detected" 28 "140" 29 "res" 30 "Error" 31 "Not available" ;
VAL_ 2566890538 SupplSignInfo 0 "Idle" 1 "UnLim" 2 "Icy" 3 "Fog" 4 "Wet" 5 "Time" 6 "Dark" 7 "Ext_Left" 8 "Ext_Rgt" 9 "Trailer" 10 "Restricted" 11 "Rain" 12 "Truck" 13 "Car" 15 "Invalid" ;
VAL_ 2566890538 TrafficSignType 0 "NO_LIMIT" 1 "LIMIT_VALID" 2 "LIMIT_VALID_END" 3 "CITY_STRT" 4 "CITY_END" 5 "PLAYSTREET_START" 6 "PLAYSTREET_END" 7 "MOTOWAY_START" 8 "MOTOWAY_END" 9 "HIGHWAY_START" 10 "HIGHWAY_END" 11 "Reserved1" 12 "Reserved2" 13 "Reserved3" 14 "Error" 15 "Not Available" ;
VAL_ 2566852119 QaMode 0 "Disabled" 1 "Enabled" 2 "Enabled and active" 3 "Active with driver's override" 4 "Reserved1" 5 "Reserved2" 6 "Error Indicator" 7 "Not Available / Do not change" ;
VAL_ 2566852119 LkaStr 0 "Low" 1 "Medium" 2 "High" 7 "Not Available / Do not change" ;
VAL_ 2566852119 LaneSensDist 0 "Early" 1 "Medium" 2 "Late" 7 "Not Available / Do not change" ;
VAL_ 2566852119 LatCtrlFunctsAudioMute 0 "Off" 1 "On" 2 "Error" 3 "Not available" ;
VAL_ 2566852119 Lca 0 "Off" 1 "On" 2 "Error Indicator" 3 "Not Available / Do not change" ;
VAL_ 2566852119 Lka 0 "Off" 1 "On" 2 "Error Indicator" 3 "Not Available / Do not change" ;
VAL_ 2566852119 AccOvertakePrev 0 "Off" 1 "On" 2 "Error" 3 "Not Available" ;
VAL_ 2566852119 ParkBrkAutoApply 0 "Off" 1 "On" 2 "Error condition" 3 "Not Available" ;
VAL_ 2566852119 ParkBrkDrivAw 0 "Off" 1 "On" 2 "Error condition" 3 "Not Available" ;
VAL_ 2566852129 Hdc_FF0E21 0 "Off" 1 "Enable" 2 "Active" 6 "Error Indicator" 7 "Not Available / Do not change" ;
VAL_ 2566852129 LatCtrlFunctsAudioMute_FF0E21 0 "Off" 1 "On" 2 "Error" 3 "Not available" ;
VAL_ 2566852129 PwrSteerCityMode 0 "Off" 1 "On" 2 "Error Indicator" 3 "Not Available / Do not change" ;
VAL_ 2566852138 LcaIntervRh 0 "No Intervention" 1 "Intervention" 2 "Error" 3 "Not Available" ;
VAL_ 2566852138 LcaIntervLh 0 "No Intervention" 1 "Intervention" 2 "Error" 3 "Not Available" ;
VAL_ 2566852138 LkaSysSts 0 "Not ready" 1 "Temporarily not available" 2 "Deactivated by driver" 3 "Ready (no warnings active)" 4 "Suppressed by operator behavior" 5 "LKA intervention" 6 "Reserved1" 7 "Reserved2" 8 "Reserved3" 9 "Reserved4" 10 "Reserved5" 11 "Reserved6" 12 "Reserved7" 13 "Reserved8" 14 "Error" 15 "Not Available" ;
VAL_ 2566852138 LkaIntervRh 0 "No Intervention" 1 "Intervention" 2 "Acoustic Warning" 3 "Not Available" ;
VAL_ 2566852138 LkaIntervLh 0 "No Intervention" 1 "Intervention" 2 "Acoustic Warning" 3 "Not Available" ;
VAL_ 2566852138 LcaSysSts 0 "Not Coded" 1 "Off" 2 "Passive" 3 "Active" 4 "Rampout" 5 "Reserved" 6 "Error" 7 "Not Available/ Invalid" ;
VAL_ 2566852138 QaMode_FF0E2A 0 "Disabled" 1 "Enabled" 2 "Enabled and active" 3 "Active with driver's override" 4 "Reserved1" 5 "Reserved2" 6 "Error Indicator" 7 "Not Available / Do not change" ;
VAL_ 2566852138 TrafficJamAss 0 "Off" 1 "On" 2 "Error Indicator" 3 "Not Available / Do not change" ;
VAL_ 2566852138 Lca_FF0E2A 0 "Off" 1 "On" 2 "Error Indicator" 3 "Not Available / Do not change" ;
VAL_ 2566852138 Lka_FF0E2A 0 "Off" 1 "On" 2 "Error Indicator" 3 "Not Available / Do not change" ;
VAL_ 2566852138 Ldw 0 "Off" 1 "On" 2 "Error Indicator" 3 "Not Available / Do not change" ;
VAL_ 2566852138 AhbcTurnOffReas 0 "UNKNOWN_REASON" 1 "ONCOMING_TRAFFIC" 2 "PRECEEDING_TRAFFIC" 3 "LOW_SPEED" 4 "BRIGHTNESS" 5 "CITY" 6 "FOG" 7 "WEATHER" 8 "BLOCKAGE" 9 "DELAY" 10 "Not Used1" 11 "Not Used2" 12 "Not Used3" 13 "Not Used4" 14 "ERROR" 15 "INVALID/Not Available" ;
VAL_ 2566852138 AccOvertakePrev_FF0E2A 0 "Off" 1 "On" 2 "Error" 3 "Not Available" ;
VAL_ 2583664161 WndLifterRight 0 "Move up" 1 "Move down" 2 "Auto up" 3 "Auto down" 4 "Reserved" 5 "Reserved" 6 "Counter Alignment" 7 "Take no action" ;
VAL_ 2583664161 WndLifterLeft 0 "Move up" 1 "Move down" 2 "Auto up" 3 "Auto down" 4 "Reserved" 5 "Reserved" 6 "Counter Alignment" 7 "Take no action" ;
VAL_ 2583664161 Door5Lck_Unlck 0 "Unlock" 1 "Lock" 2 "Counter Alignment" 3 "Take no action" ;
VAL_ 2583664161 Door4Lck_Unlck 0 "Unlock" 1 "Lock" 2 "Counter Alignment" 3 "Take no action" ;
VAL_ 2583664161 Door3Lck_Unlck 0 "Unlock" 1 "Lock" 2 "Counter Alignment" 3 "Take no action" ;
VAL_ 2583664161 Door2Lck_Unlck 0 "Unlock" 1 "Lock" 2 "Counter Alignment" 3 "Take no action" ;
VAL_ 2583664161 Door1Lck_Unlck 0 "Unlock" 1 "Lock" 2 "Counter Alignment" 3 "Take no action" ;
VAL_ 2583664202 WndLifterRight_FF964A 0 "Move up" 1 "Move down" 2 "Auto up" 3 "Auto down" 4 "Reserved" 5 "Reserved" 6 "Counter Alignment" 7 "Take no action" ;
VAL_ 2583664202 WndLifterLeft_FF964A 0 "Move up" 1 "Move down" 2 "Auto up" 3 "Auto down" 4 "Reserved" 5 "Reserved" 6 "Counter Alignment" 7 "Take no action" ;
VAL_ 2583664202 Door5Lck_Unlck_FF964A 0 "Unlock" 1 "Lock" 2 "Counter Alignment" 3 "Take no action" ;
VAL_ 2583664202 Door4Lck_Unlck_FF964A 0 "Unlock" 1 "Lock" 2 "Counter Alignment" 3 "Take no action" ;
VAL_ 2583664202 Door3Lck_Unlck_FF964A 0 "Unlock" 1 "Lock" 2 "Counter Alignment" 3 "Take no action" ;
VAL_ 2583664202 Door2Lck_Unlck_FF964A 0 "Unlock" 1 "Lock" 2 "Counter Alignment" 3 "Take no action" ;
VAL_ 2583664202 Door1Lck_Unlck_FF964A 0 "Unlock" 1 "Lock" 2 "Counter Alignment" 3 "Take no action" ;
VAL_ 2583664417 CrkEnaReq 0 "Disable" 1 "Enable" 2 "Counter Alignment" 3 "Not Available" ;
VAL_ 2583664458 CrkEnaReq_FF974A 0 "Disable" 1 "Enable" 2 "Counter Alignment" 3 "Not Available" ;
VAL_ 2365579287 WakeupInDozeMode 0 "Off Command, No Request" 1 "On in Doze Mode Command/Request" 2 "Reserved" 3 "No Action" ;
VAL_ 2365579303 MsgCks_FE027 15 "Not Available, request honored" ;
VAL_ 2365579303 MsgCnt_FE027 8 "Reserved1" 9 "Reserved2" 10 "Reserved3" 11 "Reserved4" 12 "Reserved5" 13 "Reserved6" 14 "Reserved7" 15 "Not Available, request honored" ;
VAL_ 2365579303 WakeupBus 0 "Current data link" 1 "VDB Vehicle Data Bus" 2 "BCB Body Control Bus" 3 "ECB Engine Control Bus" 5 "FMS Bus" 6 "VDB Vehicle Data Bus on Frame" 7 "Body Builder Bus" 8 "Safety Bus" 10 "ISO 11992-2" 11 "ISO 11992-3" 15 "All busses" ;
VAL_ 2365579303 WakeupInDozeMode_FE027 0 "Off Command, No Request" 1 "On in Doze Mode Command/Request" 2 "Reserved" 3 "No Action" ;
VAL_ 2365579329 WakeupInDozeMode_FE041 0 "Off Command, No Request" 1 "On in Doze Mode Command/Request" 2 "Reserved" 3 "No Action" ;
VAL_ 2365579338 MsgCks_FE04A 15 "Not Available, request honored" ;
VAL_ 2365579338 MsgCnt_FE04A 8 "Reserved1" 9 "Reserved2" 10 "Reserved3" 11 "Reserved4" 12 "Reserved5" 13 "Reserved6" 14 "Reserved7" 15 "Not Available, request honored" ;
VAL_ 2365579338 WakeupInDozeMode_FE04A 0 "Off Command, No Request" 1 "On in Doze Mode Command/Request" 2 "Reserved" 3 "No Action" ;
VAL_ 2365579341 MsgCks_FE04D 15 "Not Available, request honored" ;
VAL_ 2365579341 MsgCnt_FE04D 8 "Reserved1" 9 "Reserved2" 10 "Reserved3" 11 "Reserved4" 12 "Reserved5" 13 "Reserved6" 14 "Reserved7" 15 "Not Available, request honored" ;
VAL_ 2365579341 BatMainSwHoldReq_FE04D 0 "Release Battery Main Switch" 1 "Hold Battery Main Switch" 2 "Undefined" 3 "Don�t Care / Take no action" ;
VAL_ 2365575713 MsgCks_FD221 15 "Not Available, request honored" ;
VAL_ 2365575713 MsgCnt_FD221 8 "Reserved1" 9 "Reserved2" 10 "Reserved3" 11 "Reserved4" 12 "Reserved5" 13 "Reserved6" 14 "Reserved7" 15 "Not Available, request honored" ;
VAL_ 2365575713 IgnBtnSts 0 "Pressed" 1 "Not Pressed" 2 "Error Indicator" 3 "Not Available" ;
VAL_ 2365575713 EngStarterSts 0 "Off" 1 "On" 2 "Error Indicator" 3 "Not Available" ;
VAL_ 2365575713 VehMov_FD221 0 "Off" 1 "On" 2 "Error Indicator" 3 "Not Available" ;
VAL_ 2365575713 EngRun 0 "Off" 1 "On" 2 "Error Indicator" 3 "Not Available" ;
VAL_ 2365575713 WakeupBus_FD221 0 "Current data link" 1 "VDB Vehicle Data Bus" 2 "BCB Body Control Bus" 3 "ECB Engine Control Bus" 5 "FMS Bus" 6 "VDB Vehicle Data Bus on Frame" 7 "Body Builder Bus" 8 "Safety Bus" 10 "ISO 11992-2" 11 "ISO 11992-3" 15 "All busses" ;
VAL_ 2365575713 IgnOn 0 "Off" 1 "On" 2 "Reserved" 3 "No Action" ;
VAL_ 2365575713 BatMainSwHoldSts 0 "Not held" 1 "Held" 2 "Reserved" 3 "Don�t Care / Take no action" ;
VAL_ 2365575713 WakeupInDozeMode_FD221 0 "Off Command, No Request" 1 "On in Doze Mode Command/Request" 2 "Reserved" 3 "No Action" ;
VAL_ 2365528587 WhThCntTs 65535 "Not Available" ;
VAL_ 2365528587 RaRThCnt 255 "Not Available" ;
VAL_ 2365528587 RaLThCnt 255 "Not Available" ;
VAL_ 2365528587 FaRThCnt 255 "Not Available" ;
VAL_ 2365528587 FaLThCnt 255 "Not Available" ;
VAL_ 2566858007 AudioMute 0 "Off" 1 "On" 2 "Toggle" 3 "Not Available / No Action" ;
VAL_ 2566858007 MutePrioReq 0 "No Request" 1 "Priority Lev 1" 2 "Priority Lev 2" 3 "Priority Lev 3" 4 "Priority Lev 4" 6 "Error" 7 "N.A." ;
VAL_ 2566858007 CallFromLogIx 0 "Off" 1 "Call Item 1" 2 "Call Item 2" 3 "Call Item 3" 4 "Call Item 4" 5 "Call Item 5" 6 "Call Item 6" 7 "Call Item 7" 8 "Call Item 8" 9 "Call Item 9" 10 "Call Item 10" 11 "Reserved" 12 "Reserved" 13 "Reserved" 14 "Error Indicator" 15 "Not Available" ;
VAL_ 2566858007 UnitSysSet 0 "Metric" 1 "Imperial" 2 "Custom" 3 "Not Used" ;
VAL_ 2566858007 DevIx_FF2517 0 "Device 1" 1 "Device 2" 2 "Error" 3 "No Device Connected" ;
VAL_ 2566858017 AudioMute_FF2521 0 "Off" 1 "On" 2 "Toggle" 3 "Not Available / No Action" ;
VAL_ 2566858017 Track_RadioUp_Dw 0 "Down" 1 "Up" 2 "Reserved" 3 "No Action" ;
VAL_ 2566858017 SrcUp_Dw 0 "Down" 1 "Up" 2 "Reserved" 3 "No Action" ;
VAL_ 2566858017 VoiceRec 0 "Off" 1 "On" 2 "Reserved" 3 "No Action" ;
VAL_ 2566858017 PhoneCallCmd 0 "Reject/End" 1 "Accept/Start" 2 "Reserved" 3 "No Action" ;
VAL_ 2566858017 ReqInc_DecVol 0 "No Action" 1 "Increment" 2 "Decrement" 3 "No Action" ;
VAL_ 2566858058 AudioMute_FF254A 0 "Off" 1 "On" 2 "Toggle" 3 "Not Available / No Action" ;
VAL_ 2566858058 ActvVideoSrc 0 "Off" 1 "Camera 1" 2 "Camera 2" 3 "Camera 3" 4 "Camera 4" 5 "Camera 5" 7 "Not Available / No request" ;
VAL_ 2566858058 Track_RadioUp_Dw_FF254A 0 "Down" 1 "Up" 2 "Reserved" 3 "No Action" ;
VAL_ 2566858058 SrcUp_Dw_FF254A 0 "Down" 1 "Up" 2 "Reserved" 3 "No Action" ;
VAL_ 2566858058 HtmlPageMode 0 "Off" 1 "Foreground" 2 "Background" 3 "Not Available / Do not change" ;
VAL_ 2566858058 ReqInc_DecVol_FF254A 0 "No Action" 1 "Increment" 2 "Decrement" 3 "No Action" ;
VAL_ 2566858058 RadioOn_Off 0 "Off" 1 "On" 2 "Fast Boot WiFi" 3 "Fast Boot Browser" ;
VAL_ 2566897729 DevIx_FFC041 0 "Device 1" 1 "Device 2" 2 "Error" 3 "No Device Connected" ;
VAL_ 2566857793 DevIx_FF2441 0 "Device 1" 1 "Device 2" 2 "Error" 3 "No Device Connected" ;
VAL_ 2566857793 ActvVideoSrc_FF2441 0 "Off" 1 "Camera 1" 2 "Camera 2" 3 "Camera 3" 4 "Camera 4" 5 "Camera 5" 7 "Not Available / No request" ;
VAL_ 2566857793 HtmlPageMode_FF2441 0 "Off" 1 "Foreground" 2 "Background" 3 "Not Available / Do not change" ;
VAL_ 2566857793 AudioMute_FF2441 0 "Off" 1 "On" 2 "Toggle" 3 "Not Available / No Action" ;
VAL_ 2566857793 ActvSrcEx 0 "Device Off" 1 "Tape" 2 "CD" 3 "CDC" 4 "Radio FM1" 5 "Radio FM2" 6 "Radio FMT" 7 "Radio MW" 8 "Radio LW" 9 "Radio DAB" 10 "USB" 11 "Memory Card" 12 "A2DP" 13 "Aux" 14 "Radio Sat" 15 "USB2" 17 "Radio MW2" 18 "Radio MW3" 19 "Radio LW2" 20 "Radio LW3" 21 "Radio DAB2" 22 "Radio DAB3" 23 "Radio Sat2" 24 "Radio Sat3" 25 "Apple CarPlay" 32 "Android Auto" 33 "Alexa" 34 "A2DP2" 35 "FM/DAB" 36 "HFP1" 37 "HFP2" 63 "Not Available" ;
VAL_ 2566857793 RadioDotDis 0 "Off" 1 "On" ;
VAL_ 2566857793 RadioColonDis 0 "Off" 1 "On" ;
VAL_ 2566857793 PhoneCallIn_Out 0 "No Call" 1 "Incoming Call" 2 "Outcoming Call" 3 "Not Available" ;
VAL_ 2566857793 PhoneCallHeld 0 "No Held Call" 1 "At least 1 Held Call" 2 "Reservedl" 3 "Not Available" ;
VAL_ 2566857793 PhoneCallActv 0 "No Active Call" 1 "At least 1 Active Call" 2 "Reserved" 3 "Not Available" ;
VAL_ 2566857793 Mix 0 "Off" 1 "On" ;
VAL_ 2566857793 Rpt 0 "Off" 1 "On" ;
VAL_ 2566857793 UnitSysSet_FF2441 0 "Metric" 1 "Imperial" 2 "Custom" 3 "Not Used" ;
VAL_ 2566857793 CdSym 0 "Off" 1 "On" ;
VAL_ 2566857793 MsgSts 0 "No Unopened Messages" 1 "At least 1 Unopened message" 2 "Message Memory Full" 3 "Not Available" ;
VAL_ 2566857793 AudioPause 0 "Off" 1 "On" 2 "Reserved" 3 "Not Available / No Action" ;
VAL_ 2566857793 ManSymLoudnessOn 0 "Off" 1 "On" ;
VAL_ 2566857793 LoSym 0 "Off" 1 "On" ;
VAL_ 2566857793 AfSym 0 "Off" 1 "On" ;
VAL_ 2566857793 TaSym 0 "Off" 1 "On" ;
VAL_ 2566857793 DevMic 0 "Off" 1 "On" 2 "Reserved" 3 "Not Available / No Action" ;
VAL_ 2566857793 InfotainmentSysSts 0 "FULLY_ON_KeyOn" 1 "FULLY_ON_KeyOn_Dark" 2 "DOZE_KeyOn" 3 "FULLY_ON_RVC" 4 "FULLY_ON_KeyOff" 5 "FULLY_ON_KeyOff_Dark" 6 "DOZE_KeyOff" 7 "SW_Update" ;
VAL_ 2566857793 FmISym 0 "Off" 1 "On" ;
VAL_ 2583662631 ChgSts 0 "Off" 1 "On" 2 "Suspended" 3 "Complete" 6 "Error" 7 "Not Available" ;
VAL_ 2583662631 SchedChgAuth 0 "No Action" 1 "Authorization Requested" 2 "Authorization Confirmed" 3 "Authorization Not Confirmed" 4 "Reserved" 6 "Error" 7 "Not Available" ;
VAL_ 2583662631 ChgModeSel 0 "Public" 1 "Normal" 2 "Fast" 3 "Scheduled Public" 8 "Scheduled Normal" 9 "Scheduled Fast" 10 "Charging phase ended" 11 "Reserved" 14 "Error" 15 "Not Available/ No Action" ;
VAL_ 2583662666 SchedChgAuth_FF904A 0 "No Action" 1 "Authorization Requested" 2 "Authorization Confirmed" 3 "Authorization Not Confirmed" 4 "Reserved" 6 "Error" 7 "Not Available" ;
VAL_ 2583666250 ExtChgCurLineLim 254 "Error" 255 "Not Available/No Action" ;
VAL_ 2566910497 DeratingReq 0 "Not requested" 1 "Requested" 2 "Error" 3 "Not Available" ;
